VERSION ""

NS_ :

BS_:

BU_:

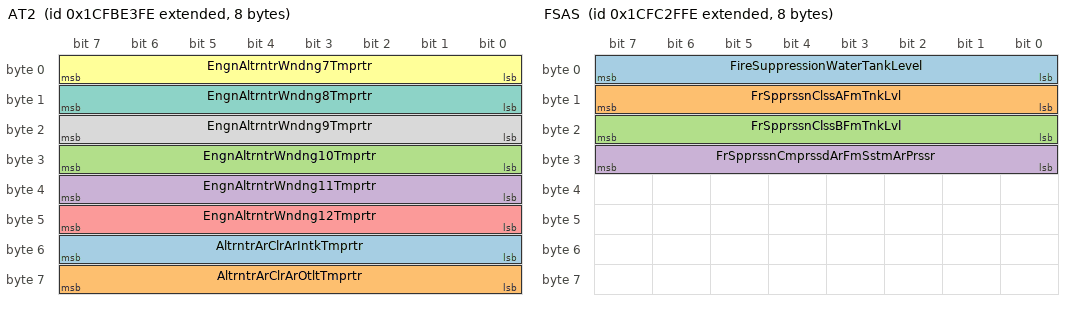
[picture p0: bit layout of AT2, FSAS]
BO_ 2633753598 AT2: 8 Vector__XXX
 SG_ AltrntrArClrArIntkTmprtr : 48|8@1+ (1,-40) [-40|210] "degC" Vector__XXX
 SG_ AltrntrArClrArOtltTmprtr : 56|8@1+ (1,-40) [-40|210] "degC" Vector__XXX
 SG_ EngnAltrntrWndng10Tmprtr : 24|8@1+ (1,-40) [-40|210] "degC" Vector__XXX
 SG_ EngnAltrntrWndng11Tmprtr : 32|8@1+ (1,-40) [-40|210] "degC" Vector__XXX
 SG_ EngnAltrntrWndng12Tmprtr : 40|8@1+ (1,-40) [-40|210] "degC" Vector__XXX
 SG_ EngnAltrntrWndng7Tmprtr : 0|8@1+ (1,-40) [-40|210] "degC" Vector__XXX
 SG_ EngnAltrntrWndng8Tmprtr : 8|8@1+ (1,-40) [-40|210] "degC" Vector__XXX
 SG_ EngnAltrntrWndng9Tmprtr : 16|8@1+ (1,-40) [-40|210] "degC" Vector__XXX

BO_ 2633754622 SCROII5: 8 Vector__XXX
 SG_ Aftrtrtmnt1SCRIntkHghTmprtrTm : 0|32@1+ (1,0) [0|4.21108E+09] "s" Vector__XXX
 SG_ SCROptIdtEOvdTtAtvtT : 32|32@1+ (1,0) [0|4.21108E+09] "s" Vector__XXX

BO_ 2633754878 ASI2: 8 Vector__XXX
 SG_ AftrtrtmntTtlDslExhstFldUsd : 0|32@1+ (0.5,0) [0|2105540607.5] "l" Vector__XXX

BO_ 2633755390 E1NET1: 19 Vector__XXX
 SG_ DefaultGatewayOctet1 : 72|8@1+ (1,0) [0|255] "count" Vector__XXX
 SG_ DefaultGatewayOctet2 : 80|8@1+ (1,0) [0|255] "count" Vector__XXX
 SG_ DefaultGatewayOctet3 : 88|8@1+ (1,0) [0|255] "count" Vector__XXX
 SG_ DefaultGatewayOctet4 : 96|8@1+ (1,0) [0|255] "count" Vector__XXX
 SG_ DHCPStatus : 0|4@1+ (1,0) [0|15] "" Vector__XXX
 SG_ EthernetLinkStatus : 4|2@1+ (1,0) [0|3] "" Vector__XXX
 SG_ IPv4AddressOctet1 : 8|8@1+ (1,0) [0|255] "count" Vector__XXX
 SG_ IPv4AddressOctet2 : 16|8@1+ (1,0) [0|255] "count" Vector__XXX
 SG_ IPv4AddressOctet3 : 24|8@1+ (1,0) [0|255] "count" Vector__XXX
 SG_ IPv4AddressOctet4 : 32|8@1+ (1,0) [0|255] "count" Vector__XXX
 SG_ MACAddressOctet1 : 104|8@1+ (1,0) [0|255] "count" Vector__XXX
 SG_ MACAddressOctet2 : 112|8@1+ (1,0) [0|255] "count" Vector__XXX
 SG_ MACAddressOctet3 : 120|8@1+ (1,0) [0|255] "count" Vector__XXX
 SG_ MACAddressOctet4 : 128|8@1+ (1,0) [0|255] "count" Vector__XXX
 SG_ MACAddressOctet5 : 136|8@1+ (1,0) [0|255] "count" Vector__XXX
 SG_ MACAddressOctet6 : 144|8@1+ (1,0) [0|255] "count" Vector__XXX
 SG_ SubnetMaskOctet1 : 40|8@1+ (1,0) [0|255] "count" Vector__XXX
 SG_ SubnetMaskOctet2 : 48|8@1+ (1,0) [0|255] "count" Vector__XXX
 SG_ SubnetMaskOctet3 : 56|8@1+ (1,0) [0|255] "count" Vector__XXX
 SG_ SubnetMaskOctet4 : 64|8@1+ (1,0) [0|255] "count" Vector__XXX

BO_ 2633764094 EVAP: 4 Vector__XXX
 SG_ CanisterPurgeValveCommand : 8|8@1+ (0.4,0) [0|100] "%" Vector__XXX
 SG_ CanisterVentValve : 0|2@1+ (1,0) [0|3] "" Vector__XXX
 SG_ GasolineFuelTankPressure : 16|16@1+ (0.1,-3212.7) [-3212.7|3212.8] "kPa" Vector__XXX

BO_ 2633764350 FPS1: 8 Vector__XXX
 SG_ FirePumpEngagementCycles : 32|16@1+ (1,0) [0|64255] "count" Vector__XXX
 SG_ FirePumpOperationTime : 0|32@1+ (1,0) [0|4.21108E+09] "s" Vector__XXX

BO_ 2633769726 EEC19: 8 Vector__XXX
 SG_ EngnExhstFlwRtExtnddRng : 32|32@1+ (0.001,0) [0|4211081.215] "kg/h" Vector__XXX
 SG_ TotalEngineEnergy : 0|32@1+ (1,0) [0|4.21108E+09] "kWh" Vector__XXX

BO_ 2633773054 FSAS: 8 Vector__XXX
 SG_ FireSuppressionWaterTankLevel : 0|8@1+ (0.4,0) [0|100] "%" Vector__XXX
 SG_ FrSpprssnClssAFmTnkLvl : 8|8@1+ (0.4,0) [0|100] "%" Vector__XXX
 SG_ FrSpprssnClssBFmTnkLvl : 16|8@1+ (0.4,0) [0|100] "%" Vector__XXX
 SG_ FrSpprssnCmprssdArFmSstmArPrssr : 24|8@1+ (8,0) [0|2000] "kPa" Vector__XXX

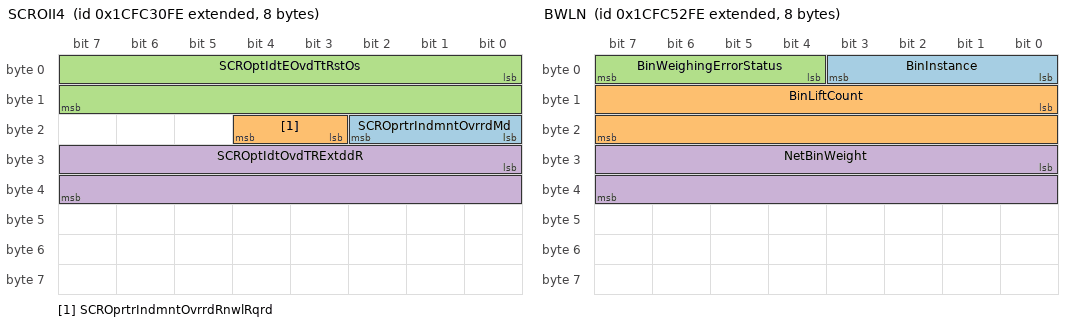
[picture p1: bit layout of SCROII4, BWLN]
BO_ 2633773310 SCROII4: 8 Vector__XXX
 SG_ SCROprtrIndmntOvrrdMd : 16|3@1+ (1,0) [0|7] "" Vector__XXX
 SG_ SCROprtrIndmntOvrrdRnwlRqrd : 19|2@1+ (1,0) [0|3] "" Vector__XXX
 SG_ SCROptIdtEOvdTtRstOs : 0|16@1+ (1,0) [0|64255] "count" Vector__XXX
 SG_ SCROptIdtOvdTRExtddR : 24|16@1+ (1,0) [0|64255] "min" Vector__XXX

BO_ 2633782014 BWLN: 8 Vector__XXX
 SG_ BinInstance : 0|4@1+ (1,0) [0|15] "count" Vector__XXX
 SG_ BinLiftCount : 8|16@1+ (1,0) [0|64255] "count" Vector__XXX
 SG_ BinWeighingErrorStatus : 4|4@1+ (1,0) [0|15] "" Vector__XXX
 SG_ NetBinWeight : 24|16@1+ (2,0) [0|128510] "kg" Vector__XXX

BO_ 2633785086 HVES1HIST: 11 Vector__XXX
 SG_ HVES1CnttrOpnUndrLdCnt : 8|16@1+ (1,0) [0|64255] "count" Vector__XXX
 SG_ HVES1StateofHealth : 0|8@1+ (0.4,0) [0|100] "%" Vector__XXX
 SG_ HVES1TotalAccumulatedCharge : 56|32@1+ (100,0) [0|4E+11] "Ah" Vector__XXX
 SG_ HVES1TotalEnergyThroughput : 24|32@1+ (100,0) [0|4E+11] "Watt-hour" Vector__XXX

BO_ 2633801982 MFEH: 8 Vector__XXX
 SG_ EngnTtlHrsfDslFlOprtn : 32|32@1+ (0.05,0) [0|210554060.75] "h" Vector__XXX
 SG_ EngnTtlHrsfGssFlOprtn : 0|32@1+ (0.05,0) [0|210554060.75] "h" Vector__XXX

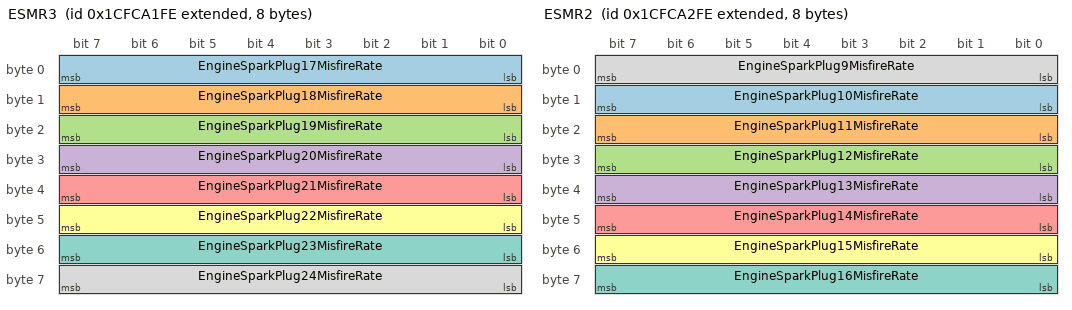
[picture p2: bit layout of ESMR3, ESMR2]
BO_ 2633802238 ESMR3: 8 Vector__XXX
 SG_ EngineSparkPlug17MisfireRate : 0|8@1+ (0.4,0) [0|100] "%" Vector__XXX
 SG_ EngineSparkPlug18MisfireRate : 8|8@1+ (0.4,0) [0|100] "%" Vector__XXX
 SG_ EngineSparkPlug19MisfireRate : 16|8@1+ (0.4,0) [0|100] "%" Vector__XXX
 SG_ EngineSparkPlug20MisfireRate : 24|8@1+ (0.4,0) [0|100] "%" Vector__XXX
 SG_ EngineSparkPlug21MisfireRate : 32|8@1+ (0.4,0) [0|100] "%" Vector__XXX
 SG_ EngineSparkPlug22MisfireRate : 40|8@1+ (0.4,0) [0|100] "%" Vector__XXX
 SG_ EngineSparkPlug23MisfireRate : 48|8@1+ (0.4,0) [0|100] "%" Vector__XXX
 SG_ EngineSparkPlug24MisfireRate : 56|8@1+ (0.4,0) [0|100] "%" Vector__XXX

BO_ 2633802494 ESMR2: 8 Vector__XXX
 SG_ EngineSparkPlug10MisfireRate : 8|8@1+ (0.4,0) [0|100] "%" Vector__XXX
 SG_ EngineSparkPlug11MisfireRate : 16|8@1+ (0.4,0) [0|100] "%" Vector__XXX
 SG_ EngineSparkPlug12MisfireRate : 24|8@1+ (0.4,0) [0|100] "%" Vector__XXX
 SG_ EngineSparkPlug13MisfireRate : 32|8@1+ (0.4,0) [0|100] "%" Vector__XXX
 SG_ EngineSparkPlug14MisfireRate : 40|8@1+ (0.4,0) [0|100] "%" Vector__XXX
 SG_ EngineSparkPlug15MisfireRate : 48|8@1+ (0.4,0) [0|100] "%" Vector__XXX
 SG_ EngineSparkPlug16MisfireRate : 56|8@1+ (0.4,0) [0|100] "%" Vector__XXX
 SG_ EngineSparkPlug9MisfireRate : 0|8@1+ (0.4,0) [0|100] "%" Vector__XXX

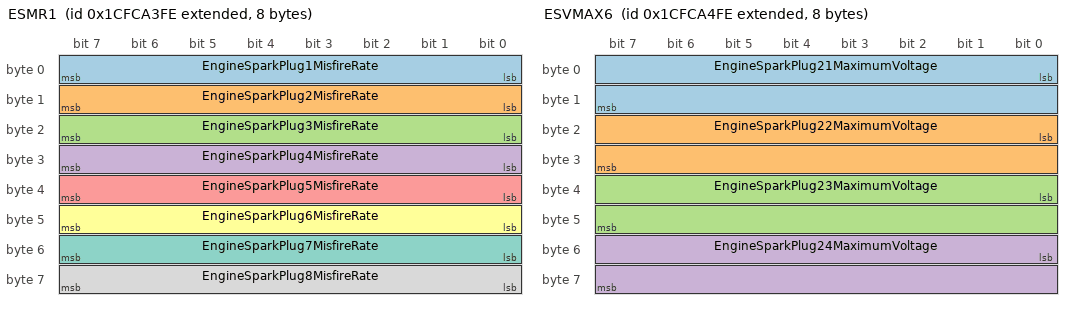
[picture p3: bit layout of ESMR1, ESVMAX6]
BO_ 2633802750 ESMR1: 8 Vector__XXX
 SG_ EngineSparkPlug1MisfireRate : 0|8@1+ (0.4,0) [0|100] "%" Vector__XXX
 SG_ EngineSparkPlug2MisfireRate : 8|8@1+ (0.4,0) [0|100] "%" Vector__XXX
 SG_ EngineSparkPlug3MisfireRate : 16|8@1+ (0.4,0) [0|100] "%" Vector__XXX
 SG_ EngineSparkPlug4MisfireRate : 24|8@1+ (0.4,0) [0|100] "%" Vector__XXX
 SG_ EngineSparkPlug5MisfireRate : 32|8@1+ (0.4,0) [0|100] "%" Vector__XXX
 SG_ EngineSparkPlug6MisfireRate : 40|8@1+ (0.4,0) [0|100] "%" Vector__XXX
 SG_ EngineSparkPlug7MisfireRate : 48|8@1+ (0.4,0) [0|100] "%" Vector__XXX
 SG_ EngineSparkPlug8MisfireRate : 56|8@1+ (0.4,0) [0|100] "%" Vector__XXX

BO_ 2633803006 ESVMAX6: 8 Vector__XXX
 SG_ EngineSparkPlug21MaximumVoltage : 0|16@1+ (1,0) [0|64255] "V" Vector__XXX
 SG_ EngineSparkPlug22MaximumVoltage : 16|16@1+ (1,0) [0|64255] "V" Vector__XXX
 SG_ EngineSparkPlug23MaximumVoltage : 32|16@1+ (1,0) [0|64255] "V" Vector__XXX
 SG_ EngineSparkPlug24MaximumVoltage : 48|16@1+ (1,0) [0|64255] "V" Vector__XXX

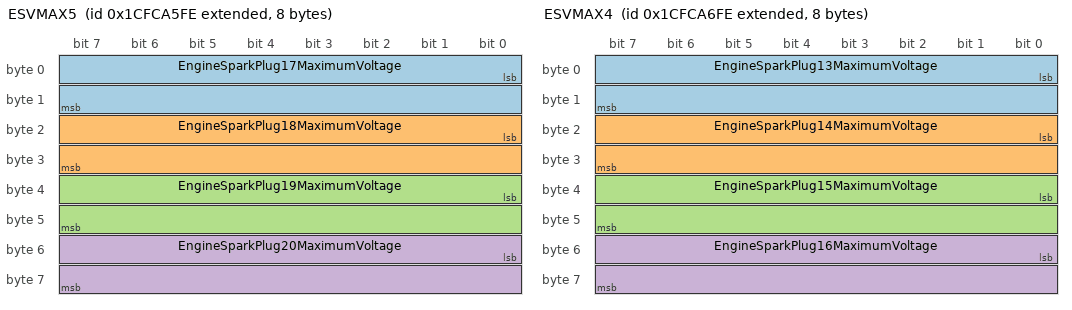
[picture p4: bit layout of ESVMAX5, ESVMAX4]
BO_ 2633803262 ESVMAX5: 8 Vector__XXX
 SG_ EngineSparkPlug17MaximumVoltage : 0|16@1+ (1,0) [0|64255] "V" Vector__XXX
 SG_ EngineSparkPlug18MaximumVoltage : 16|16@1+ (1,0) [0|64255] "V" Vector__XXX
 SG_ EngineSparkPlug19MaximumVoltage : 32|16@1+ (1,0) [0|64255] "V" Vector__XXX
 SG_ EngineSparkPlug20MaximumVoltage : 48|16@1+ (1,0) [0|64255] "V" Vector__XXX

BO_ 2633803518 ESVMAX4: 8 Vector__XXX
 SG_ EngineSparkPlug13MaximumVoltage : 0|16@1+ (1,0) [0|64255] "V" Vector__XXX
 SG_ EngineSparkPlug14MaximumVoltage : 16|16@1+ (1,0) [0|64255] "V" Vector__XXX
 SG_ EngineSparkPlug15MaximumVoltage : 32|16@1+ (1,0) [0|64255] "V" Vector__XXX
 SG_ EngineSparkPlug16MaximumVoltage : 48|16@1+ (1,0) [0|64255] "V" Vector__XXX

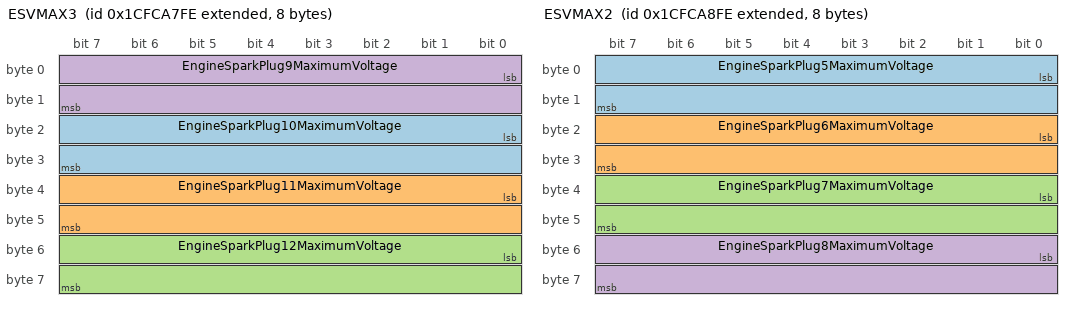
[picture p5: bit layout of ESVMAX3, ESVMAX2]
BO_ 2633803774 ESVMAX3: 8 Vector__XXX
 SG_ EngineSparkPlug10MaximumVoltage : 16|16@1+ (1,0) [0|64255] "V" Vector__XXX
 SG_ EngineSparkPlug11MaximumVoltage : 32|16@1+ (1,0) [0|64255] "V" Vector__XXX
 SG_ EngineSparkPlug12MaximumVoltage : 48|16@1+ (1,0) [0|64255] "V" Vector__XXX
 SG_ EngineSparkPlug9MaximumVoltage : 0|16@1+ (1,0) [0|64255] "V" Vector__XXX

BO_ 2633804030 ESVMAX2: 8 Vector__XXX
 SG_ EngineSparkPlug5MaximumVoltage : 0|16@1+ (1,0) [0|64255] "V" Vector__XXX
 SG_ EngineSparkPlug6MaximumVoltage : 16|16@1+ (1,0) [0|64255] "V" Vector__XXX
 SG_ EngineSparkPlug7MaximumVoltage : 32|16@1+ (1,0) [0|64255] "V" Vector__XXX
 SG_ EngineSparkPlug8MaximumVoltage : 48|16@1+ (1,0) [0|64255] "V" Vector__XXX

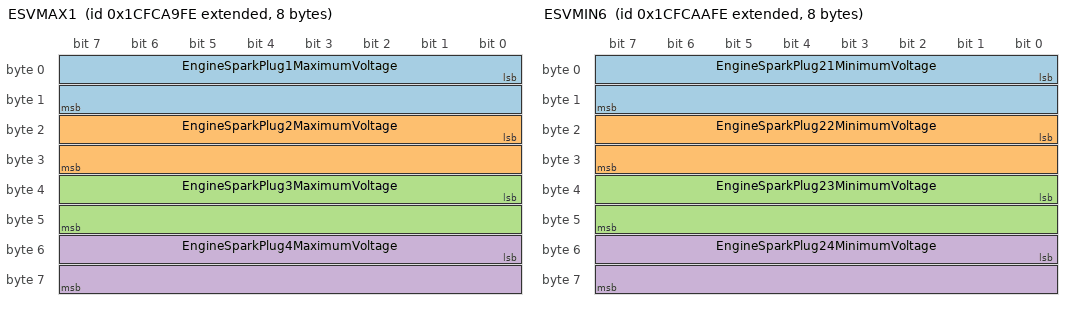
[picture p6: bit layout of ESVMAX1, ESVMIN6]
BO_ 2633804286 ESVMAX1: 8 Vector__XXX
 SG_ EngineSparkPlug1MaximumVoltage : 0|16@1+ (1,0) [0|64255] "V" Vector__XXX
 SG_ EngineSparkPlug2MaximumVoltage : 16|16@1+ (1,0) [0|64255] "V" Vector__XXX
 SG_ EngineSparkPlug3MaximumVoltage : 32|16@1+ (1,0) [0|64255] "V" Vector__XXX
 SG_ EngineSparkPlug4MaximumVoltage : 48|16@1+ (1,0) [0|64255] "V" Vector__XXX

BO_ 2633804542 ESVMIN6: 8 Vector__XXX
 SG_ EngineSparkPlug21MinimumVoltage : 0|16@1+ (1,0) [0|64255] "V" Vector__XXX
 SG_ EngineSparkPlug22MinimumVoltage : 16|16@1+ (1,0) [0|64255] "V" Vector__XXX
 SG_ EngineSparkPlug23MinimumVoltage : 32|16@1+ (1,0) [0|64255] "V" Vector__XXX
 SG_ EngineSparkPlug24MinimumVoltage : 48|16@1+ (1,0) [0|64255] "V" Vector__XXX

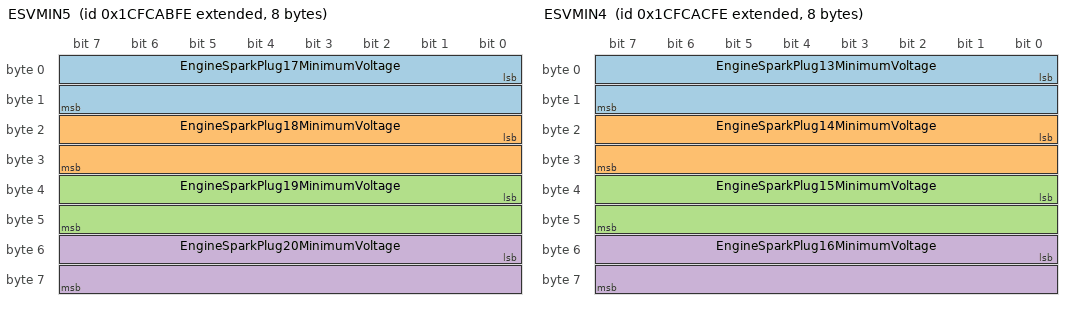
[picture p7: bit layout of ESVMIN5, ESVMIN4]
BO_ 2633804798 ESVMIN5: 8 Vector__XXX
 SG_ EngineSparkPlug17MinimumVoltage : 0|16@1+ (1,0) [0|64255] "V" Vector__XXX
 SG_ EngineSparkPlug18MinimumVoltage : 16|16@1+ (1,0) [0|64255] "V" Vector__XXX
 SG_ EngineSparkPlug19MinimumVoltage : 32|16@1+ (1,0) [0|64255] "V" Vector__XXX
 SG_ EngineSparkPlug20MinimumVoltage : 48|16@1+ (1,0) [0|64255] "V" Vector__XXX

BO_ 2633805054 ESVMIN4: 8 Vector__XXX
 SG_ EngineSparkPlug13MinimumVoltage : 0|16@1+ (1,0) [0|64255] "V" Vector__XXX
 SG_ EngineSparkPlug14MinimumVoltage : 16|16@1+ (1,0) [0|64255] "V" Vector__XXX
 SG_ EngineSparkPlug15MinimumVoltage : 32|16@1+ (1,0) [0|64255] "V" Vector__XXX
 SG_ EngineSparkPlug16MinimumVoltage : 48|16@1+ (1,0) [0|64255] "V" Vector__XXX

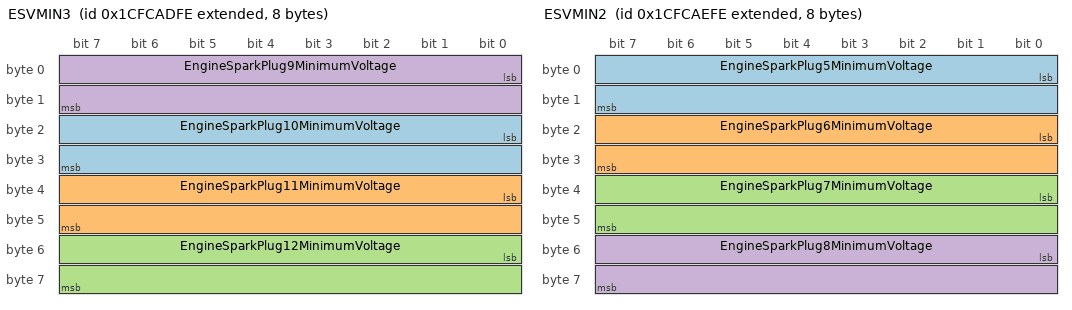
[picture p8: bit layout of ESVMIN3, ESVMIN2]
BO_ 2633805310 ESVMIN3: 8 Vector__XXX
 SG_ EngineSparkPlug10MinimumVoltage : 16|16@1+ (1,0) [0|64255] "V" Vector__XXX
 SG_ EngineSparkPlug11MinimumVoltage : 32|16@1+ (1,0) [0|64255] "V" Vector__XXX
 SG_ EngineSparkPlug12MinimumVoltage : 48|16@1+ (1,0) [0|64255] "V" Vector__XXX
 SG_ EngineSparkPlug9MinimumVoltage : 0|16@1+ (1,0) [0|64255] "V" Vector__XXX

BO_ 2633805566 ESVMIN2: 8 Vector__XXX
 SG_ EngineSparkPlug5MinimumVoltage : 0|16@1+ (1,0) [0|64255] "V" Vector__XXX
 SG_ EngineSparkPlug6MinimumVoltage : 16|16@1+ (1,0) [0|64255] "V" Vector__XXX
 SG_ EngineSparkPlug7MinimumVoltage : 32|16@1+ (1,0) [0|64255] "V" Vector__XXX
 SG_ EngineSparkPlug8MinimumVoltage : 48|16@1+ (1,0) [0|64255] "V" Vector__XXX

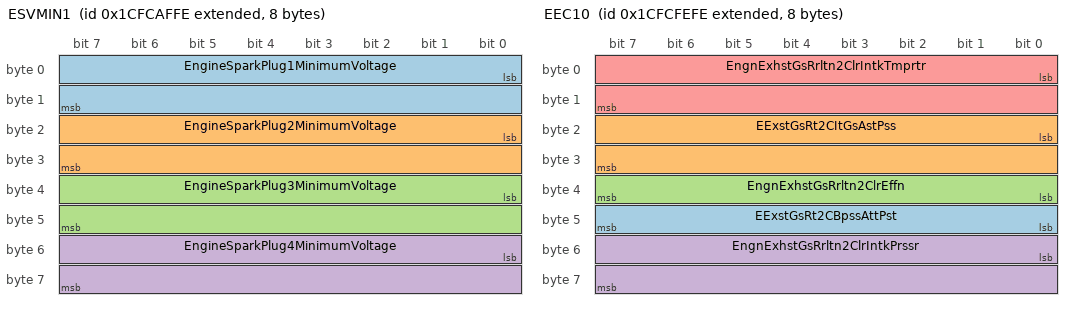
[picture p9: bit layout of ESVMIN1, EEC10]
BO_ 2633805822 ESVMIN1: 8 Vector__XXX
 SG_ EngineSparkPlug1MinimumVoltage : 0|16@1+ (1,0) [0|64255] "V" Vector__XXX
 SG_ EngineSparkPlug2MinimumVoltage : 16|16@1+ (1,0) [0|64255] "V" Vector__XXX
 SG_ EngineSparkPlug3MinimumVoltage : 32|16@1+ (1,0) [0|64255] "V" Vector__XXX
 SG_ EngineSparkPlug4MinimumVoltage : 48|16@1+ (1,0) [0|64255] "V" Vector__XXX

BO_ 2633806078 EICMH: 8 Vector__XXX
 SG_ EngnIgntnCntrlMdl1TmRmnng : 0|32@1+ (0.05,0) [0|210554060.75] "h" Vector__XXX
 SG_ EngnIgntnCntrlMdl2TmRmnng : 32|32@1+ (0.05,0) [0|210554060.75] "h" Vector__XXX

BO_ 2633825022 EEC11: 8 Vector__XXX
 SG_ EngnExhstGsRrltn2Vlv1Cntrl : 0|16@1+ (0.0025,0) [0|160.6375] "%" Vector__XXX
 SG_ EngnExhstGsRrltn2Vlv1PstnErrr : 32|16@1+ (0.004,-125) [-125|132.02] "%" Vector__XXX
 SG_ EngnExhstGsRrltn2Vlv2Cntrl : 16|16@1+ (0.0025,0) [0|160.6375] "%" Vector__XXX
 SG_ EngnExhstGsRrltn2Vlv2PstnErrr : 48|16@1+ (0.004,-125) [-125|132.02] "%" Vector__XXX

BO_ 2633825534 EMAC: 8 Vector__XXX
 SG_ EExstMdB1FwBVvAttCt : 0|16@1+ (0.0025,0) [0|160.6375] "%" Vector__XXX
 SG_ EExstMdB2FwBVvAttCt : 16|16@1+ (0.0025,0) [0|160.6375] "%" Vector__XXX

BO_ 2633826046 EEC10: 8 Vector__XXX
 SG_ EExstGsRt2CBpssAttPst : 40|8@1+ (0.4,0) [0|100] "%" Vector__XXX
 SG_ EExstGsRt2CItGsAstPss : 16|16@1+ (0.5,0) [0|32127.5] "kPa" Vector__XXX
 SG_ EngnExhstGsRrltn2ClrEffn : 32|8@1+ (0.4,0) [0|100] "%" Vector__XXX
 SG_ EngnExhstGsRrltn2ClrIntkPrssr : 48|16@1+ (5,0) [0|321275] "kPa" Vector__XXX
 SG_ EngnExhstGsRrltn2ClrIntkTmprtr : 0|16@1+ (0.03125,-273) [-273|1734.96875] "degC" Vector__XXX

BO_ 2633828606 EOM: 8 Vector__XXX
 SG_ EngineOilDensity : 16|16@1+ (0.00003052,0) [0|1.961] "g/cc" Vector__XXX
 SG_ EngineOilTemperature3 : 48|16@1+ (0.03125,-273) [-273|1734.96875] "degC" Vector__XXX
 SG_ EngineOilViscosity : 0|16@1+ (0.015625,0) [0|1003.984375] "Cp" Vector__XXX
 SG_ EngnOlRltvDltrtHghRsltn : 32|16@1+ (0.0001220703125,0) [0|7.844] "" Vector__XXX

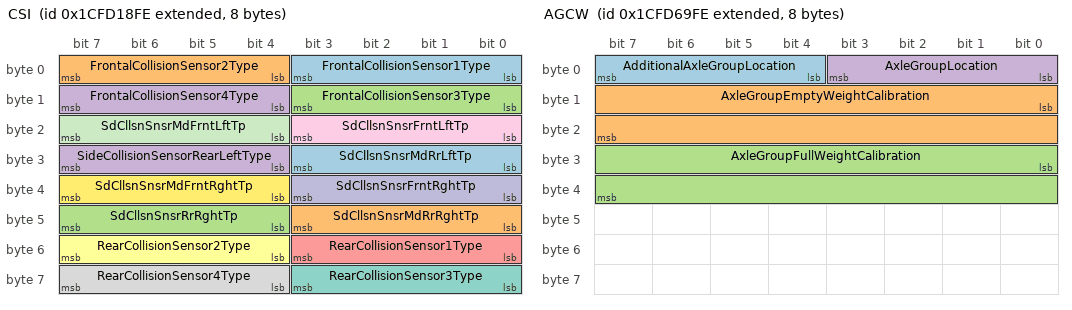
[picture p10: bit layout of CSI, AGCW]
BO_ 2633832702 CSI: 8 Vector__XXX
 SG_ FrontalCollisionSensor1Type : 0|4@1+ (1,0) [0|15] "" Vector__XXX
 SG_ FrontalCollisionSensor2Type : 4|4@1+ (1,0) [0|15] "" Vector__XXX
 SG_ FrontalCollisionSensor3Type : 8|4@1+ (1,0) [0|15] "" Vector__XXX
 SG_ FrontalCollisionSensor4Type : 12|4@1+ (1,0) [0|15] "" Vector__XXX
 SG_ RearCollisionSensor1Type : 48|4@1+ (1,0) [0|15] "" Vector__XXX
 SG_ RearCollisionSensor2Type : 52|4@1+ (1,0) [0|15] "" Vector__XXX
 SG_ RearCollisionSensor3Type : 56|4@1+ (1,0) [0|15] "" Vector__XXX
 SG_ RearCollisionSensor4Type : 60|4@1+ (1,0) [0|15] "" Vector__XXX
 SG_ SdCllsnSnsrFrntLftTp : 16|4@1+ (1,0) [0|15] "" Vector__XXX
 SG_ SdCllsnSnsrFrntRghtTp : 32|4@1+ (1,0) [0|15] "" Vector__XXX
 SG_ SdCllsnSnsrMdFrntLftTp : 20|4@1+ (1,0) [0|15] "" Vector__XXX
 SG_ SdCllsnSnsrMdFrntRghtTp : 36|4@1+ (1,0) [0|15] "" Vector__XXX
 SG_ SdCllsnSnsrMdRrLftTp : 24|4@1+ (1,0) [0|15] "" Vector__XXX
 SG_ SdCllsnSnsrMdRrRghtTp : 40|4@1+ (1,0) [0|15] "" Vector__XXX
 SG_ SdCllsnSnsrRrRghtTp : 44|4@1+ (1,0) [0|15] "" Vector__XXX
 SG_ SideCollisionSensorRearLeftType : 28|4@1+ (1,0) [0|15] "" Vector__XXX

BO_ 2633832958 ILI: 200 Vector__XXX
 SG_ DrvrArgIgntrLp1stStgRsstn : 0|16@1+ (0.1,0) [0|6425.5] "ohm" Vector__XXX
 SG_ DrvrArgIgntrLp2ndStgRsstn : 32|16@1+ (0.1,0) [0|6425.5] "ohm" Vector__XXX
 SG_ DrvrBltTnsnrIgntrLpRsstn : 64|16@1+ (0.1,0) [0|6425.5] "ohm" Vector__XXX
 SG_ PssngrArgIgntrLp1stStgRsstn : 16|16@1+ (0.1,0) [0|6425.5] "ohm" Vector__XXX
 SG_ PssngrArgIgntrLp2ndStgRsstn : 48|16@1+ (0.1,0) [0|6425.5] "ohm" Vector__XXX
 SG_ PssngrBltTnsnrIgntrLpRsstn : 80|16@1+ (0.1,0) [0|6425.5] "ohm" Vector__XXX
 SG_ SdBgIgntrLp1LftRsstn : 96|16@1+ (0.1,0) [0|6425.5] "ohm" Vector__XXX
 SG_ SdBgIgntrLp1RghtRsstn : 128|16@1+ (0.1,0) [0|6425.5] "ohm" Vector__XXX
 SG_ SdBgIgntrLp2LftRsstn : 112|16@1+ (0.1,0) [0|6425.5] "ohm" Vector__XXX
 SG_ SdBgIgntrLp2RghtRsstn : 144|16@1+ (0.1,0) [0|6425.5] "ohm" Vector__XXX
 SG_ SpecialIgnitorLoop10Resistance : 304|16@1+ (0.1,0) [0|6425.5] "ohm" Vector__XXX
 SG_ SpecialIgnitorLoop11Resistance : 320|16@1+ (0.1,0) [0|6425.5] "ohm" Vector__XXX
 SG_ SpecialIgnitorLoop12Resistance : 336|16@1+ (0.1,0) [0|6425.5] "ohm" Vector__XXX
 SG_ SpecialIgnitorLoop13Resistance : 352|16@1+ (0.1,0) [0|6425.5] "ohm" Vector__XXX
 SG_ SpecialIgnitorLoop14Resistance : 368|16@1+ (0.1,0) [0|6425.5] "ohm" Vector__XXX
 SG_ SpecialIgnitorLoop15Resistance : 384|16@1+ (0.1,0) [0|6425.5] "ohm" Vector__XXX
 SG_ SpecialIgnitorLoop16Resistance : 400|16@1+ (0.1,0) [0|6425.5] "ohm" Vector__XXX
 SG_ SpecialIgnitorLoop17Resistance : 416|16@1+ (0.1,0) [0|6425.5] "ohm" Vector__XXX
 SG_ SpecialIgnitorLoop18Resistance : 432|16@1+ (0.1,0) [0|6425.5] "ohm" Vector__XXX
 SG_ SpecialIgnitorLoop19Resistance : 448|16@1+ (0.1,0) [0|6425.5] "ohm" Vector__XXX
 SG_ SpecialIgnitorLoop1Resistance : 160|16@1+ (0.1,0) [0|6425.5] "ohm" Vector__XXX
 SG_ SpecialIgnitorLoop20Resistance : 464|16@1+ (0.1,0) [0|6425.5] "ohm" Vector__XXX
 SG_ SpecialIgnitorLoop21Resistance : 480|16@1+ (0.1,0) [0|6425.5] "ohm" Vector__XXX
 SG_ SpecialIgnitorLoop22Resistance : 496|16@1+ (0.1,0) [0|6425.5] "ohm" Vector__XXX
 SG_ SpecialIgnitorLoop23Resistance : 512|16@1+ (0.1,0) [0|6425.5] "ohm" Vector__XXX
 SG_ SpecialIgnitorLoop24Resistance : 528|16@1+ (0.1,0) [0|6425.5] "ohm" Vector__XXX
 SG_ SpecialIgnitorLoop25Resistance : 544|16@1+ (0.1,0) [0|6425.5] "ohm" Vector__XXX
 SG_ SpecialIgnitorLoop26Resistance : 560|16@1+ (0.1,0) [0|6425.5] "ohm" Vector__XXX
 SG_ SpecialIgnitorLoop27Resistance : 576|16@1+ (0.1,0) [0|6425.5] "ohm" Vector__XXX
 SG_ SpecialIgnitorLoop28Resistance : 592|16@1+ (0.1,0) [0|6425.5] "ohm" Vector__XXX
 SG_ SpecialIgnitorLoop29Resistance : 608|16@1+ (0.1,0) [0|6425.5] "ohm" Vector__XXX
 SG_ SpecialIgnitorLoop2Resistance : 176|16@1+ (0.1,0) [0|6425.5] "ohm" Vector__XXX
 SG_ SpecialIgnitorLoop30Resistance : 624|16@1+ (0.1,0) [0|6425.5] "ohm" Vector__XXX
 SG_ SpecialIgnitorLoop31Resistance : 640|16@1+ (0.1,0) [0|6425.5] "ohm" Vector__XXX
 SG_ SpecialIgnitorLoop32Resistance : 656|16@1+ (0.1,0) [0|6425.5] "ohm" Vector__XXX
 SG_ SpecialIgnitorLoop33Resistance : 672|16@1+ (0.1,0) [0|6425.5] "ohm" Vector__XXX
 SG_ SpecialIgnitorLoop34Resistance : 688|16@1+ (0.1,0) [0|6425.5] "ohm" Vector__XXX
 SG_ SpecialIgnitorLoop35Resistance : 704|16@1+ (0.1,0) [0|6425.5] "ohm" Vector__XXX
 SG_ SpecialIgnitorLoop36Resistance : 720|16@1+ (0.1,0) [0|6425.5] "ohm" Vector__XXX
 SG_ SpecialIgnitorLoop37Resistance : 736|16@1+ (0.1,0) [0|6425.5] "ohm" Vector__XXX
 SG_ SpecialIgnitorLoop38Resistance : 752|16@1+ (0.1,0) [0|6425.5] "ohm" Vector__XXX
 SG_ SpecialIgnitorLoop39Resistance : 768|16@1+ (0.1,0) [0|6425.5] "ohm" Vector__XXX
 SG_ SpecialIgnitorLoop3Resistance : 192|16@1+ (0.1,0) [0|6425.5] "ohm" Vector__XXX
 SG_ SpecialIgnitorLoop40Resistance : 784|16@1+ (0.1,0) [0|6425.5] "ohm" Vector__XXX
 SG_ SpecialIgnitorLoop41Resistance : 800|16@1+ (0.1,0) [0|6425.5] "ohm" Vector__XXX
 SG_ SpecialIgnitorLoop42Resistance : 816|16@1+ (0.1,0) [0|6425.5] "ohm" Vector__XXX
 SG_ SpecialIgnitorLoop43Resistance : 832|16@1+ (0.1,0) [0|6425.5] "ohm" Vector__XXX
 SG_ SpecialIgnitorLoop44Resistance : 848|16@1+ (0.1,0) [0|6425.5] "ohm" Vector__XXX
 SG_ SpecialIgnitorLoop45Resistance : 864|16@1+ (0.1,0) [0|6425.5] "ohm" Vector__XXX
 SG_ SpecialIgnitorLoop46Resistance : 880|16@1+ (0.1,0) [0|6425.5] "ohm" Vector__XXX
 SG_ SpecialIgnitorLoop47Resistance : 896|16@1+ (0.1,0) [0|6425.5] "ohm" Vector__XXX
 SG_ SpecialIgnitorLoop48Resistance : 912|16@1+ (0.1,0) [0|6425.5] "ohm" Vector__XXX
 SG_ SpecialIgnitorLoop49Resistance : 928|16@1+ (0.1,0) [0|6425.5] "ohm" Vector__XXX
 SG_ SpecialIgnitorLoop4Resistance : 208|16@1+ (0.1,0) [0|6425.5] "ohm" Vector__XXX
 SG_ SpecialIgnitorLoop50Resistance : 944|16@1+ (0.1,0) [0|6425.5] "ohm" Vector__XXX
 SG_ SpecialIgnitorLoop51Resistance : 960|16@1+ (0.1,0) [0|6425.5] "ohm" Vector__XXX
 SG_ SpecialIgnitorLoop52Resistance : 976|16@1+ (0.1,0) [0|6425.5] "ohm" Vector__XXX
 SG_ SpecialIgnitorLoop53Resistance : 992|16@1+ (0.1,0) [0|6425.5] "ohm" Vector__XXX
 SG_ SpecialIgnitorLoop54Resistance : 1008|16@1+ (0.1,0) [0|6425.5] "ohm" Vector__XXX
 SG_ SpecialIgnitorLoop55Resistance : 1024|16@1+ (0.1,0) [0|6425.5] "ohm" Vector__XXX
 SG_ SpecialIgnitorLoop56Resistance : 1040|16@1+ (0.1,0) [0|6425.5] "ohm" Vector__XXX
 SG_ SpecialIgnitorLoop57Resistance : 1056|16@1+ (0.1,0) [0|6425.5] "ohm" Vector__XXX
 SG_ SpecialIgnitorLoop58Resistance : 1072|16@1+ (0.1,0) [0|6425.5] "ohm" Vector__XXX
 SG_ SpecialIgnitorLoop59Resistance : 1088|16@1+ (0.1,0) [0|6425.5] "ohm" Vector__XXX
 SG_ SpecialIgnitorLoop5Resistance : 224|16@1+ (0.1,0) [0|6425.5] "ohm" Vector__XXX
 SG_ SpecialIgnitorLoop60Resistance : 1104|16@1+ (0.1,0) [0|6425.5] "ohm" Vector__XXX
 SG_ SpecialIgnitorLoop61Resistance : 1120|16@1+ (0.1,0) [0|6425.5] "ohm" Vector__XXX
 SG_ SpecialIgnitorLoop62Resistance : 1136|16@1+ (0.1,0) [0|6425.5] "ohm" Vector__XXX
 SG_ SpecialIgnitorLoop63Resistance : 1152|16@1+ (0.1,0) [0|6425.5] "ohm" Vector__XXX
 SG_ SpecialIgnitorLoop64Resistance : 1168|16@1+ (0.1,0) [0|6425.5] "ohm" Vector__XXX
 SG_ SpecialIgnitorLoop65Resistance : 1184|16@1+ (0.1,0) [0|6425.5] "ohm" Vector__XXX
 SG_ SpecialIgnitorLoop66Resistance : 1200|16@1+ (0.1,0) [0|6425.5] "ohm" Vector__XXX
 SG_ SpecialIgnitorLoop67Resistance : 1216|16@1+ (0.1,0) [0|6425.5] "ohm" Vector__XXX
 SG_ SpecialIgnitorLoop68Resistance : 1232|16@1+ (0.1,0) [0|6425.5] "ohm" Vector__XXX
 SG_ SpecialIgnitorLoop69Resistance : 1248|16@1+ (0.1,0) [0|6425.5] "ohm" Vector__XXX
 SG_ SpecialIgnitorLoop6Resistance : 240|16@1+ (0.1,0) [0|6425.5] "ohm" Vector__XXX
 SG_ SpecialIgnitorLoop70Resistance : 1264|16@1+ (0.1,0) [0|6425.5] "ohm" Vector__XXX
 SG_ SpecialIgnitorLoop71Resistance : 1280|16@1+ (0.1,0) [0|6425.5] "ohm" Vector__XXX
 SG_ SpecialIgnitorLoop72Resistance : 1296|16@1+ (0.1,0) [0|6425.5] "ohm" Vector__XXX
 SG_ SpecialIgnitorLoop73Resistance : 1312|16@1+ (0.1,0) [0|6425.5] "ohm" Vector__XXX
 SG_ SpecialIgnitorLoop74Resistance : 1328|16@1+ (0.1,0) [0|6425.5] "ohm" Vector__XXX
 SG_ SpecialIgnitorLoop75Resistance : 1344|16@1+ (0.1,0) [0|6425.5] "ohm" Vector__XXX
 SG_ SpecialIgnitorLoop76Resistance : 1360|16@1+ (0.1,0) [0|6425.5] "ohm" Vector__XXX
 SG_ SpecialIgnitorLoop77Resistance : 1376|16@1+ (0.1,0) [0|6425.5] "ohm" Vector__XXX
 SG_ SpecialIgnitorLoop78Resistance : 1392|16@1+ (0.1,0) [0|6425.5] "ohm" Vector__XXX
 SG_ SpecialIgnitorLoop79Resistance : 1408|16@1+ (0.1,0) [0|6425.5] "ohm" Vector__XXX
 SG_ SpecialIgnitorLoop7Resistance : 256|16@1+ (0.1,0) [0|6425.5] "ohm" Vector__XXX
 SG_ SpecialIgnitorLoop80Resistance : 1424|16@1+ (0.1,0) [0|6425.5] "ohm" Vector__XXX
 SG_ SpecialIgnitorLoop81Resistance : 1440|16@1+ (0.1,0) [0|6425.5] "ohm" Vector__XXX
 SG_ SpecialIgnitorLoop82Resistance : 1456|16@1+ (0.1,0) [0|6425.5] "ohm" Vector__XXX
 SG_ SpecialIgnitorLoop83Resistance : 1472|16@1+ (0.1,0) [0|6425.5] "ohm" Vector__XXX
 SG_ SpecialIgnitorLoop84Resistance : 1488|16@1+ (0.1,0) [0|6425.5] "ohm" Vector__XXX
 SG_ SpecialIgnitorLoop85Resistance : 1504|16@1+ (0.1,0) [0|6425.5] "ohm" Vector__XXX
 SG_ SpecialIgnitorLoop86Resistance : 1520|16@1+ (0.1,0) [0|6425.5] "ohm" Vector__XXX
 SG_ SpecialIgnitorLoop87Resistance : 1536|16@1+ (0.1,0) [0|6425.5] "ohm" Vector__XXX
 SG_ SpecialIgnitorLoop88Resistance : 1552|16@1+ (0.1,0) [0|6425.5] "ohm" Vector__XXX
 SG_ SpecialIgnitorLoop89Resistance : 1568|16@1+ (0.1,0) [0|6425.5] "ohm" Vector__XXX
 SG_ SpecialIgnitorLoop8Resistance : 272|16@1+ (0.1,0) [0|6425.5] "ohm" Vector__XXX
 SG_ SpecialIgnitorLoop90Resistance : 1584|16@1+ (0.1,0) [0|6425.5] "ohm" Vector__XXX
 SG_ SpecialIgnitorLoop9Resistance : 288|16@1+ (0.1,0) [0|6425.5] "ohm" Vector__XXX

BO_ 2633853438 AGCW: 8 Vector__XXX
 SG_ AdditionalAxleGroupLocation : 4|4@1+ (1,0) [0|15] "" Vector__XXX
 SG_ AxleGroupEmptyWeightCalibration : 8|16@1+ (2,0) [0|128510] "kg" Vector__XXX
 SG_ AxleGroupFullWeightCalibration : 24|16@1+ (2,0) [0|128510] "kg" Vector__XXX
 SG_ AxleGroupLocation : 0|4@1+ (1,0) [0|15] "" Vector__XXX

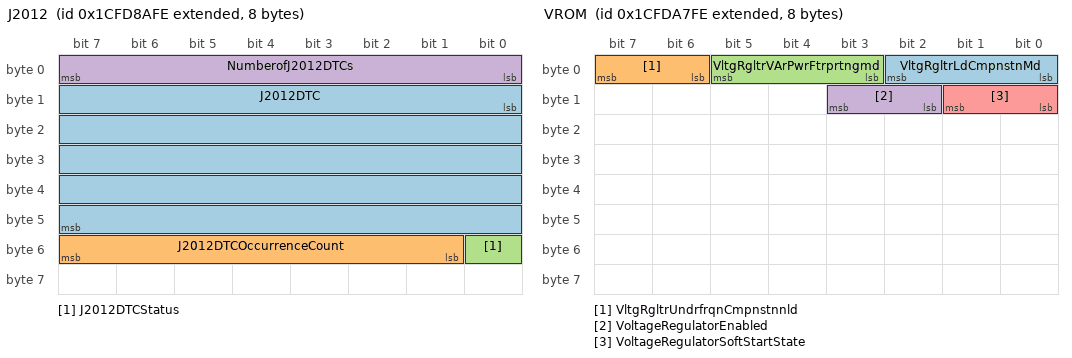
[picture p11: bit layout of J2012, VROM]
BO_ 2633861886 J2012: 8 Vector__XXX
 SG_ J2012DTC : 8|40@1+ (1,0) [0|255] "ASCII" Vector__XXX
 SG_ J2012DTCOccurrenceCount : 49|7@1+ (1,0) [0|127] "count" Vector__XXX
 SG_ J2012DTCStatus : 48|1@1+ (1,0) [0|1] "" Vector__XXX
 SG_ NumberofJ2012DTCs : 0|8@1+ (1,0) [0|250] "count" Vector__XXX

BO_ 2633869310 VROM: 8 Vector__XXX
 SG_ VltgRgltrLdCmpnstnMd : 0|3@1+ (1,0) [0|7] "" Vector__XXX
 SG_ VltgRgltrUndrfrqnCmpnstnnld : 6|2@1+ (1,0) [0|3] "" Vector__XXX
 SG_ VltgRgltrVArPwrFtrprtngmd : 3|3@1+ (1,0) [0|7] "" Vector__XXX
 SG_ VoltageRegulatorEnabled : 10|2@1+ (1,0) [0|3] "" Vector__XXX
 SG_ VoltageRegulatorSoftStartState : 8|2@1+ (1,0) [0|3] "" Vector__XXX

BO_ 2633878014 CMI: 8 Vector__XXX
 SG_ TtlCntfCnfgrtnChngsMd : 0|16@1+ (1,0) [0|64255] "count" Vector__XXX

BO_ 2633880062 FMS: 8 Vector__XXX
 SG_ FMSstandardDiagnosticsSupported : 0|2@1+ (1,0) [0|3] "" Vector__XXX
 SG_ FMSstandardRequestsSupported : 2|2@1+ (1,0) [0|3] "" Vector__XXX
 SG_ FMSstandardSWversionsupported : 8|32@1+ (1,0) [0|255] "ASCII" Vector__XXX

BO_ 2633883646 FWD: 8 Vector__XXX
 SG_ FrontWheelDriveActuatorStatus : 0|2@1+ (1,0) [0|3] "" Vector__XXX

BO_ 2633911806 TAVG: 8 Vector__XXX
 SG_ EngineTotalAverageFuelEconomy : 16|16@1+ (0.001953125,0) [0|125.498046875] "km/L" Vector__XXX
 SG_ EngineTotalAverageFuelRate : 0|16@1+ (0.05,0) [0|3212.75] "l/h" Vector__XXX

BO_ 2633922558 AP: 8 Vector__XXX
 SG_ AuxiliaryGagePressureReading1 : 16|16@1+ (0.5,0) [0|32127.5] "kPa" Vector__XXX
 SG_ AuxiliaryVacuumPressureReading : 0|16@1+ (0.5,0) [0|32127.5] "kPa" Vector__XXX
 SG_ AxlrAsltPrssrRdng : 32|16@1+ (0.5,0) [0|32127.5] "kPa" Vector__XXX

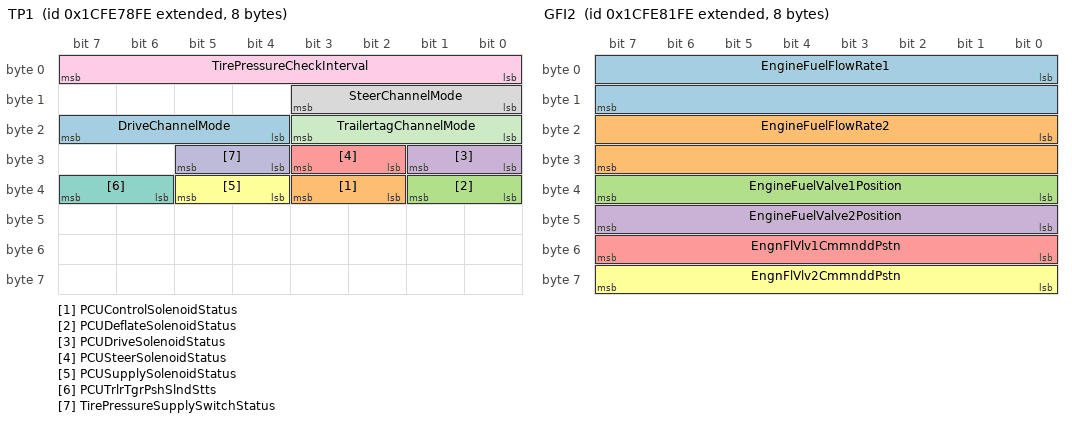
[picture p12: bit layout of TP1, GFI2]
BO_ 2633922814 TP1: 8 Vector__XXX
 SG_ DriveChannelMode : 20|4@1+ (1,0) [0|15] "" Vector__XXX
 SG_ PCUControlSolenoidStatus : 34|2@1+ (1,0) [0|3] "" Vector__XXX
 SG_ PCUDeflateSolenoidStatus : 32|2@1+ (1,0) [0|3] "" Vector__XXX
 SG_ PCUDriveSolenoidStatus : 24|2@1+ (1,0) [0|3] "" Vector__XXX
 SG_ PCUSteerSolenoidStatus : 26|2@1+ (1,0) [0|3] "" Vector__XXX
 SG_ PCUSupplySolenoidStatus : 36|2@1+ (1,0) [0|3] "" Vector__XXX
 SG_ PCUTrlrTgrPshSlndStts : 38|2@1+ (1,0) [0|3] "" Vector__XXX
 SG_ SteerChannelMode : 8|4@1+ (1,0) [0|15] "" Vector__XXX
 SG_ TirePressureCheckInterval : 0|8@1+ (1,0) [0|250] "min" Vector__XXX
 SG_ TirePressureSupplySwitchStatus : 28|2@1+ (1,0) [0|3] "" Vector__XXX
 SG_ TrailertagChannelMode : 16|4@1+ (1,0) [0|15] "" Vector__XXX

BO_ 2633923070 TP2: 8 Vector__XXX
 SG_ DriveChannelTirePressureTarget : 16|16@1+ (0.5,0) [0|32127.5] "kPa" Vector__XXX
 SG_ SteerChannelTirePressureTarget : 32|16@1+ (0.5,0) [0|32127.5] "kPa" Vector__XXX
 SG_ TrlrTgOrPshChnnlTrPrssrTrgt : 0|16@1+ (0.5,0) [0|32127.5] "kPa" Vector__XXX

BO_ 2633923326 TP3: 8 Vector__XXX
 SG_ DriveChannelTirePressure : 16|16@1+ (0.5,0) [0|32127.5] "kPa" Vector__XXX
 SG_ SteerChannelTirePressure : 32|16@1+ (0.5,0) [0|32127.5] "kPa" Vector__XXX
 SG_ TrlrTgOrPshChnnlTrPrssr : 0|16@1+ (0.5,0) [0|32127.5] "kPa" Vector__XXX

BO_ 2633923582 CT1: 8 Vector__XXX
 SG_ EngineCylinder1CombustionTime : 0|16@1+ (0.01,0) [0|642.55] "ms" Vector__XXX
 SG_ EngineCylinder2CombustionTime : 16|16@1+ (0.01,0) [0|642.55] "ms" Vector__XXX
 SG_ EngineCylinder3CombustionTime : 32|16@1+ (0.01,0) [0|642.55] "ms" Vector__XXX
 SG_ EngineCylinder4CombustionTime : 48|16@1+ (0.01,0) [0|642.55] "ms" Vector__XXX

BO_ 2633923838 CT2: 8 Vector__XXX
 SG_ EngineCylinder5CombustionTime : 0|16@1+ (0.01,0) [0|642.55] "ms" Vector__XXX
 SG_ EngineCylinder6CombustionTime : 16|16@1+ (0.01,0) [0|642.55] "ms" Vector__XXX
 SG_ EngineCylinder7CombustionTime : 32|16@1+ (0.01,0) [0|642.55] "ms" Vector__XXX
 SG_ EngineCylinder8CombustionTime : 48|16@1+ (0.01,0) [0|642.55] "ms" Vector__XXX

BO_ 2633924094 CT3: 8 Vector__XXX
 SG_ EngineCylinder10CombustionTime : 16|16@1+ (0.01,0) [0|642.55] "ms" Vector__XXX
 SG_ EngineCylinder11CombustionTime : 32|16@1+ (0.01,0) [0|642.55] "ms" Vector__XXX
 SG_ EngineCylinder12CombustionTime : 48|16@1+ (0.01,0) [0|642.55] "ms" Vector__XXX
 SG_ EngineCylinder9CombustionTime : 0|16@1+ (0.01,0) [0|642.55] "ms" Vector__XXX

BO_ 2633924350 CT4: 8 Vector__XXX
 SG_ EngineCylinder13CombustionTime : 0|16@1+ (0.01,0) [0|642.55] "ms" Vector__XXX
 SG_ EngineCylinder14CombustionTime : 16|16@1+ (0.01,0) [0|642.55] "ms" Vector__XXX
 SG_ EngineCylinder15CombustionTime : 32|16@1+ (0.01,0) [0|642.55] "ms" Vector__XXX
 SG_ EngineCylinder16CombustionTime : 48|16@1+ (0.01,0) [0|642.55] "ms" Vector__XXX

BO_ 2633924606 CT5: 8 Vector__XXX
 SG_ EngineCylinder17CombustionTime : 0|16@1+ (0.01,0) [0|642.55] "ms" Vector__XXX
 SG_ EngineCylinder18CombustionTime : 16|16@1+ (0.01,0) [0|642.55] "ms" Vector__XXX
 SG_ EngineCylinder19CombustionTime : 32|16@1+ (0.01,0) [0|642.55] "ms" Vector__XXX
 SG_ EngineCylinder20CombustionTime : 48|16@1+ (0.01,0) [0|642.55] "ms" Vector__XXX

BO_ 2633924862 CT6: 8 Vector__XXX
 SG_ EngineAverageCombustionTime : 16|16@1+ (0.01,0) [0|642.55] "ms" Vector__XXX
 SG_ EngineDesiredCombustionTime : 0|16@1+ (0.01,0) [0|642.55] "ms" Vector__XXX

BO_ 2633925118 GFI2: 8 Vector__XXX
 SG_ EngineFuelFlowRate1 : 0|16@1+ (0.1,0) [0|6425.5] "(m*m*m)/h" Vector__XXX
 SG_ EngineFuelFlowRate2 : 16|16@1+ (0.1,0) [0|6425.5] "(m*m*m)/h" Vector__XXX
 SG_ EngineFuelValve1Position : 32|8@1+ (0.4,0) [0|100] "%" Vector__XXX
 SG_ EngineFuelValve2Position : 40|8@1+ (0.4,0) [0|100] "%" Vector__XXX
 SG_ EngnFlVlv1CmmnddPstn : 48|8@1+ (0.4,0) [0|100] "%" Vector__XXX
 SG_ EngnFlVlv2CmmnddPstn : 56|8@1+ (0.4,0) [0|100] "%" Vector__XXX

BO_ 2633925374 IT1: 8 Vector__XXX
 SG_ EngineCylinder1IgnitionTiming : 0|16@1+ (0.0078125,-200) [-200|301.99] "deg" Vector__XXX
 SG_ EngineCylinder2IgnitionTiming : 16|16@1+ (0.0078125,-200) [-200|301.99] "deg" Vector__XXX
 SG_ EngineCylinder3IgnitionTiming : 32|16@1+ (0.0078125,-200) [-200|301.99] "deg" Vector__XXX
 SG_ EngineCylinder4IgnitionTiming : 48|16@1+ (0.0078125,-200) [-200|301.99] "deg" Vector__XXX

BO_ 2633925630 IT2: 8 Vector__XXX
 SG_ EngineCylinder5IgnitionTiming : 0|16@1+ (0.0078125,-200) [-200|301.99] "deg" Vector__XXX
 SG_ EngineCylinder6IgnitionTiming : 16|16@1+ (0.0078125,-200) [-200|301.99] "deg" Vector__XXX
 SG_ EngineCylinder7IgnitionTiming : 32|16@1+ (0.0078125,-200) [-200|301.99] "deg" Vector__XXX
 SG_ EngineCylinder8IgnitionTiming : 48|16@1+ (0.0078125,-200) [-200|301.99] "deg" Vector__XXX

BO_ 2633925886 IT3: 8 Vector__XXX
 SG_ EngineCylinder10IgnitionTiming : 16|16@1+ (0.0078125,-200) [-200|301.99] "deg" Vector__XXX
 SG_ EngineCylinder11IgnitionTiming : 32|16@1+ (0.0078125,-200) [-200|301.99] "deg" Vector__XXX
 SG_ EngineCylinder12IgnitionTiming : 48|16@1+ (0.0078125,-200) [-200|301.99] "deg" Vector__XXX
 SG_ EngineCylinder9IgnitionTiming : 0|16@1+ (0.0078125,-200) [-200|301.99] "deg" Vector__XXX

BO_ 2633926142 IT4: 8 Vector__XXX
 SG_ EngineCylinder13IgnitionTiming : 0|16@1+ (0.0078125,-200) [-200|301.99] "deg" Vector__XXX
 SG_ EngineCylinder14IgnitionTiming : 16|16@1+ (0.0078125,-200) [-200|301.99] "deg" Vector__XXX
 SG_ EngineCylinder15IgnitionTiming : 32|16@1+ (0.0078125,-200) [-200|301.99] "deg" Vector__XXX
 SG_ EngineCylinder16IgnitionTiming : 48|16@1+ (0.0078125,-200) [-200|301.99] "deg" Vector__XXX

BO_ 2633926398 IT5: 8 Vector__XXX
 SG_ EngineCylinder17IgnitionTiming : 0|16@1+ (0.0078125,-200) [-200|301.99] "deg" Vector__XXX
 SG_ EngineCylinder18IgnitionTiming : 16|16@1+ (0.0078125,-200) [-200|301.99] "deg" Vector__XXX
 SG_ EngineCylinder19IgnitionTiming : 32|16@1+ (0.0078125,-200) [-200|301.99] "deg" Vector__XXX
 SG_ EngineCylinder20IgnitionTiming : 48|16@1+ (0.0078125,-200) [-200|301.99] "deg" Vector__XXX

BO_ 2633926654 IT6: 8 Vector__XXX
 SG_ EngineActualIgnitionTiming : 48|16@1+ (0.0078125,-200) [-200|301.99] "deg" Vector__XXX
 SG_ EngineDesiredIgnitionTiming1 : 0|16@1+ (0.0078125,-200) [-200|301.99] "deg" Vector__XXX
 SG_ EngineDesiredIgnitionTiming2 : 16|16@1+ (0.0078125,-200) [-200|301.99] "deg" Vector__XXX
 SG_ EngineDesiredIgnitionTiming3 : 32|16@1+ (0.0078125,-200) [-200|301.99] "deg" Vector__XXX

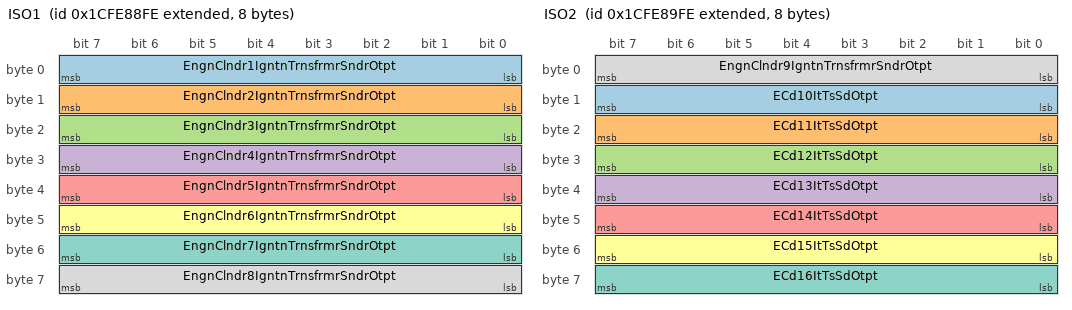
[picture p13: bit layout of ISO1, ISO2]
BO_ 2633926910 ISO1: 8 Vector__XXX
 SG_ EngnClndr1IgntnTrnsfrmrSndrOtpt : 0|8@1+ (1,-125) [-125|125] "%" Vector__XXX
 SG_ EngnClndr2IgntnTrnsfrmrSndrOtpt : 8|8@1+ (1,-125) [-125|125] "%" Vector__XXX
 SG_ EngnClndr3IgntnTrnsfrmrSndrOtpt : 16|8@1+ (1,-125) [-125|125] "%" Vector__XXX
 SG_ EngnClndr4IgntnTrnsfrmrSndrOtpt : 24|8@1+ (1,-125) [-125|125] "%" Vector__XXX
 SG_ EngnClndr5IgntnTrnsfrmrSndrOtpt : 32|8@1+ (1,-125) [-125|125] "%" Vector__XXX
 SG_ EngnClndr6IgntnTrnsfrmrSndrOtpt : 40|8@1+ (1,-125) [-125|125] "%" Vector__XXX
 SG_ EngnClndr7IgntnTrnsfrmrSndrOtpt : 48|8@1+ (1,-125) [-125|125] "%" Vector__XXX
 SG_ EngnClndr8IgntnTrnsfrmrSndrOtpt : 56|8@1+ (1,-125) [-125|125] "%" Vector__XXX

BO_ 2633927166 ISO2: 8 Vector__XXX
 SG_ ECd10ItTsSdOtpt : 8|8@1+ (1,-125) [-125|125] "%" Vector__XXX
 SG_ ECd11ItTsSdOtpt : 16|8@1+ (1,-125) [-125|125] "%" Vector__XXX
 SG_ ECd12ItTsSdOtpt : 24|8@1+ (1,-125) [-125|125] "%" Vector__XXX
 SG_ ECd13ItTsSdOtpt : 32|8@1+ (1,-125) [-125|125] "%" Vector__XXX
 SG_ ECd14ItTsSdOtpt : 40|8@1+ (1,-125) [-125|125] "%" Vector__XXX
 SG_ ECd15ItTsSdOtpt : 48|8@1+ (1,-125) [-125|125] "%" Vector__XXX
 SG_ ECd16ItTsSdOtpt : 56|8@1+ (1,-125) [-125|125] "%" Vector__XXX
 SG_ EngnClndr9IgntnTrnsfrmrSndrOtpt : 0|8@1+ (1,-125) [-125|125] "%" Vector__XXX

BO_ 2633927422 ISO3: 8 Vector__XXX
 SG_ ECd17ItTsSdOtpt : 0|8@1+ (1,-125) [-125|125] "%" Vector__XXX
 SG_ ECd18ItTsSdOtpt : 8|8@1+ (1,-125) [-125|125] "%" Vector__XXX
 SG_ ECd19ItTsSdOtpt : 16|8@1+ (1,-125) [-125|125] "%" Vector__XXX
 SG_ ECd20ItTsSdOtpt : 24|8@1+ (1,-125) [-125|125] "%" Vector__XXX

BO_ 2633927678 GFP1: 8 Vector__XXX
 SG_ EngnArtFlDffrntlPrssr : 32|16@1+ (0.1,0) [0|6425.5] "kPa" Vector__XXX
 SG_ EngnFlVlv1DffrntlPrssr : 16|16@1+ (0.1,0) [0|6425.5] "kPa" Vector__XXX
 SG_ EngnFlVlv1IntkAsltPrssr : 0|16@1+ (0.1,0) [0|6425.5] "kPa" Vector__XXX
 SG_ EngnFlVlv1OtltAsltPrssr : 48|16@1+ (0.1,0) [0|6425.5] "kPa" Vector__XXX

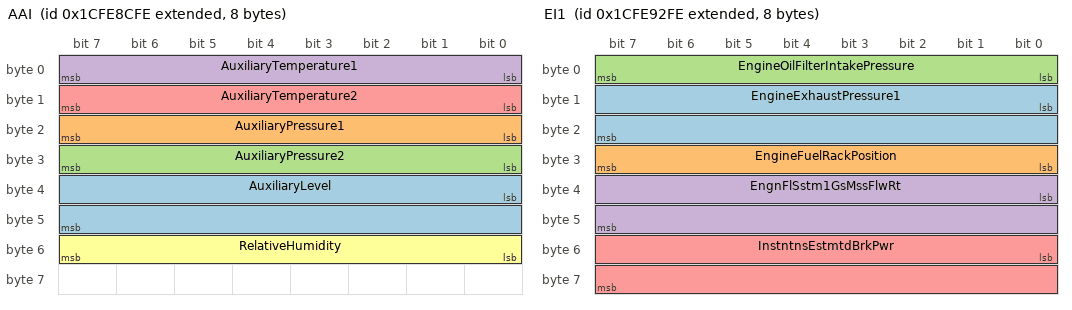
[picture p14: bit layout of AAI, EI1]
BO_ 2633927934 AAI: 8 Vector__XXX
 SG_ AuxiliaryLevel : 32|16@1+ (0.1,0) [0|6425.5] "mm" Vector__XXX
 SG_ AuxiliaryPressure1 : 16|8@1+ (16,0) [0|4000] "kPa" Vector__XXX
 SG_ AuxiliaryPressure2 : 24|8@1+ (16,0) [0|4000] "kPa" Vector__XXX
 SG_ AuxiliaryTemperature1 : 0|8@1+ (1,-40) [-40|210] "degC" Vector__XXX
 SG_ AuxiliaryTemperature2 : 8|8@1+ (1,-40) [-40|210] "degC" Vector__XXX
 SG_ RelativeHumidity : 48|8@1+ (0.4,0) [0|100] "%" Vector__XXX

BO_ 2633928446 S2: 8 Vector__XXX
 SG_ ServiceComponentIdentification : 0|8@1+ (1,0) [0|250] "ID" Vector__XXX
 SG_ TimeSinceLastService : 8|16@1+ (1,-32127) [-32127|32128] "h" Vector__XXX

BO_ 2633929214 FL: 8 Vector__XXX
 SG_ EngineFluidBundLevel : 8|8@1+ (0.4,0) [0|100] "%" Vector__XXX
 SG_ EngineFuelLeakage1 : 0|2@1+ (1,0) [0|3] "" Vector__XXX
 SG_ EngineFuelLeakage2 : 2|2@1+ (1,0) [0|3] "" Vector__XXX

BO_ 2633929470 EI1: 8 Vector__XXX
 SG_ EngineExhaustPressure1 : 8|16@1+ (0.0078125,-250) [-250|251.99] "kPa" Vector__XXX
 SG_ EngineFuelRackPosition : 24|8@1+ (0.4,0) [0|100] "%" Vector__XXX
 SG_ EngineOilFilterIntakePressure : 0|8@1+ (4,0) [0|1000] "kPa" Vector__XXX
 SG_ EngnFlSstm1GsMssFlwRt : 32|16@1+ (0.05,0) [0|3212.75] "kg/h" Vector__XXX
 SG_ InstntnsEstmtdBrkPwr : 48|16@1+ (0.5,0) [0|32127.5] "kW" Vector__XXX

BO_ 2633929726 EES: 8 Vector__XXX
 SG_ ElectricalLoad : 0|16@1+ (0.5,0) [0|32127.5] "kW" Vector__XXX
 SG_ EngineTurningGearEngaged : 18|2@1+ (1,0) [0|3] "" Vector__XXX
 SG_ SafetyWireStatus : 16|2@1+ (1,0) [0|3] "" Vector__XXX

BO_ 2633930238 RBI: 8 Vector__XXX
 SG_ EngineOperationTimeSinceRebuild : 0|32@1+ (1,0) [0|4.21108E+09] "s" Vector__XXX

BO_ 2633931774 TCI1: 8 Vector__XXX
 SG_ EngineTurbocharger2Speed : 8|16@1+ (4,0) [0|257020] "rpm" Vector__XXX
 SG_ EngineTurbocharger3Speed : 24|16@1+ (4,0) [0|257020] "rpm" Vector__XXX
 SG_ EngineTurbocharger4Speed : 40|16@1+ (4,0) [0|257020] "rpm" Vector__XXX
 SG_ EngnTrhrgrLOlPrssr2 : 0|8@1+ (4,0) [0|1000] "kPa" Vector__XXX

BO_ 2633932798 EPT5: 8 Vector__XXX
 SG_ EngnExhstGsPrt17Tmprtr : 0|16@1+ (0.03125,-273) [-273|1734.96875] "degC" Vector__XXX
 SG_ EngnExhstGsPrt18Tmprtr : 16|16@1+ (0.03125,-273) [-273|1734.96875] "degC" Vector__XXX
 SG_ EngnExhstGsPrt19Tmprtr : 32|16@1+ (0.03125,-273) [-273|1734.96875] "degC" Vector__XXX
 SG_ EngnExhstGsPrt20Tmprtr : 48|16@1+ (0.03125,-273) [-273|1734.96875] "degC" Vector__XXX

BO_ 2633933310 EPT3: 8 Vector__XXX
 SG_ EngnExhstGsPrt10Tmprtr : 16|16@1+ (0.03125,-273) [-273|1734.96875] "degC" Vector__XXX
 SG_ EngnExhstGsPrt11Tmprtr : 32|16@1+ (0.03125,-273) [-273|1734.96875] "degC" Vector__XXX
 SG_ EngnExhstGsPrt12Tmprtr : 48|16@1+ (0.03125,-273) [-273|1734.96875] "degC" Vector__XXX
 SG_ EngnExhstGsPrt9Tmprtr : 0|16@1+ (0.03125,-273) [-273|1734.96875] "degC" Vector__XXX

BO_ 2633933566 EPT2: 8 Vector__XXX
 SG_ EngnExhstGsPrt5Tmprtr : 0|16@1+ (0.03125,-273) [-273|1734.96875] "degC" Vector__XXX
 SG_ EngnExhstGsPrt6Tmprtr : 16|16@1+ (0.03125,-273) [-273|1734.96875] "degC" Vector__XXX
 SG_ EngnExhstGsPrt7Tmprtr : 32|16@1+ (0.03125,-273) [-273|1734.96875] "degC" Vector__XXX
 SG_ EngnExhstGsPrt8Tmprtr : 48|16@1+ (0.03125,-273) [-273|1734.96875] "degC" Vector__XXX

BO_ 2633933822 EPT1: 8 Vector__XXX
 SG_ EngnExhstGsPrt1Tmprtr : 0|16@1+ (0.03125,-273) [-273|1734.96875] "degC" Vector__XXX
 SG_ EngnExhstGsPrt2Tmprtr : 16|16@1+ (0.03125,-273) [-273|1734.96875] "degC" Vector__XXX
 SG_ EngnExhstGsPrt3Tmprtr : 32|16@1+ (0.03125,-273) [-273|1734.96875] "degC" Vector__XXX
 SG_ EngnExhstGsPrt4Tmprtr : 48|16@1+ (0.03125,-273) [-273|1734.96875] "degC" Vector__XXX

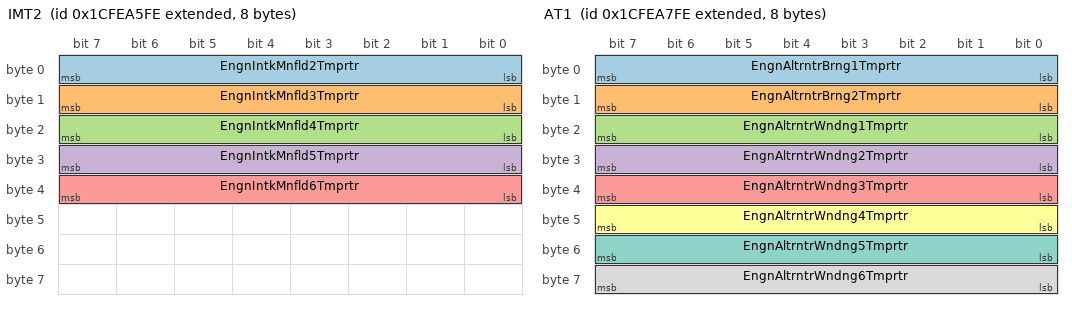
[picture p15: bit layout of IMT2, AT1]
BO_ 2633934334 IMT2: 8 Vector__XXX
 SG_ EngnIntkMnfld2Tmprtr : 0|8@1+ (1,-40) [-40|210] "degC" Vector__XXX
 SG_ EngnIntkMnfld3Tmprtr : 8|8@1+ (1,-40) [-40|210] "degC" Vector__XXX
 SG_ EngnIntkMnfld4Tmprtr : 16|8@1+ (1,-40) [-40|210] "degC" Vector__XXX
 SG_ EngnIntkMnfld5Tmprtr : 24|8@1+ (1,-40) [-40|210] "degC" Vector__XXX
 SG_ EngnIntkMnfld6Tmprtr : 32|8@1+ (1,-40) [-40|210] "degC" Vector__XXX

BO_ 2633934846 AT1: 8 Vector__XXX
 SG_ EngnAltrntrBrng1Tmprtr : 0|8@1+ (1,-40) [-40|210] "degC" Vector__XXX
 SG_ EngnAltrntrBrng2Tmprtr : 8|8@1+ (1,-40) [-40|210] "degC" Vector__XXX
 SG_ EngnAltrntrWndng1Tmprtr : 16|8@1+ (1,-40) [-40|210] "degC" Vector__XXX
 SG_ EngnAltrntrWndng2Tmprtr : 24|8@1+ (1,-40) [-40|210] "degC" Vector__XXX
 SG_ EngnAltrntrWndng3Tmprtr : 32|8@1+ (1,-40) [-40|210] "degC" Vector__XXX
 SG_ EngnAltrntrWndng4Tmprtr : 40|8@1+ (1,-40) [-40|210] "degC" Vector__XXX
 SG_ EngnAltrntrWndng5Tmprtr : 48|8@1+ (1,-40) [-40|210] "degC" Vector__XXX
 SG_ EngnAltrntrWndng6Tmprtr : 56|8@1+ (1,-40) [-40|210] "degC" Vector__XXX

BO_ 2633935102 ACTL: 8 Vector__XXX
 SG_ ArticulationAngle : 0|8@1+ (1,-125) [-125|125] "deg" Vector__XXX
 SG_ ArticulationAngularVelocity : 8|16@1+ (0.0078125,-250) [-250|250.992] "deg/s" Vector__XXX

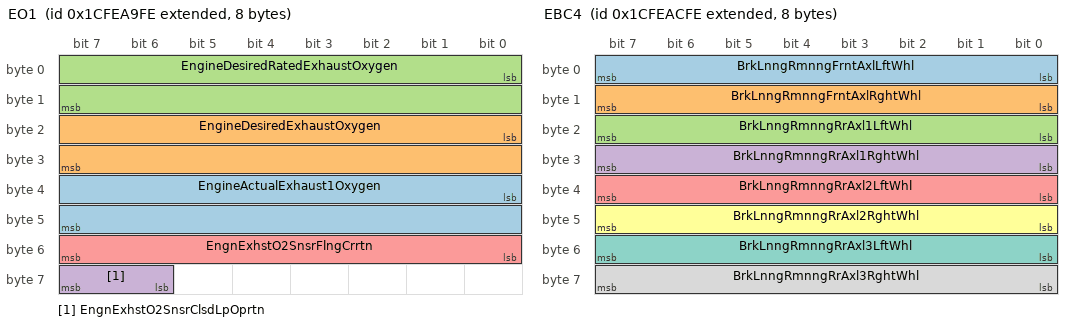
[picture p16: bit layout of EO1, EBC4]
BO_ 2633935358 EO1: 8 Vector__XXX
 SG_ EngineActualExhaust1Oxygen : 32|16@1+ (0.0025,0) [0|160.6375] "%" Vector__XXX
 SG_ EngineDesiredExhaustOxygen : 16|16@1+ (0.0025,0) [0|160.6375] "%" Vector__XXX
 SG_ EngineDesiredRatedExhaustOxygen : 0|16@1+ (0.0025,0) [0|160.6375] "%" Vector__XXX
 SG_ EngnExhstO2SnsrClsdLpOprtn : 62|2@1+ (1,0) [0|3] "" Vector__XXX
 SG_ EngnExhstO2SnsrFlngCrrtn : 48|8@1+ (1,-125) [-125|125] "%" Vector__XXX

BO_ 2633935614 AF2: 8 Vector__XXX
 SG_ EFSstGsMssFwRtSsFCt : 32|8@1+ (1,-125) [-125|125] "%" Vector__XXX
 SG_ EngnIntkMnfldDsrdAsltPrssr : 8|16@1+ (0.1,0) [0|6425.5] "kPa" Vector__XXX
 SG_ EngnTrhrgrWstgtVlvPstn : 24|8@1+ (0.4,0) [0|100] "%" Vector__XXX
 SG_ GaseousFuelCorrectionFactor : 0|8@1+ (1,0) [0|250] "%" Vector__XXX
 SG_ GssFlInjtnPlsCrrtnFtr : 40|16@1+ (0.0078125,-251) [-251|250.99] "%" Vector__XXX

BO_ 2633935870 ETC6: 8 Vector__XXX
 SG_ ClutchLifeRemaining : 24|8@1+ (0.4,0) [0|100] "%" Vector__XXX
 SG_ HighestPossibleGear : 8|8@1+ (1,-125) [-125|125] "gear value" Vector__XXX
 SG_ LowestPossibleGear : 16|8@1+ (1,-125) [-125|125] "gear value" Vector__XXX
 SG_ RecommendedGear : 0|8@1+ (1,-125) [-125|125] "gear value" Vector__XXX

BO_ 2633936126 EBC4: 8 Vector__XXX
 SG_ BrkLnngRmnngFrntAxlLftWhl : 0|8@1+ (0.4,0) [0|100] "%" Vector__XXX
 SG_ BrkLnngRmnngFrntAxlRghtWhl : 8|8@1+ (0.4,0) [0|100] "%" Vector__XXX
 SG_ BrkLnngRmnngRrAxl1LftWhl : 16|8@1+ (0.4,0) [0|100] "%" Vector__XXX
 SG_ BrkLnngRmnngRrAxl1RghtWhl : 24|8@1+ (0.4,0) [0|100] "%" Vector__XXX
 SG_ BrkLnngRmnngRrAxl2LftWhl : 32|8@1+ (0.4,0) [0|100] "%" Vector__XXX
 SG_ BrkLnngRmnngRrAxl2RghtWhl : 40|8@1+ (0.4,0) [0|100] "%" Vector__XXX
 SG_ BrkLnngRmnngRrAxl3LftWhl : 48|8@1+ (0.4,0) [0|100] "%" Vector__XXX
 SG_ BrkLnngRmnngRrAxl3RghtWhl : 56|8@1+ (0.4,0) [0|100] "%" Vector__XXX

BO_ 2633936894 GFC: 8 Vector__XXX
 SG_ TotalFuelUsedGaseous : 32|32@1+ (0.5,0) [0|2105540607.5] "kg" Vector__XXX
 SG_ TripFuelGaseous : 0|32@1+ (0.5,0) [0|2105540607.5] "kg" Vector__XXX

BO_ 2633937150 TTI2: 20 Vector__XXX
 SG_ TripAirCompressorOnTime : 128|32@1+ (0.05,0) [0|210554060.75] "h" Vector__XXX
 SG_ TripCruiseTime : 0|32@1+ (0.05,0) [0|210554060.75] "h" Vector__XXX
 SG_ TripEngineRunningTime : 64|32@1+ (0.05,0) [0|210554060.75] "h" Vector__XXX
 SG_ TripIdleTime : 96|32@1+ (0.05,0) [0|210554060.75] "h" Vector__XXX
 SG_ TripPTOGovernorTime : 32|32@1+ (0.05,0) [0|210554060.75] "h" Vector__XXX

BO_ 2633937406 EH: 8 Vector__XXX
 SG_ TotalECUDistance : 0|32@1+ (0.125,0) [0|526385151.875] "km" Vector__XXX
 SG_ TotalECURunTime : 32|32@1+ (0.05,0) [0|210554060.75] "h" Vector__XXX

BO_ 2633937662 GFI1: 8 Vector__XXX
 SG_ EngineFuelSpecificGravity : 48|16@1+ (0.0001,0) [0|6.4255] "" Vector__XXX
 SG_ TripAverageFuelRateGaseous : 32|16@1+ (0.05,0) [0|3212.75] "kg/h" Vector__XXX
 SG_ TtlEngnPTOGvrnrFlUsdGss : 0|32@1+ (0.5,0) [0|2105540607.5] "kg" Vector__XXX

BO_ 2633937918 LFI1: 8 Vector__XXX
 SG_ FlexibleFuelPercentage : 48|16@1+ (0.0025,0) [0|160.6375] "%" Vector__XXX
 SG_ TotalEnginePTOGovernorFuelUsed : 0|32@1+ (0.5,0) [0|2105540607.5] "l" Vector__XXX
 SG_ TripAverageFuelRate : 32|16@1+ (0.05,0) [0|3212.75] "l/h" Vector__XXX

BO_ 2633938174 TTI1: 16 Vector__XXX
 SG_ TripTimeinDeratebyEngine : 96|32@1+ (0.05,0) [0|210554060.75] "h" Vector__XXX
 SG_ TripTimeinGearDown : 64|32@1+ (0.05,0) [0|210554060.75] "h" Vector__XXX
 SG_ TripTimeinTopGear : 32|32@1+ (0.05,0) [0|210554060.75] "h" Vector__XXX
 SG_ TripTimeinVSL : 0|32@1+ (0.05,0) [0|210554060.75] "h" Vector__XXX

BO_ 2633938430 TSI: 8 Vector__XXX
 SG_ TripNumberofHotShutdowns : 0|16@1+ (1,0) [0|64255] "count" Vector__XXX
 SG_ TripNumberofIdleShutdowns : 16|16@1+ (1,0) [0|64255] "count" Vector__XXX
 SG_ TripSuddenDecelerations : 48|16@1+ (1,0) [0|64255] "count" Vector__XXX
 SG_ TrpNmrfIdlShtdwnOvrrds : 32|16@1+ (1,0) [0|64255] "count" Vector__XXX

BO_ 2633938686 TVI: 8 Vector__XXX
 SG_ TripCruiseDistance : 16|32@1+ (0.125,0) [0|526385151.875] "km" Vector__XXX
 SG_ TripMaximumVehicleSpeed : 0|16@1+ (0.00390625,0) [0|250.996] "km/h" Vector__XXX

BO_ 2633938942 LF: 10 Vector__XXX
 SG_ TotalDriveAverageLoadFactor : 40|8@1+ (0.4,0) [0|100] "%" Vector__XXX
 SG_ TotalEngineCruiseTime : 48|32@1+ (0.05,0) [0|210554060.75] "h" Vector__XXX
 SG_ TripAverageEngineSpeed : 16|16@1+ (0.125,0) [0|8031.875] "rpm" Vector__XXX
 SG_ TripDriveAverageLoadFactor : 32|8@1+ (0.4,0) [0|100] "%" Vector__XXX
 SG_ TripMaximumEngineSpeed : 0|16@1+ (0.125,0) [0|8031.875] "rpm" Vector__XXX

BO_ 2633939198 GTFI: 22 Vector__XXX
 SG_ TripCruiseFuelUsedGaseous : 128|32@1+ (0.5,0) [0|2105540607.5] "kg" Vector__XXX
 SG_ TripDriveFuelEconomyGaseous : 160|16@1+ (0.001953125,0) [0|125.498046875] "km/kg" Vector__XXX
 SG_ TripDriveFuelUsedGaseous : 0|32@1+ (0.5,0) [0|2105540607.5] "kg" Vector__XXX
 SG_ TripVehicleIdleFuelUsedGaseous : 96|32@1+ (0.5,0) [0|2105540607.5] "kg" Vector__XXX
 SG_ TrpPTOGvrnrMvngFlUsdGss : 32|32@1+ (0.5,0) [0|2105540607.5] "kg" Vector__XXX
 SG_ TrpPTOGvrnrNnmvngFlUsdGss : 64|32@1+ (0.5,0) [0|2105540607.5] "kg" Vector__XXX

BO_ 2633939454 LTFI: 22 Vector__XXX
 SG_ TripCruiseFuelUsed : 128|32@1+ (0.5,0) [0|2105540607.5] "l" Vector__XXX
 SG_ TripDriveFuelEconomy : 160|16@1+ (0.001953125,0) [0|125.498046875] "km/L" Vector__XXX
 SG_ TripDriveFuelUsed : 0|32@1+ (0.5,0) [0|2105540607.5] "l" Vector__XXX
 SG_ TripPTOGovernorMovingFuelUsed : 32|32@1+ (0.5,0) [0|2105540607.5] "l" Vector__XXX
 SG_ TripVehicleIdleFuelUsed : 96|32@1+ (0.5,0) [0|2105540607.5] "l" Vector__XXX
 SG_ TrpPTOGvrnrNnmvngFlUsd : 64|32@1+ (0.5,0) [0|2105540607.5] "l" Vector__XXX

BO_ 2633939710 TDI: 12 Vector__XXX
 SG_ TripDistanceinTopGear : 64|32@1+ (0.125,0) [0|526385151.875] "km" Vector__XXX
 SG_ TripDistanceonVSL : 0|32@1+ (0.125,0) [0|526385151.875] "km" Vector__XXX
 SG_ TripGearDownDistance : 32|32@1+ (0.125,0) [0|526385151.875] "km" Vector__XXX

BO_ 2633939966 TFI: 16 Vector__XXX
 SG_ TripFanOnTime : 0|32@1+ (0.05,0) [0|210554060.75] "h" Vector__XXX
 SG_ TripFanOnTimeDuetoaManualSwitch : 64|32@1+ (0.05,0) [0|210554060.75] "h" Vector__XXX
 SG_ TripFanOnTimeDuetotheACSystem : 96|32@1+ (0.05,0) [0|210554060.75] "h" Vector__XXX
 SG_ TrpFnOnTmDtthEngnSstm : 32|32@1+ (0.05,0) [0|210554060.75] "h" Vector__XXX

BO_ 2633940222 CBI: 16 Vector__XXX
 SG_ TotalCompressionBrakeDistance : 0|32@1+ (0.125,0) [0|526385151.875] "km" Vector__XXX
 SG_ TripCompressionBrakeDistance : 32|32@1+ (0.125,0) [0|526385151.875] "km" Vector__XXX
 SG_ TripServiceBrakeApplications : 96|32@1+ (1,0) [0|4.21108E+09] "brake appl" Vector__XXX
 SG_ TripServiceBrakeDistance : 64|32@1+ (0.125,0) [0|526385151.875] "km" Vector__XXX

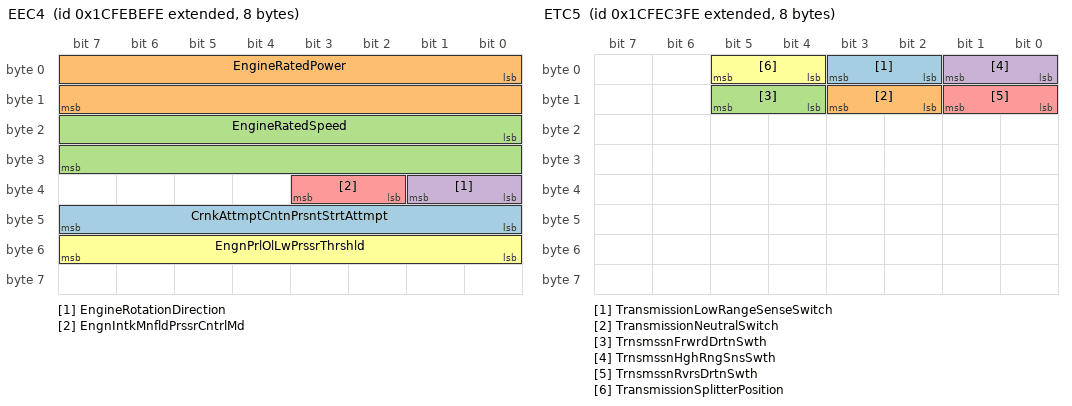
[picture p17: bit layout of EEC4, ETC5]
BO_ 2633940734 EEC4: 8 Vector__XXX
 SG_ CrnkAttmptCntnPrsntStrtAttmpt : 40|8@1+ (1,0) [0|250] "count" Vector__XXX
 SG_ EngineRatedPower : 0|16@1+ (0.5,0) [0|32127.5] "kW" Vector__XXX
 SG_ EngineRatedSpeed : 16|16@1+ (0.125,0) [0|8031.875] "rpm" Vector__XXX
 SG_ EngineRotationDirection : 32|2@1+ (1,0) [0|3] "" Vector__XXX
 SG_ EngnIntkMnfldPrssrCntrlMd : 34|2@1+ (1,0) [0|3] "" Vector__XXX
 SG_ EngnPrlOlLwPrssrThrshld : 48|8@1+ (4,0) [0|1000] "kPa" Vector__XXX

BO_ 2633941758 ERC2: 8 Vector__XXX
 SG_ CrsCntrlRtrdrAtvSpdOffst : 8|16@1+ (0.00390625,-125) [-125|125.996] "km/h" Vector__XXX
 SG_ TransmissionOutputRetarder : 0|2@1+ (1,0) [0|3] "" Vector__XXX

BO_ 2633942014 ETC5: 8 Vector__XXX
 SG_ TransmissionLowRangeSenseSwitch : 2|2@1+ (1,0) [0|3] "" Vector__XXX
 SG_ TransmissionNeutralSwitch : 10|2@1+ (1,0) [0|3] "" Vector__XXX
 SG_ TrnsmssnFrwrdDrtnSwth : 12|2@1+ (1,0) [0|3] "" Vector__XXX
 SG_ TrnsmssnHghRngSnsSwth : 0|2@1+ (1,0) [0|3] "" Vector__XXX
 SG_ TrnsmssnRvrsDrtnSwth : 8|2@1+ (1,0) [0|3] "" Vector__XXX
 SG_ TransmissionSplitterPosition : 4|2@1+ (1,0) [0|3] "" Vector__XXX

BO_ 2633942526 ETC4: 8 Vector__XXX
 SG_ TrnsmssnSnhrnzrBrkVl : 8|8@1+ (0.4,0) [0|100] "%" Vector__XXX
 SG_ TrnsmssnSnhrnzrClthVl : 0|8@1+ (0.4,0) [0|100] "%" Vector__XXX

BO_ 2633943038 ETC3: 8 Vector__XXX
 SG_ TransmissionClutchActuator : 40|2@1+ (1,0) [0|3] "" Vector__XXX
 SG_ TransmissionDefuelActuator : 44|2@1+ (1,0) [0|3] "" Vector__XXX
 SG_ TransmissionRangeHighActuator : 32|2@1+ (1,0) [0|3] "" Vector__XXX
 SG_ TransmissionRangeLowActuator : 34|2@1+ (1,0) [0|3] "" Vector__XXX
 SG_ TrnsmssnInrtBrkAttr : 46|2@1+ (1,0) [0|3] "" Vector__XXX
 SG_ TrnsmssnShftFngrCntrRlIndtr : 20|2@1+ (1,0) [0|3] "" Vector__XXX
 SG_ TrnsmssnShftFngrEnggmntIndtr : 18|2@1+ (1,0) [0|3] "" Vector__XXX
 SG_ TrnsmssnShftFngrGrAttr1 : 26|2@1+ (1,0) [0|3] "" Vector__XXX
 SG_ TrnsmssnShftFngrGrAttr2 : 30|2@1+ (1,0) [0|3] "" Vector__XXX
 SG_ TrnsmssnShftFngrGrPstn : 0|8@1+ (0.4,0) [0|100] "%" Vector__XXX
 SG_ TrnsmssnShftFngrNtrlIndtr : 16|2@1+ (1,0) [0|3] "" Vector__XXX
 SG_ TrnsmssnShftFngrRlAttr1 : 24|2@1+ (1,0) [0|3] "" Vector__XXX
 SG_ TrnsmssnShftFngrRlAttr2 : 28|2@1+ (1,0) [0|3] "" Vector__XXX
 SG_ TrnsmssnShftFngrRlPstn : 8|8@1+ (0.4,0) [0|100] "%" Vector__XXX
 SG_ TrnsmssnSplttrDrtAttr : 36|2@1+ (1,0) [0|3] "" Vector__XXX
 SG_ TrnsmssnSplttrIndrtAttr : 38|2@1+ (1,0) [0|3] "" Vector__XXX
 SG_ TrnsmssnTrqCnvrtrLkpClthAttr : 42|2@1+ (1,0) [0|3] "" Vector__XXX

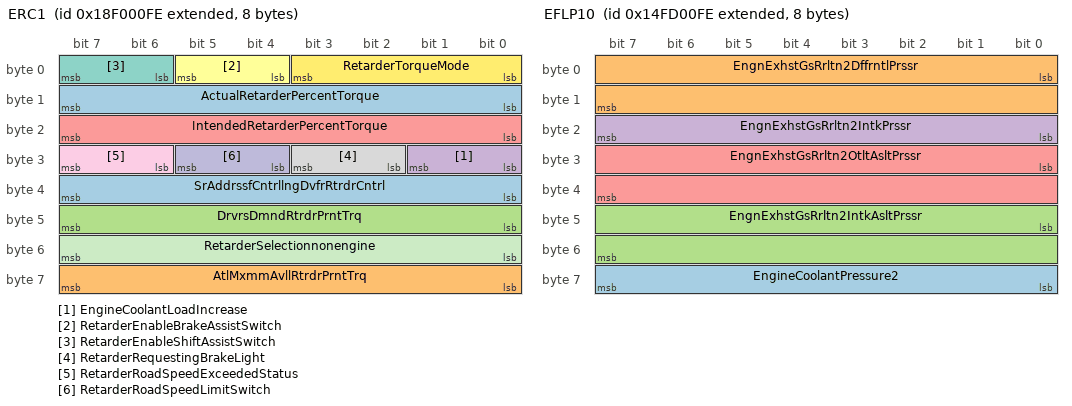
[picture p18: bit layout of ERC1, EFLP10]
BO_ 2565865726 ERC1: 8 Vector__XXX
 SG_ ActualRetarderPercentTorque : 8|8@1+ (1,-125) [-125|125] "%" Vector__XXX
 SG_ AtlMxmmAvllRtrdrPrntTrq : 56|8@1+ (1,-125) [-125|125] "%" Vector__XXX
 SG_ DrvrsDmndRtrdrPrntTrq : 40|8@1+ (1,-125) [-125|125] "%" Vector__XXX
 SG_ EngineCoolantLoadIncrease : 24|2@1+ (1,0) [0|3] "" Vector__XXX
 SG_ IntendedRetarderPercentTorque : 16|8@1+ (1,-125) [-125|125] "%" Vector__XXX
 SG_ RetarderEnableBrakeAssistSwitch : 4|2@1+ (1,0) [0|3] "" Vector__XXX
 SG_ RetarderEnableShiftAssistSwitch : 6|2@1+ (1,0) [0|3] "" Vector__XXX
 SG_ RetarderRequestingBrakeLight : 26|2@1+ (1,0) [0|3] "" Vector__XXX
 SG_ RetarderRoadSpeedExceededStatus : 30|2@1+ (1,0) [0|3] "" Vector__XXX
 SG_ RetarderRoadSpeedLimitSwitch : 28|2@1+ (1,0) [0|3] "" Vector__XXX
 SG_ RetarderSelectionnonengine : 48|8@1+ (0.4,0) [0|100] "%" Vector__XXX
 SG_ RetarderTorqueMode : 0|4@1+ (1,0) [0|15] "" Vector__XXX
 SG_ SrAddrssfCntrllngDvfrRtrdrCntrl : 32|8@1+ (1,0) [0|255] "SA" Vector__XXX

BO_ 2499608830 EFLP10: 8 Vector__XXX
 SG_ EngineCoolantPressure2 : 56|8@1+ (2,0) [0|500] "kPa" Vector__XXX
 SG_ EngnExhstGsRrltn2DffrntlPrssr : 0|16@1+ (0.0078125,-250) [-250|251.99] "kPa" Vector__XXX
 SG_ EngnExhstGsRrltn2IntkAsltPrssr : 40|16@1+ (0.1,0) [0|6425.5] "kPa" Vector__XXX
 SG_ EngnExhstGsRrltn2IntkPrssr : 16|8@1+ (2,0) [0|500] "kPa" Vector__XXX
 SG_ EngnExhstGsRrltn2OtltAsltPrssr : 24|16@1+ (0.1,0) [0|6425.5] "kPa" Vector__XXX

BO_ 2365456638 GPBAC: 8 Vector__XXX
 SG_ GeneratorPhaseBACFrequency : 32|16@1+ (0.0078125,0) [0|501.9921875] "Hz" Vector__XXX
 SG_ GeneratorPhaseBACRMSCurrent : 48|16@1+ (1,0) [0|64255] "A" Vector__XXX
 SG_ GnrtrPhsBCLnLnACRMSVltg : 0|16@1+ (1,0) [0|64255] "V" Vector__XXX
 SG_ GnrtrPhsBLnNtrlACRMSVltg : 16|16@1+ (1,0) [0|64255] "V" Vector__XXX

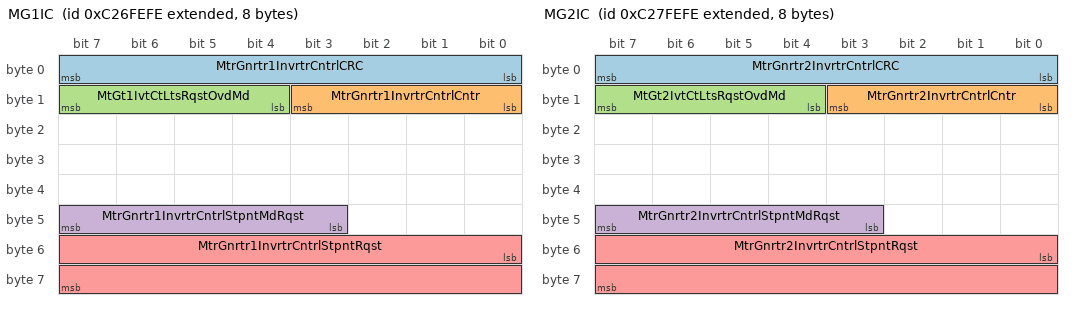
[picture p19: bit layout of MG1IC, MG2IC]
BO_ 2351365886 MG1IC: 8 Vector__XXX
 SG_ MtrGnrtr1InvrtrCntrlCRC : 0|8@1+ (1,0) [0|255] "count" Vector__XXX
 SG_ MtrGnrtr1InvrtrCntrlCntr : 8|4@1+ (1,0) [0|15] "" Vector__XXX
 SG_ MtGt1IvtCtLtsRqstOvdMd : 12|4@1+ (1,0) [0|15] "" Vector__XXX
 SG_ MtrGnrtr1InvrtrCntrlStpntMdRqst : 43|5@1+ (1,0) [0|31] "" Vector__XXX
 SG_ MtrGnrtr1InvrtrCntrlStpntRqst : 48|16@1+ (0.00390625,-125) [-125|125.99609375] "%" Vector__XXX

BO_ 2351431422 MG2IC: 8 Vector__XXX
 SG_ MtrGnrtr2InvrtrCntrlCRC : 0|8@1+ (1,0) [0|255] "count" Vector__XXX
 SG_ MtrGnrtr2InvrtrCntrlCntr : 8|4@1+ (1,0) [0|15] "" Vector__XXX
 SG_ MtGt2IvtCtLtsRqstOvdMd : 12|4@1+ (1,0) [0|15] "" Vector__XXX
 SG_ MtrGnrtr2InvrtrCntrlStpntMdRqst : 43|5@1+ (1,0) [0|31] "" Vector__XXX
 SG_ MtrGnrtr2InvrtrCntrlStpntRqst : 48|16@1+ (0.00390625,-125) [-125|125.99609375] "%" Vector__XXX

BO_ 2556165886 MG2IRP: 8 Vector__XXX
 SG_ MtrGnrtr2InvrtrLmtsRqstPwrCRC : 0|8@1+ (1,0) [0|255] "count" Vector__XXX
 SG_ MtrGnrtr2InvrtrLmtsRqstPwrCntr : 8|4@1+ (1,0) [0|15] "" Vector__XXX

BO_ 2556231422 MG2ILRM: 8 Vector__XXX
 SG_ MtrGnrtr2InvrtrLmtsRqstMhnlCRC : 0|8@1+ (1,0) [0|255] "count" Vector__XXX
 SG_ MtrGnrtr2InvrtrLmtsRqstMhnlCntr : 8|4@1+ (1,0) [0|15] "" Vector__XXX

BO_ 2556296958 MG2ILRDC: 8 Vector__XXX
 SG_ MtrGnrtr2InvrtrLmtsRqstDCSdCRC : 0|8@1+ (1,0) [0|255] "count" Vector__XXX
 SG_ MtrGnrtr2InvrtrLmtsRqstDCSdCntr : 8|4@1+ (1,0) [0|15] "" Vector__XXX

BO_ 2556362494 MG1ILRDC: 8 Vector__XXX
 SG_ MtrGnrtr1InvrtrLmtsRqstDCSdCRC : 0|8@1+ (1,0) [0|255] "count" Vector__XXX
 SG_ MtrGnrtr1InvrtrLmtsRqstDCSdCntr : 8|4@1+ (1,0) [0|15] "" Vector__XXX

BO_ 2556428030 MG1ILRM: 8 Vector__XXX
 SG_ MtrGnrtr1InvrtrLmtsRqstMhnlCRC : 0|8@1+ (1,0) [0|255] "count" Vector__XXX
 SG_ MtrGnrtr1InvrtrLmtsRqstMhnlCntr : 8|4@1+ (1,0) [0|15] "" Vector__XXX

CM_ BO_ 2633753598 "Alternator Temperature 2";
CM_ SG_ 2633753598 AltrntrArClrArIntkTmprtr "Temperature of air entering the air cooler in an alternator…";
CM_ SG_ 2633753598 AltrntrArClrArOtltTmprtr "Temperature of air after it exits from the air cooler in an alternator.…";
CM_ SG_ 2633753598 EngnAltrntrWndng10Tmprtr "Temperature of this winding inside the alternator.…";
CM_ SG_ 2633753598 EngnAltrntrWndng11Tmprtr "Temperature of this winding inside the alternator.…";
CM_ SG_ 2633753598 EngnAltrntrWndng12Tmprtr "Temperature of this winding inside the alternator.…";
CM_ SG_ 2633753598 EngnAltrntrWndng7Tmprtr "Temperature of this winding inside the alternator.…";
CM_ SG_ 2633753598 EngnAltrntrWndng8Tmprtr "Temperature of this winding inside the alternator.…";
CM_ SG_ 2633753598 EngnAltrntrWndng9Tmprtr "Temperature of this winding inside the alternator.…";
CM_ BO_ 2633754622 "SCR Operator Inducement Information 5";
CM_ SG_ 2633754622 Aftrtrtmnt1SCRIntkHghTmprtrTm "Indicates the time the aftertreatment 1 SCR intake temperature is above a manufacturer specified threshold. This is the temperature of engine combustion byprodu…";
CM_ SG_ 2633754622 SCROptIdtEOvdTtAtvtT "The total time duration the SCR Operator Inducement Override Mode (SPN 7342) has been active.Note:  Euro Stage V states this timer can not be reset.…";
CM_ BO_ 2633754878 "Aftertreatment System Information 2";
CM_ SG_ 2633754878 AftrtrtmntTtlDslExhstFldUsd "Total amount of DEF used by aftertreatment device 1 and aftertreatment device 2 over the lifetime of the system.See SPNs 5963 and 5964 for individual device acc…";
CM_ BO_ 2633755390 "Ethernet 1 Connection Information 1";
CM_ SG_ 2633755390 DefaultGatewayOctet1 "This value is the first of 4 octets in the ECU's configured or assigned Default Gateway IP address.  The Default Gateway IP address is separated into 4 bytes, 1…";
CM_ SG_ 2633755390 DefaultGatewayOctet2 "This value is the second of 4 octets in the ECU's configured or assigned Default Gateway IP address.  The Default Gateway IP address is separated into 4 bytes, …";
CM_ SG_ 2633755390 DefaultGatewayOctet3 "This value is the third of 4 octets in the ECU's configured or assigned Default Gateway IP address.  The Default Gateway IP address is separated into 4 bytes, 1…";
CM_ SG_ 2633755390 DefaultGatewayOctet4 "This value is the fourth of 4 octets in the ECU's configured or assigned Default Gateway IP address.  The Default Gateway IP address is separated into 4 bytes, …";
CM_ SG_ 2633755390 DHCPStatus "DHCP Client Status. This parameter is intended to provide feedback on the status of obtaining an IP address. When no physical link is available and DHCP is enab…";
CM_ SG_ 2633755390 EthernetLinkStatus "Ethernet Link Status. When there is no physical connection, the status shall report 00. 00b = Ethernet Link Down01b = Ethernet Link Up10b = Error11b = Not Suppo…";
CM_ SG_ 2633755390 IPv4AddressOctet1 "This value is the first of 4 octets in the ECU's assigned Internet Protocol (IP) address. The address is separated into 4 bytes, 1 per octet of the address. Byt…";
CM_ SG_ 2633755390 IPv4AddressOctet2 "This value is the second of 4 octets in the ECU's assigned Internet Protocol (IP) address. The address is separated into 4 bytes, 1 per octet of the address. By…";
CM_ SG_ 2633755390 IPv4AddressOctet3 "This value is the third of 4 octets in the ECU's assigned Internet Protocol (IP) address. The address is separated into 4 bytes, 1 per octet of the address. Byt…";
CM_ SG_ 2633755390 IPv4AddressOctet4 "This value is the fourth of 4 octets in the ECU's assigned Internet Protocol (IP) address. The address is separated into 4 bytes, 1 per octet of the address. By…";
CM_ SG_ 2633755390 MACAddressOctet1 "This value is the first of 6 octets in the ECU's assigned MAC address. The address is separated into 6 bytes, 1 per octet of the address. Byte 1 is the first oc…";
CM_ SG_ 2633755390 MACAddressOctet2 "This value is the second of 6 octets in the ECU's assigned MAC address. The address is separated into 6 bytes, 1 per octet of the address. Byte 1 is the first o…";
CM_ SG_ 2633755390 MACAddressOctet3 "This value is the third of 6 octets in the ECU's assigned MAC address. The address is separated into 6 bytes, 1 per octet of the address. Byte 1 is the first oc…";
CM_ SG_ 2633755390 MACAddressOctet4 "This value is the fourth of 6 octets in the ECU's assigned MAC address. The address is separated into 6 bytes, 1 per octet of the address. Byte 1 is the first o…";
CM_ SG_ 2633755390 MACAddressOctet5 "This value is the fifth of 6 octets in the ECU's assigned MAC address. The address is separated into 6 bytes, 1 per octet of the address. Byte 1 is the first oc…";
CM_ SG_ 2633755390 MACAddressOctet6 "This value is the sixth of 6 octets in the ECU's assigned MAC address. The address is separated into 6 bytes, 1 per octet of the address. Byte 1 is the first oc…";
CM_ SG_ 2633755390 SubnetMaskOctet1 "This value is the first of 4 octets in the ECU's configured Subnet mask. The subnet mask is separated into 4 bytes, 1 per octet of the mask. Byte 1 is the first…";
CM_ SG_ 2633755390 SubnetMaskOctet2 "This value is the second of 4 octets in the ECU's configured Subnet mask. The subnet mask is separated into 4 bytes, 1 per octet of the mask. Byte 1 is the firs…";
CM_ SG_ 2633755390 SubnetMaskOctet3 "This value is the third of 4 octets in the ECU's configured Subnet mask. The subnet mask is separated into 4 bytes, 1 per octet of the mask. Byte 1 is the first…";
CM_ SG_ 2633755390 SubnetMaskOctet4 "This value is the fourth of 4 octets in the ECU's configured Subnet mask. The subnet mask is separated into 4 bytes, 1 per octet of the mask. Byte 1 is the firs…";
CM_ BO_ 2633764094 "Evaporative Systems";
CM_ SG_ 2633764094 CanisterPurgeValveCommand "The commanded positon of the canister purge valve used to allow fuel vapors from the charcoal canister into the intake manifold.A value of 0 % indicates fully c…";
CM_ SG_ 2633764094 CanisterVentValve "The state of the canister vent value used to allow fresh air into the charcoal vapor canister.00b = Vent Valve is Closed01b = Vent Valve is Open10b = Error11b =…";
CM_ SG_ 2633764094 GasolineFuelTankPressure "The gage pressure of the vapor in the gasoline fuel tank.…";
CM_ BO_ 2633764350 "Fire Pump Statistics 1";
CM_ SG_ 2633764350 FirePumpEngagementCycles "Accumulated number of times the fire pump has been engaged.…";
CM_ SG_ 2633764350 FirePumpOperationTime "Accumulated time that the fire pump is enaged.…";
CM_ BO_ 2633769726 "Electronic Engine Controller 19";
CM_ SG_ 2633769726 EngnExhstFlwRtExtnddRng "Engine Exhaust Flow Rate shall indicate the measured/calculated exhaust gas mass flow upstream of the aftertreatment system.See SPN 6895 for alternative range.…";
CM_ SG_ 2633769726 TotalEngineEnergy "The total amount of energy delivered by the engine. It is accumulated over the life of the engine.…";
CM_ BO_ 2633773054 "Fire Suppression Agent Status";
CM_ SG_ 2633773054 FireSuppressionWaterTankLevel "Liquid level of the fire apparatus water tank.…";
CM_ SG_ 2633773054 FrSpprssnClssAFmTnkLvl "Liquid level of the Class-A foam agent tank.…";
CM_ SG_ 2633773054 FrSpprssnClssBFmTnkLvl "Liquid level of the Class-B foam agent tank.…";
CM_ SG_ 2633773054 FrSpprssnCmprssdArFmSstmArPrssr "Compressed Air Foam System (CAFS) air compressor pressure.…";
CM_ BO_ 2633773310 "SCR Operator Inducement Information 4";
CM_ SG_ 2633773310 SCROprtrIndmntOvrrdMd "Indicates the functional mode of SCR operator inducement override.000b = Not Available001b = Available - Not Active010b = Active011b = Active Extended100b = Exp…";
CM_ SG_ 2633773310 SCROprtrIndmntOvrrdRnwlRqrd "Indicates the required operator inducement override renewal state.00b = Not Required01b = Required10b = Error11b = Not Available…";
CM_ SG_ 2633773310 SCROptIdtEOvdTtRstOs "The total number of times the feature, which allows the operator to override the inducement strategies (as described in SPN 6880) during emergencies, such as hu…";
CM_ SG_ 2633773310 SCROptIdtOvdTRExtddR "Used to indicate the time remaining during an operator inducement override event.  When an operator inducement is active this parameter indicates the remaining …";
CM_ BO_ 2633782014 "Bin Weight and Lift Count";
CM_ SG_ 2633782014 BinInstance "Gives the instance of the bin on the vehicle whose parameters are transmitted in the remainder of the PGN, with the first or only bin as instance 1.…";
CM_ SG_ 2633782014 BinLiftCount "Increments with each lift, whether or not net bin weight changes.  The count rolls over at data range limit.The count can be reset using SPN 6898 in PGN 56832.…";
CM_ SG_ 2633782014 BinWeighingErrorStatus "Bin weighing error status0 = No error1 = Bad lift cycle2 = Weighing error: bin lifted, not emptied3 = Weighing error: empty bin lifted, emptied4 to 14 = Reserve…";
CM_ SG_ 2633782014 NetBinWeight "Mass of bin contents at most recent unload…";
CM_ BO_ 2633785086 "High Voltage Energy Storage 1 History";
CM_ SG_ 2633785086 HVES1CnttrOpnUndrLdCnt "This signal represents the number of times the contactors inside the High Voltage Energy Storage 1 pack (or system) have opened while current is flowing through…";
CM_ SG_ 2633785086 HVES1StateofHealth "This signal represents the expected remaining Life of the High Voltage Energy Storage 1 pack (or system), in percent.  Battery life is a manufacturer-specific m…";
CM_ SG_ 2633785086 HVES1TotalAccumulatedCharge "The total accumulated amp hours which have flowed through High Voltage Energy Storage 1 pack (or system).  This parameter is the sum of the absolute values of t…";
CM_ SG_ 2633785086 HVES1TotalEnergyThroughput "The total energy throughput which has flowed through High Voltage Energy Storage 1 pack (or system).  This parameter is the sum of the absolute values of the En…";
CM_ BO_ 2633801982 "Multi-fuel Engine Hours";
CM_ SG_ 2633801982 EngnTtlHrsfDslFlOprtn "Accumulated time of operation of engine when diesel fuel is used.  This parameter should be used only in multi-fuel engines.  See SPN 247 for single fuel engine…";
CM_ SG_ 2633801982 EngnTtlHrsfGssFlOprtn "Accumulated time of operation of engine when gaseous fuel is used.  This parameter should be used only in multi-fuel engines.  See SPN 247 for single fuel engin…";
CM_ BO_ 2633802238 "Engine Spark Misfire Rate 3";
CM_ SG_ 2633802238 EngineSparkPlug17MisfireRate "The spark misfire rate for Cylinder #17. The misfire rate is conveyed as the percentage of total cylinder spark misfires compared to the total number of ignitio…";
CM_ SG_ 2633802238 EngineSparkPlug18MisfireRate "The spark misfire rate for Cylinder #18. The misfire rate is conveyed as the percentage of total cylinder spark misfires compared to the total number of ignitio…";
CM_ SG_ 2633802238 EngineSparkPlug19MisfireRate "The spark misfire rate for Cylinder #19. The misfire rate is conveyed as the percentage of total cylinder spark misfires compared to the total number of ignitio…";
CM_ SG_ 2633802238 EngineSparkPlug20MisfireRate "The spark misfire rate for Cylinder #20. The misfire rate is conveyed as the percentage of total cylinder spark misfires compared to the total number of ignitio…";
CM_ SG_ 2633802238 EngineSparkPlug21MisfireRate "The spark misfire rate for Cylinder #21. The misfire rate is conveyed as the percentage of total cylinder spark misfires compared to the total number of ignitio…";
CM_ SG_ 2633802238 EngineSparkPlug22MisfireRate "The spark misfire rate for Cylinder #22. The misfire rate is conveyed as the percentage of total cylinder spark misfires compared to the total number of ignitio…";
CM_ SG_ 2633802238 EngineSparkPlug23MisfireRate "The spark misfire rate for Cylinder #23. The misfire rate is conveyed as the percentage of total cylinder spark misfires compared to the total number of ignitio…";
CM_ SG_ 2633802238 EngineSparkPlug24MisfireRate "The spark misfire rate for Cylinder #24. The misfire rate is conveyed as the percentage of total cylinder spark misfires compared to the total number of ignitio…";
CM_ BO_ 2633802494 "Engine Spark Misfire Rate 2";
CM_ SG_ 2633802494 EngineSparkPlug10MisfireRate "The spark misfire rate for Cylinder #10. The misfire rate is conveyed as the percentage of total cylinder spark misfires compared to the total number of ignitio…";
CM_ SG_ 2633802494 EngineSparkPlug11MisfireRate "The spark misfire rate for Cylinder #11. The misfire rate is conveyed as the percentage of total cylinder spark misfires compared to the total number of ignitio…";
CM_ SG_ 2633802494 EngineSparkPlug12MisfireRate "The spark misfire rate for Cylinder #12. The misfire rate is conveyed as the percentage of total cylinder spark misfires compared to the total number of ignitio…";
CM_ SG_ 2633802494 EngineSparkPlug13MisfireRate "The spark misfire rate for Cylinder #13. The misfire rate is conveyed as the percentage of total cylinder spark misfires compared to the total number of ignitio…";
CM_ SG_ 2633802494 EngineSparkPlug14MisfireRate "The spark misfire rate for Cylinder #14. The misfire rate is conveyed as the percentage of total cylinder spark misfires compared to the total number of ignitio…";
CM_ SG_ 2633802494 EngineSparkPlug15MisfireRate "The spark misfire rate for Cylinder #15. The misfire rate is conveyed as the percentage of total cylinder spark misfires compared to the total number of ignitio…";
CM_ SG_ 2633802494 EngineSparkPlug16MisfireRate "The spark misfire rate for Cylinder #16. The misfire rate is conveyed as the percentage of total cylinder spark misfires compared to the total number of ignitio…";
CM_ SG_ 2633802494 EngineSparkPlug9MisfireRate "The spark misfire rate for Cylinder #9. The misfire rate is conveyed as the percentage of total cylinder spark misfires compared to the total number of ignition…";
CM_ BO_ 2633802750 "Engine Spark Misfire Rate 1";
CM_ SG_ 2633802750 EngineSparkPlug1MisfireRate "The spark misfire rate for Cylinder #1. The misfire rate is conveyed as the percentage of total cylinder spark misfires compared to the total number of ignition…";
CM_ SG_ 2633802750 EngineSparkPlug2MisfireRate "The spark misfire rate for Cylinder #2. The misfire rate is conveyed as the percentage of total cylinder spark misfires compared to the total number of ignition…";
CM_ SG_ 2633802750 EngineSparkPlug3MisfireRate "The spark misfire rate for Cylinder #3. The misfire rate is conveyed as the percentage of total cylinder spark misfires compared to the total number of ignition…";
CM_ SG_ 2633802750 EngineSparkPlug4MisfireRate "The spark misfire rate for Cylinder #4. The misfire rate is conveyed as the percentage of total cylinder spark misfires compared to the total number of ignition…";
CM_ SG_ 2633802750 EngineSparkPlug5MisfireRate "The spark misfire rate for Cylinder #5. The misfire rate is conveyed as the percentage of total cylinder spark misfires compared to the total number of ignition…";
CM_ SG_ 2633802750 EngineSparkPlug6MisfireRate "The spark misfire rate for Cylinder #6. The misfire rate is conveyed as the percentage of total cylinder spark misfires compared to the total number of ignition…";
CM_ SG_ 2633802750 EngineSparkPlug7MisfireRate "The spark misfire rate for Cylinder #7. The misfire rate is conveyed as the percentage of total cylinder spark misfires compared to the total number of ignition…";
CM_ SG_ 2633802750 EngineSparkPlug8MisfireRate "The spark misfire rate for Cylinder #8. The misfire rate is conveyed as the percentage of total cylinder spark misfires compared to the total number of ignition…";
CM_ BO_ 2633803006 "Engine Spark Maximum Voltage 6";
CM_ SG_ 2633803006 EngineSparkPlug21MaximumVoltage "The largest measured spark voltage of all measured spark events on Cylinder #21 since the last time this tracking data was reset.  It is reset using Reset PGN 5…";
CM_ SG_ 2633803006 EngineSparkPlug22MaximumVoltage "The largest measured spark voltage of all measured spark events on Cylinder #22 since the last time this tracking data was reset.  It is reset using Reset PGN 5…";
CM_ SG_ 2633803006 EngineSparkPlug23MaximumVoltage "The largest measured spark voltage of all measured spark events on Cylinder #23 since the last time this tracking data was reset.  It is reset using Reset PGN 5…";
CM_ SG_ 2633803006 EngineSparkPlug24MaximumVoltage "The largest measured spark voltage of all measured spark events on Cylinder #24 since the last time this tracking data was reset.  It is reset using Reset PGN 5…";
CM_ BO_ 2633803262 "Engine Spark Maximum Voltage 5";
CM_ SG_ 2633803262 EngineSparkPlug17MaximumVoltage "The largest measured spark voltage of all measured spark events on Cylinder #17 since the last time this tracking data was reset.  It is reset using Reset PGN 5…";
CM_ SG_ 2633803262 EngineSparkPlug18MaximumVoltage "The largest measured spark voltage of all measured spark events on Cylinder #18 since the last time this tracking data was reset.  It is reset using Reset PGN 5…";
CM_ SG_ 2633803262 EngineSparkPlug19MaximumVoltage "The largest measured spark voltage of all measured spark events on Cylinder #19 since the last time this tracking data was reset.  It is reset using Reset PGN 5…";
CM_ SG_ 2633803262 EngineSparkPlug20MaximumVoltage "The largest measured spark voltage of all measured spark events on Cylinder #20 since the last time this tracking data was reset.  It is reset using Reset PGN 5…";
CM_ BO_ 2633803518 "Engine Spark Maximum Voltage 4";
CM_ SG_ 2633803518 EngineSparkPlug13MaximumVoltage "The largest measured spark voltage of all measured spark events on Cylinder #13 since the last time this tracking data was reset.  It is reset using Reset PGN 5…";
CM_ SG_ 2633803518 EngineSparkPlug14MaximumVoltage "The largest measured spark voltage of all measured spark events on Cylinder #14 since the last time this tracking data was reset.  It is reset using Reset PGN 5…";
CM_ SG_ 2633803518 EngineSparkPlug15MaximumVoltage "The largest measured spark voltage of all measured spark events on Cylinder #15 since the last time this tracking data was reset.  It is reset using Reset PGN 5…";
CM_ SG_ 2633803518 EngineSparkPlug16MaximumVoltage "The largest measured spark voltage of all measured spark events on Cylinder #16 since the last time this tracking data was reset.  It is reset using Reset PGN 5…";
CM_ BO_ 2633803774 "Engine Spark Maximum Voltage 3";
CM_ SG_ 2633803774 EngineSparkPlug10MaximumVoltage "The largest measured spark voltage of all measured spark events on Cylinder #10 since the last time this tracking data was reset.  It is reset using Reset PGN 5…";
CM_ SG_ 2633803774 EngineSparkPlug11MaximumVoltage "The largest measured spark voltage of all measured spark events on Cylinder #11 since the last time this tracking data was reset.  It is reset using Reset PGN 5…";
CM_ SG_ 2633803774 EngineSparkPlug12MaximumVoltage "The largest measured spark voltage of all measured spark events on Cylinder #12 since the last time this tracking data was reset.  It is reset using Reset PGN 5…";
CM_ SG_ 2633803774 EngineSparkPlug9MaximumVoltage "The largest measured spark voltage of all measured spark events on Cylinder #9 since the last time this tracking data was reset.  It is reset using Reset PGN 56…";
CM_ BO_ 2633804030 "Engine Spark Maximum Voltage 2";
CM_ SG_ 2633804030 EngineSparkPlug5MaximumVoltage "The largest measured spark voltage of all measured spark events on Cylinder #5 since the last time this tracking data was reset.  It is reset using Reset PGN 56…";
CM_ SG_ 2633804030 EngineSparkPlug6MaximumVoltage "The largest measured spark voltage of all measured spark events on Cylinder #6 since the last time this tracking data was reset.  It is reset using Reset PGN 56…";
CM_ SG_ 2633804030 EngineSparkPlug7MaximumVoltage "The largest measured spark voltage of all measured spark events on Cylinder #7 since the last time this tracking data was reset.  It is reset using Reset PGN 56…";
CM_ SG_ 2633804030 EngineSparkPlug8MaximumVoltage "The largest measured spark voltage of all measured spark events on Cylinder #8 since the last time this tracking data was reset.  It is reset using Reset PGN 56…";
CM_ BO_ 2633804286 "Engine Spark Maximum Voltage 1";
CM_ SG_ 2633804286 EngineSparkPlug1MaximumVoltage "The largest measured spark voltage of all measured spark events on Cylinder #1 since the last time this tracking data was reset.  It is reset using Reset PGN 56…";
CM_ SG_ 2633804286 EngineSparkPlug2MaximumVoltage "The largest measured spark voltage of all measured spark events on Cylinder #2 since the last time this tracking data was reset.  It is reset using Reset PGN 56…";
CM_ SG_ 2633804286 EngineSparkPlug3MaximumVoltage "The largest measured spark voltage of all measured spark events on Cylinder #3 since the last time this tracking data was reset.  It is reset using Reset PGN 56…";
CM_ SG_ 2633804286 EngineSparkPlug4MaximumVoltage "The largest measured spark voltage of all measured spark events on Cylinder #4 since the last time this tracking data was reset.  It is reset using Reset PGN 56…";
CM_ BO_ 2633804542 "Engine Spark Minimum Voltage 6";
CM_ SG_ 2633804542 EngineSparkPlug21MinimumVoltage "The smallest measured spark voltage of all measured spark events on Cylinder #21 since the last time this tracking data was reset.  It is reset using Reset PGN …";
CM_ SG_ 2633804542 EngineSparkPlug22MinimumVoltage "The smallest measured spark voltage of all measured spark events on Cylinder #22 since the last time this tracking data was reset.  It is reset using Reset PGN …";
CM_ SG_ 2633804542 EngineSparkPlug23MinimumVoltage "The smallest measured spark voltage of all measured spark events on Cylinder #23 since the last time this tracking data was reset.  It is reset using Reset PGN …";
CM_ SG_ 2633804542 EngineSparkPlug24MinimumVoltage "The smallest measured spark voltage of all measured spark events on Cylinder #24 since the last time this tracking data was reset.  It is reset using Reset PGN …";
CM_ BO_ 2633804798 "Engine Spark Minimum Voltage 5";
CM_ SG_ 2633804798 EngineSparkPlug17MinimumVoltage "The smallest measured spark voltage of all measured spark events on Cylinder #17 since the last time this tracking data was reset.  It is reset using Reset PGN …";
CM_ SG_ 2633804798 EngineSparkPlug18MinimumVoltage "The smallest measured spark voltage of all measured spark events on Cylinder #18 since the last time this tracking data was reset.  It is reset using Reset PGN …";
CM_ SG_ 2633804798 EngineSparkPlug19MinimumVoltage "The smallest measured spark voltage of all measured spark events on Cylinder #19 since the last time this tracking data was reset.  It is reset using Reset PGN …";
CM_ SG_ 2633804798 EngineSparkPlug20MinimumVoltage "The smallest measured spark voltage of all measured spark events on Cylinder #20 since the last time this tracking data was reset.  It is reset using Reset PGN …";
CM_ BO_ 2633805054 "Engine Spark Minimum Voltage 4";
CM_ SG_ 2633805054 EngineSparkPlug13MinimumVoltage "The smallest measured spark voltage of all measured spark events on Cylinder #13 since the last time this tracking data was reset.  It is reset using Reset PGN …";
CM_ SG_ 2633805054 EngineSparkPlug14MinimumVoltage "The smallest measured spark voltage of all measured spark events on Cylinder #14 since the last time this tracking data was reset.  It is reset using Reset PGN …";
CM_ SG_ 2633805054 EngineSparkPlug15MinimumVoltage "The smallest measured spark voltage of all measured spark events on Cylinder #15 since the last time this tracking data was reset.  It is reset using Reset PGN …";
CM_ SG_ 2633805054 EngineSparkPlug16MinimumVoltage "The smallest measured spark voltage of all measured spark events on Cylinder #16 since the last time this tracking data was reset.  It is reset using Reset PGN …";
CM_ BO_ 2633805310 "Engine Spark Minimum Voltage 3";
CM_ SG_ 2633805310 EngineSparkPlug10MinimumVoltage "The smallest measured spark voltage of all measured spark events on Cylinder #10 since the last time this tracking data was reset.  It is reset using Reset PGN …";
CM_ SG_ 2633805310 EngineSparkPlug11MinimumVoltage "The smallest measured spark voltage of all measured spark events on Cylinder #11 since the last time this tracking data was reset.  It is reset using Reset PGN …";
CM_ SG_ 2633805310 EngineSparkPlug12MinimumVoltage "The smallest measured spark voltage of all measured spark events on Cylinder #12 since the last time this tracking data was reset.  It is reset using Reset PGN …";
CM_ SG_ 2633805310 EngineSparkPlug9MinimumVoltage "The smallest measured spark voltage of all measured spark events on Cylinder #9 since the last time this tracking data was reset.  It is reset using Reset PGN 5…";
CM_ BO_ 2633805566 "Engine Spark Minimum Voltage 2";
CM_ SG_ 2633805566 EngineSparkPlug5MinimumVoltage "The smallest measured spark voltage of all measured spark events on Cylinder #5 since the last time this tracking data was reset.  It is reset using Reset PGN 5…";
CM_ SG_ 2633805566 EngineSparkPlug6MinimumVoltage "The smallest measured spark voltage of all measured spark events on Cylinder #6 since the last time this tracking data was reset.  It is reset using Reset PGN 5…";
CM_ SG_ 2633805566 EngineSparkPlug7MinimumVoltage "The smallest measured spark voltage of all measured spark events on Cylinder #7 since the last time this tracking data was reset.  It is reset using Reset PGN 5…";
CM_ SG_ 2633805566 EngineSparkPlug8MinimumVoltage "The smallest measured spark voltage of all measured spark events on Cylinder #8 since the last time this tracking data was reset.  It is reset using Reset PGN 5…";
CM_ BO_ 2633805822 "Engine Spark Minimum Voltage 1";
CM_ SG_ 2633805822 EngineSparkPlug1MinimumVoltage "The smallest measured spark voltage of all measured spark events on Cylinder #1 since the last time this tracking data was reset.  It is reset using Reset PGN 5…";
CM_ SG_ 2633805822 EngineSparkPlug2MinimumVoltage "The smallest measured spark voltage of all measured spark events on Cylinder #2 since the last time this tracking data was reset.  It is reset using Reset PGN 5…";
CM_ SG_ 2633805822 EngineSparkPlug3MinimumVoltage "The smallest measured spark voltage of all measured spark events on Cylinder #3 since the last time this tracking data was reset.  It is reset using Reset PGN 5…";
CM_ SG_ 2633805822 EngineSparkPlug4MinimumVoltage "The smallest measured spark voltage of all measured spark events on Cylinder #4 since the last time this tracking data was reset.  It is reset using Reset PGN 5…";
CM_ BO_ 2633806078 "Engine Ignition Controller Maintenance Hours";
CM_ SG_ 2633806078 EngnIgntnCntrlMdl1TmRmnng "This parameter reports the time remaining before maintenance should be performed on engine ignition control module instance 1.  Upon maintenance, the time is re…";
CM_ SG_ 2633806078 EngnIgntnCntrlMdl2TmRmnng "This parameter reports the time remaining before maintenance should be performed on engine ignition control module instance 2.  Upon maintenance, the time is re…";
CM_ BO_ 2633825022 "Electronic Engine Controller 11";
CM_ SG_ 2633825022 EngnExhstGsRrltn2Vlv1Cntrl "Desired percentage of maximum Exhaust Gas Recirculation 2 (EGR2) valve opening. 0% means the valve is closed. 100% means maximum opening (full gas flow).…";
CM_ SG_ 2633825022 EngnExhstGsRrltn2Vlv1PstnErrr "The position error of the Exhaust Gas Recirculation 2 valve, determined as the actual position (SPN 5264) minus the commanded position (SPN 5262).…";
CM_ SG_ 2633825022 EngnExhstGsRrltn2Vlv2Cntrl "Desired percentage of maximum Exhaust Gas Recirculation 2 (EGR2) valve 2 opening. 0% means the valve is closed. 100% means maximum opening (full gas flow).…";
CM_ SG_ 2633825022 EngnExhstGsRrltn2Vlv2PstnErrr "The position error of the Exhaust Gas Recirculation 2 valve 2, determined as the actual position (SPN 5265) minus the commanded position (SPN 5263).…";
CM_ BO_ 2633825534 "Engine Manifold Actuator Control";
CM_ SG_ 2633825534 EExstMdB1FwBVvAttCt "Commanded percentage of maximum Engine Exhaust Manifold Bank 1 Balance valve opening. 0% means valve is closed. 100% means maximum valve opening (full gas flow)…";
CM_ SG_ 2633825534 EExstMdB2FwBVvAttCt "Commanded percentage of maximum Engine Ehaust Manifold Bank 2 Balance valve opening. 0% means valve is closed. 100% means maximum valve opening (full gas flow).…";
CM_ BO_ 2633826046 "Electronic Engine Controller 10";
CM_ SG_ 2633826046 EExstGsRt2CBpssAttPst "EGR2 Cooler Bypass Actuator position, where 0% = Fully Closed (no gas flowing through the bypass), and 100% = Fully Open..…";
CM_ SG_ 2633826046 EExstGsRt2CItGsAstPss "Exhaust Gas Recirculation 2 gas absolute pressure is measured at EGR2 cooler intake. See SPN 5253 for EGR2 pressure measured at the EGR2 cooler outlet before th…";
CM_ SG_ 2633826046 EngnExhstGsRrltn2ClrEffn "Exhaust Gas Recirculation 2 cooler efficiency is an indication of the cooler’s ability to reduce the temperature of the exhaust gas that is being recirculated b…";
CM_ SG_ 2633826046 EngnExhstGsRrltn2ClrIntkPrssr "Exhaust gas recirculation 2 (EGR2) gage pressure is measured at the EGR2 cooler intake.…";
CM_ SG_ 2633826046 EngnExhstGsRrltn2ClrIntkTmprtr "Exhaust Gas Recirculation 2 (EGR2) Temperature measured at EGR2 cooler intake. See SPN 5255 for Engine EGR2 temperature.…";
CM_ BO_ 2633828606 "Engine oil message";
CM_ SG_ 2633828606 EngineOilDensity "Density of the engine oil…";
CM_ SG_ 2633828606 EngineOilTemperature3 "Temperature of the engine lubricant.Note:  If there is only one engine oil temperature measurement, SPN 175 should be used. See also SPNs 175 and 1135 for addit…";
CM_ SG_ 2633828606 EngineOilViscosity "Dynamic viscosity of the engine oil…";
CM_ SG_ 2633828606 EngnOlRltvDltrtHghRsltn "Engine oil relative dielectricity used to describe the engine oil quality.…";
CM_ BO_ 2633832702 "Collision Sensor Information";
CM_ SG_ 2633832702 FrontalCollisionSensor1Type "Type of Frontal Collision Sensor 1.0000b = acceleration sensor0001b = pressure sensor0010b = rollrate sensor0011b = sonic sensor0100b = fiber-optic sensor0101b …";
CM_ SG_ 2633832702 FrontalCollisionSensor2Type "Type of Frontal Collision Sensor 2.0000b = acceleration sensor0001b = pressure sensor0010b = rollrate sensor0011b = sonic sensor0100b = fiber-optic sensor0101b …";
CM_ SG_ 2633832702 FrontalCollisionSensor3Type "Type of Frontal Collision Sensor 3.0000b = acceleration sensor0001b = pressure sensor0010b = rollrate sensor0011b = sonic sensor0100b = fiber-optic sensor0101b …";
CM_ SG_ 2633832702 FrontalCollisionSensor4Type "Type of Frontal Collision Sensor 4.0000b = acceleration sensor0001b = pressure sensor0010b = rollrate sensor0011b = sonic sensor0100b = fiber-optic sensor0101b …";
CM_ SG_ 2633832702 RearCollisionSensor1Type "Type of Rear Collision Sensor 1.0000b = acceleration sensor0001b = pressure sensor0010b = rollrate sensor0011b = sonic sensor0100b = fiber-optic sensor0101b = r…";
CM_ SG_ 2633832702 RearCollisionSensor2Type "Type of Rear Collision Sensor 2.0000b = acceleration sensor0001b = pressure sensor0010b = rollrate sensor0011b = sonic sensor0100b = fiber-optic sensor0101b = r…";
CM_ SG_ 2633832702 RearCollisionSensor3Type "Type of Rear Collision Sensor 3.0000b = acceleration sensor0001b = pressure sensor0010b = rollrate sensor0011b = sonic sensor0100b = fiber-optic sensor0101b = r…";
CM_ SG_ 2633832702 RearCollisionSensor4Type "Type of Rear Collision Sensor 4.0000b = acceleration sensor0001b = pressure sensor0010b = rollrate sensor0011b = sonic sensor0100b = fiber-optic sensor0101b = r…";
CM_ SG_ 2633832702 SdCllsnSnsrFrntLftTp "Type of Side Collision Sensor Front - Left.0000b = acceleration sensor0001b = pressure sensor0010b = rollrate sensor0011b = sonic sensor0100b = fiber-optic sens…";
CM_ SG_ 2633832702 SdCllsnSnsrFrntRghtTp "Type of Side Collision Sensor Front - Right.0000b = acceleration sensor0001b = pressure sensor0010b = rollrate sensor0011b = sonic sensor0100b = fiber-optic sen…";
CM_ SG_ 2633832702 SdCllsnSnsrMdFrntLftTp "Type of Side Collision Sensor Mid Front - Left.0000b = acceleration sensor0001b = pressure sensor0010b = rollrate sensor0011b = sonic sensor0100b = fiber-optic …";
CM_ SG_ 2633832702 SdCllsnSnsrMdFrntRghtTp "Type of Side Collision Sensor Mid Front - Right.0000b = acceleration sensor0001b = pressure sensor0010b = rollrate sensor0011b = sonic sensor0100b = fiber-optic…";
CM_ SG_ 2633832702 SdCllsnSnsrMdRrLftTp "Type of Side Collision Sensor Mid Rear - Left.0000b = acceleration sensor0001b = pressure sensor0010b = rollrate sensor0011b = sonic sensor0100b = fiber-optic s…";
CM_ SG_ 2633832702 SdCllsnSnsrMdRrRghtTp "Type of Side Collision Sensor Mid Rear - Right.0000b = acceleration sensor0001b = pressure sensor0010b = rollrate sensor0011b = sonic sensor0100b = fiber-optic …";
CM_ SG_ 2633832702 SdCllsnSnsrRrRghtTp "Type of Side Collision Sensor Rear - Right.0000b = acceleration sensor0001b = pressure sensor0010b = rollrate sensor0011b = sonic sensor0100b = fiber-optic sens…";
CM_ SG_ 2633832702 SideCollisionSensorRearLeftType "Type of Side Collision Sensor Rear - Left.0000b = acceleration sensor0001b = pressure sensor0010b = rollrate sensor0011b = sonic sensor0100b = fiber-optic senso…";
CM_ BO_ 2633832958 "Ignitor Loop Information";
CM_ SG_ 2633832958 DrvrArgIgntrLp1stStgRsstn "Resistance of Driver Airbag Ignitor Loop 1st Stage.…";
CM_ SG_ 2633832958 DrvrArgIgntrLp2ndStgRsstn "Resistance of Driver Airbag Ignitor Loop 2nd Stage.…";
CM_ SG_ 2633832958 DrvrBltTnsnrIgntrLpRsstn "Resistance of Driver Belt Tensioner Ignitor Loop 1st Stage.…";
CM_ SG_ 2633832958 PssngrArgIgntrLp1stStgRsstn "Resistance of Passenger Airbag Ignitor Loop 1st Stage.…";
CM_ SG_ 2633832958 PssngrArgIgntrLp2ndStgRsstn "Resistance of Passenger Airbag Ignitor Loop 2nd Stage.…";
CM_ SG_ 2633832958 PssngrBltTnsnrIgntrLpRsstn "Resistance of Passenger Belt Tensioner Ignitor Loop 1st Stage.…";
CM_ SG_ 2633832958 SdBgIgntrLp1LftRsstn "Resistance of Side Bag Ignitor Loop 1 - Left.…";
CM_ SG_ 2633832958 SdBgIgntrLp1RghtRsstn "Resistance of Side Bag Ignitor Loop 1 - Right.…";
CM_ SG_ 2633832958 SdBgIgntrLp2LftRsstn "Resistance of Side Bag Ignitor Loop 2 - Left.…";
CM_ SG_ 2633832958 SdBgIgntrLp2RghtRsstn "Resistance of Side Bag Ignitor Loop 2 - Right.…";
CM_ SG_ 2633832958 SpecialIgnitorLoop10Resistance "Resistance of Special Ignitor Loop 10.   Since there are many different vehicle types (e.g. truck, bus, firetruck or ambulance), the ignitor loop configuration …";
CM_ SG_ 2633832958 SpecialIgnitorLoop11Resistance "Resistance of Special Ignitor Loop 11.   Since there are many different vehicle types (e.g. truck, bus, firetruck or ambulance), the ignitor loop configuration …";
CM_ SG_ 2633832958 SpecialIgnitorLoop12Resistance "Resistance of Special Ignitor Loop 12.   Since there are many different vehicle types (e.g. truck, bus, firetruck or ambulance), the ignitor loop configuration …";
CM_ SG_ 2633832958 SpecialIgnitorLoop13Resistance "Resistance of Special Ignitor Loop 13.   Since there are many different vehicle types (e.g. truck, bus, firetruck or ambulance), the ignitor loop configuration …";
CM_ SG_ 2633832958 SpecialIgnitorLoop14Resistance "Resistance of Special Ignitor Loop 14.   Since there are many different vehicle types (e.g. truck, bus, firetruck or ambulance), the ignitor loop configuration …";
CM_ SG_ 2633832958 SpecialIgnitorLoop15Resistance "Resistance of Special Ignitor Loop 15.   Since there are many different vehicle types (e.g. truck, bus, firetruck or ambulance), the ignitor loop configuration …";
CM_ SG_ 2633832958 SpecialIgnitorLoop16Resistance "Resistance of Special Ignitor Loop 16.   Since there are many different vehicle types (e.g. truck, bus, firetruck or ambulance), the ignitor loop configuration …";
CM_ SG_ 2633832958 SpecialIgnitorLoop17Resistance "Resistance of Special Ignitor Loop 17.   Since there are many different vehicle types (e.g. truck, bus, firetruck or ambulance), the ignitor loop configuration …";
CM_ SG_ 2633832958 SpecialIgnitorLoop18Resistance "Resistance of Special Ignitor Loop 18.   Since there are many different vehicle types (e.g. truck, bus, firetruck or ambulance), the ignitor loop configuration …";
CM_ SG_ 2633832958 SpecialIgnitorLoop19Resistance "Resistance of Special Ignitor Loop 19.   Since there are many different vehicle types (e.g. truck, bus, firetruck or ambulance), the ignitor loop configuration …";
CM_ SG_ 2633832958 SpecialIgnitorLoop1Resistance "Resistance of Special Ignitor Loop 1.   Since there are many different vehicle types (e.g. truck, bus, firetruck or ambulance), the ignitor loop configuration h…";
CM_ SG_ 2633832958 SpecialIgnitorLoop20Resistance "Resistance of Special Ignitor Loop 20.   Since there are many different vehicle types (e.g. truck, bus, firetruck or ambulance), the ignitor loop configuration …";
CM_ SG_ 2633832958 SpecialIgnitorLoop21Resistance "Resistance of Special Ignitor Loop 21.   Since there are many different vehicle types (e.g. truck, bus, firetruck or ambulance), the ignitor loop configuration …";
CM_ SG_ 2633832958 SpecialIgnitorLoop22Resistance "Resistance of Special Ignitor Loop 22.   Since there are many different vehicle types (e.g. truck, bus, firetruck or ambulance), the ignitor loop configuration …";
CM_ SG_ 2633832958 SpecialIgnitorLoop23Resistance "Resistance of Special Ignitor Loop 23.   Since there are many different vehicle types (e.g. truck, bus, firetruck or ambulance), the ignitor loop configuration …";
CM_ SG_ 2633832958 SpecialIgnitorLoop24Resistance "Resistance of Special Ignitor Loop 24.   Since there are many different vehicle types (e.g. truck, bus, firetruck or ambulance), the ignitor loop configuration …";
CM_ SG_ 2633832958 SpecialIgnitorLoop25Resistance "Resistance of Special Ignitor Loop 25.   Since there are many different vehicle types (e.g. truck, bus, firetruck or ambulance), the ignitor loop configuration …";
CM_ SG_ 2633832958 SpecialIgnitorLoop26Resistance "Resistance of Special Ignitor Loop 26.   Since there are many different vehicle types (e.g. truck, bus, firetruck or ambulance), the ignitor loop configuration …";
CM_ SG_ 2633832958 SpecialIgnitorLoop27Resistance "Resistance of Special Ignitor Loop 27.   Since there are many different vehicle types (e.g. truck, bus, firetruck or ambulance), the ignitor loop configuration …";
CM_ SG_ 2633832958 SpecialIgnitorLoop28Resistance "Resistance of Special Ignitor Loop 28.   Since there are many different vehicle types (e.g. truck, bus, firetruck or ambulance), the ignitor loop configuration …";
CM_ SG_ 2633832958 SpecialIgnitorLoop29Resistance "Resistance of Special Ignitor Loop 29.   Since there are many different vehicle types (e.g. truck, bus, firetruck or ambulance), the ignitor loop configuration …";
CM_ SG_ 2633832958 SpecialIgnitorLoop2Resistance "Resistance of Special Ignitor Loop 2.   Since there are many different vehicle types (e.g. truck, bus, firetruck or ambulance), the ignitor loop configuration h…";
CM_ SG_ 2633832958 SpecialIgnitorLoop30Resistance "Resistance of Special Ignitor Loop 30.   Since there are many different vehicle types (e.g. truck, bus, firetruck or ambulance), the ignitor loop configuration …";
CM_ SG_ 2633832958 SpecialIgnitorLoop31Resistance "Resistance of Special Ignitor Loop 31.   Since there are many different vehicle types (e.g. truck, bus, firetruck or ambulance), the ignitor loop configuration …";
CM_ SG_ 2633832958 SpecialIgnitorLoop32Resistance "Resistance of Special Ignitor Loop 32.   Since there are many different vehicle types (e.g. truck, bus, firetruck or ambulance), the ignitor loop configuration …";
CM_ SG_ 2633832958 SpecialIgnitorLoop33Resistance "Resistance of Special Ignitor Loop 33.   Since there are many different vehicle types (e.g. truck, bus, firetruck or ambulance), the ignitor loop configuration …";
CM_ SG_ 2633832958 SpecialIgnitorLoop34Resistance "Resistance of Special Ignitor Loop 34.   Since there are many different vehicle types (e.g. truck, bus, firetruck or ambulance), the ignitor loop configuration …";
CM_ SG_ 2633832958 SpecialIgnitorLoop35Resistance "Resistance of Special Ignitor Loop 35.   Since there are many different vehicle types (e.g. truck, bus, firetruck or ambulance), the ignitor loop configuration …";
CM_ SG_ 2633832958 SpecialIgnitorLoop36Resistance "Resistance of Special Ignitor Loop 36.   Since there are many different vehicle types (e.g. truck, bus, firetruck or ambulance), the ignitor loop configuration …";
CM_ SG_ 2633832958 SpecialIgnitorLoop37Resistance "Resistance of Special Ignitor Loop 37.   Since there are many different vehicle types (e.g. truck, bus, firetruck or ambulance), the ignitor loop configuration …";
CM_ SG_ 2633832958 SpecialIgnitorLoop38Resistance "Resistance of Special Ignitor Loop 38.   Since there are many different vehicle types (e.g. truck, bus, firetruck or ambulance), the ignitor loop configuration …";
CM_ SG_ 2633832958 SpecialIgnitorLoop39Resistance "Resistance of Special Ignitor Loop 39.   Since there are many different vehicle types (e.g. truck, bus, firetruck or ambulance), the ignitor loop configuration …";
CM_ SG_ 2633832958 SpecialIgnitorLoop3Resistance "Resistance of Special Ignitor Loop 3.   Since there are many different vehicle types (e.g. truck, bus, firetruck or ambulance), the ignitor loop configuration h…";
CM_ SG_ 2633832958 SpecialIgnitorLoop40Resistance "Resistance of Special Ignitor Loop 40.   Since there are many different vehicle types (e.g. truck, bus, firetruck or ambulance), the ignitor loop configuration …";
CM_ SG_ 2633832958 SpecialIgnitorLoop41Resistance "Resistance of Special Ignitor Loop 41.   Since there are many different vehicle types (e.g. truck, bus, firetruck or ambulance), the ignitor loop configuration …";
CM_ SG_ 2633832958 SpecialIgnitorLoop42Resistance "Resistance of Special Ignitor Loop 42.   Since there are many different vehicle types (e.g. truck, bus, firetruck or ambulance), the ignitor loop configuration …";
CM_ SG_ 2633832958 SpecialIgnitorLoop43Resistance "Resistance of Special Ignitor Loop 43.   Since there are many different vehicle types (e.g. truck, bus, firetruck or ambulance), the ignitor loop configuration …";
CM_ SG_ 2633832958 SpecialIgnitorLoop44Resistance "Resistance of Special Ignitor Loop 44.   Since there are many different vehicle types (e.g. truck, bus, firetruck or ambulance), the ignitor loop configuration …";
CM_ SG_ 2633832958 SpecialIgnitorLoop45Resistance "Resistance of Special Ignitor Loop 45.   Since there are many different vehicle types (e.g. truck, bus, firetruck or ambulance), the ignitor loop configuration …";
CM_ SG_ 2633832958 SpecialIgnitorLoop46Resistance "Resistance of Special Ignitor Loop 46.   Since there are many different vehicle types (e.g. truck, bus, firetruck or ambulance), the ignitor loop configuration …";
CM_ SG_ 2633832958 SpecialIgnitorLoop47Resistance "Resistance of Special Ignitor Loop 47.   Since there are many different vehicle types (e.g. truck, bus, firetruck or ambulance), the ignitor loop configuration …";
CM_ SG_ 2633832958 SpecialIgnitorLoop48Resistance "Resistance of Special Ignitor Loop 48.   Since there are many different vehicle types (e.g. truck, bus, firetruck or ambulance), the ignitor loop configuration …";
CM_ SG_ 2633832958 SpecialIgnitorLoop49Resistance "Resistance of Special Ignitor Loop 49.   Since there are many different vehicle types (e.g. truck, bus, firetruck or ambulance), the ignitor loop configuration …";
CM_ SG_ 2633832958 SpecialIgnitorLoop4Resistance "Resistance of Special Ignitor Loop 4.   Since there are many different vehicle types (e.g. truck, bus, firetruck or ambulance), the ignitor loop configuration h…";
CM_ SG_ 2633832958 SpecialIgnitorLoop50Resistance "Resistance of Special Ignitor Loop 50.   Since there are many different vehicle types (e.g. truck, bus, firetruck or ambulance), the ignitor loop configuration …";
CM_ SG_ 2633832958 SpecialIgnitorLoop51Resistance "Resistance of Special Ignitor Loop 51.   Since there are many different vehicle types (e.g. truck, bus, firetruck or ambulance), the ignitor loop configuration …";
CM_ SG_ 2633832958 SpecialIgnitorLoop52Resistance "Resistance of Special Ignitor Loop 52.   Since there are many different vehicle types (e.g. truck, bus, firetruck or ambulance), the ignitor loop configuration …";
CM_ SG_ 2633832958 SpecialIgnitorLoop53Resistance "Resistance of Special Ignitor Loop 53.   Since there are many different vehicle types (e.g. truck, bus, firetruck or ambulance), the ignitor loop configuration …";
CM_ SG_ 2633832958 SpecialIgnitorLoop54Resistance "Resistance of Special Ignitor Loop 54.   Since there are many different vehicle types (e.g. truck, bus, firetruck or ambulance), the ignitor loop configuration …";
CM_ SG_ 2633832958 SpecialIgnitorLoop55Resistance "Resistance of Special Ignitor Loop 55.   Since there are many different vehicle types (e.g. truck, bus, firetruck or ambulance), the ignitor loop configuration …";
CM_ SG_ 2633832958 SpecialIgnitorLoop56Resistance "Resistance of Special Ignitor Loop 56.   Since there are many different vehicle types (e.g. truck, bus, firetruck or ambulance), the ignitor loop configuration …";
CM_ SG_ 2633832958 SpecialIgnitorLoop57Resistance "Resistance of Special Ignitor Loop 57.   Since there are many different vehicle types (e.g. truck, bus, firetruck or ambulance), the ignitor loop configuration …";
CM_ SG_ 2633832958 SpecialIgnitorLoop58Resistance "Resistance of Special Ignitor Loop 58.   Since there are many different vehicle types (e.g. truck, bus, firetruck or ambulance), the ignitor loop configuration …";
CM_ SG_ 2633832958 SpecialIgnitorLoop59Resistance "Resistance of Special Ignitor Loop 59.   Since there are many different vehicle types (e.g. truck, bus, firetruck or ambulance), the ignitor loop configuration …";
CM_ SG_ 2633832958 SpecialIgnitorLoop5Resistance "Resistance of Special Ignitor Loop 5.   Since there are many different vehicle types (e.g. truck, bus, firetruck or ambulance), the ignitor loop configuration h…";
CM_ SG_ 2633832958 SpecialIgnitorLoop60Resistance "Resistance of Special Ignitor Loop 60.   Since there are many different vehicle types (e.g. truck, bus, firetruck or ambulance), the ignitor loop configuration …";
CM_ SG_ 2633832958 SpecialIgnitorLoop61Resistance "Resistance of Special Ignitor Loop 61.   Since there are many different vehicle types (e.g. truck, bus, firetruck or ambulance), the ignitor loop configuration …";
CM_ SG_ 2633832958 SpecialIgnitorLoop62Resistance "Resistance of Special Ignitor Loop 62.   Since there are many different vehicle types (e.g. truck, bus, firetruck or ambulance), the ignitor loop configuration …";
CM_ SG_ 2633832958 SpecialIgnitorLoop63Resistance "Resistance of Special Ignitor Loop 63.   Since there are many different vehicle types (e.g. truck, bus, firetruck or ambulance), the ignitor loop configuration …";
CM_ SG_ 2633832958 SpecialIgnitorLoop64Resistance "Resistance of Special Ignitor Loop 64.   Since there are many different vehicle types (e.g. truck, bus, firetruck or ambulance), the ignitor loop configuration …";
CM_ SG_ 2633832958 SpecialIgnitorLoop65Resistance "Resistance of Special Ignitor Loop 65.   Since there are many different vehicle types (e.g. truck, bus, firetruck or ambulance), the ignitor loop configuration …";
CM_ SG_ 2633832958 SpecialIgnitorLoop66Resistance "Resistance of Special Ignitor Loop 66.   Since there are many different vehicle types (e.g. truck, bus, firetruck or ambulance), the ignitor loop configuration …";
CM_ SG_ 2633832958 SpecialIgnitorLoop67Resistance "Resistance of Special Ignitor Loop 67.   Since there are many different vehicle types (e.g. truck, bus, firetruck or ambulance), the ignitor loop configuration …";
CM_ SG_ 2633832958 SpecialIgnitorLoop68Resistance "Resistance of Special Ignitor Loop 68.   Since there are many different vehicle types (e.g. truck, bus, firetruck or ambulance), the ignitor loop configuration …";
CM_ SG_ 2633832958 SpecialIgnitorLoop69Resistance "Resistance of Special Ignitor Loop 69.   Since there are many different vehicle types (e.g. truck, bus, firetruck or ambulance), the ignitor loop configuration …";
CM_ SG_ 2633832958 SpecialIgnitorLoop6Resistance "Resistance of Special Ignitor Loop 6.   Since there are many different vehicle types (e.g. truck, bus, firetruck or ambulance), the ignitor loop configuration h…";
CM_ SG_ 2633832958 SpecialIgnitorLoop70Resistance "Resistance of Special Ignitor Loop 70.   Since there are many different vehicle types (e.g. truck, bus, firetruck or ambulance), the ignitor loop configuration …";
CM_ SG_ 2633832958 SpecialIgnitorLoop71Resistance "Resistance of Special Ignitor Loop 71.   Since there are many different vehicle types (e.g. truck, bus, firetruck or ambulance), the ignitor loop configuration …";
CM_ SG_ 2633832958 SpecialIgnitorLoop72Resistance "Resistance of Special Ignitor Loop 72.   Since there are many different vehicle types (e.g. truck, bus, firetruck or ambulance), the ignitor loop configuration …";
CM_ SG_ 2633832958 SpecialIgnitorLoop73Resistance "Resistance of Special Ignitor Loop 73.   Since there are many different vehicle types (e.g. truck, bus, firetruck or ambulance), the ignitor loop configuration …";
CM_ SG_ 2633832958 SpecialIgnitorLoop74Resistance "Resistance of Special Ignitor Loop 74.   Since there are many different vehicle types (e.g. truck, bus, firetruck or ambulance), the ignitor loop configuration …";
CM_ SG_ 2633832958 SpecialIgnitorLoop75Resistance "Resistance of Special Ignitor Loop 75.   Since there are many different vehicle types (e.g. truck, bus, firetruck or ambulance), the ignitor loop configuration …";
CM_ SG_ 2633832958 SpecialIgnitorLoop76Resistance "Resistance of Special Ignitor Loop 76.   Since there are many different vehicle types (e.g. truck, bus, firetruck or ambulance), the ignitor loop configuration …";
CM_ SG_ 2633832958 SpecialIgnitorLoop77Resistance "Resistance of Special Ignitor Loop 77.   Since there are many different vehicle types (e.g. truck, bus, firetruck or ambulance), the ignitor loop configuration …";
CM_ SG_ 2633832958 SpecialIgnitorLoop78Resistance "Resistance of Special Ignitor Loop 78.   Since there are many different vehicle types (e.g. truck, bus, firetruck or ambulance), the ignitor loop configuration …";
CM_ SG_ 2633832958 SpecialIgnitorLoop79Resistance "Resistance of Special Ignitor Loop 79.   Since there are many different vehicle types (e.g. truck, bus, firetruck or ambulance), the ignitor loop configuration …";
CM_ SG_ 2633832958 SpecialIgnitorLoop7Resistance "Resistance of Special Ignitor Loop 7.   Since there are many different vehicle types (e.g. truck, bus, firetruck or ambulance), the ignitor loop configuration h…";
CM_ SG_ 2633832958 SpecialIgnitorLoop80Resistance "Resistance of Special Ignitor Loop 80.   Since there are many different vehicle types (e.g. truck, bus, firetruck or ambulance), the ignitor loop configuration …";
CM_ SG_ 2633832958 SpecialIgnitorLoop81Resistance "Resistance of Special Ignitor Loop 81.   Since there are many different vehicle types (e.g. truck, bus, firetruck or ambulance), the ignitor loop configuration …";
CM_ SG_ 2633832958 SpecialIgnitorLoop82Resistance "Resistance of Special Ignitor Loop 82.   Since there are many different vehicle types (e.g. truck, bus, firetruck or ambulance), the ignitor loop configuration …";
CM_ SG_ 2633832958 SpecialIgnitorLoop83Resistance "Resistance of Special Ignitor Loop 83.   Since there are many different vehicle types (e.g. truck, bus, firetruck or ambulance), the ignitor loop configuration …";
CM_ SG_ 2633832958 SpecialIgnitorLoop84Resistance "Resistance of Special Ignitor Loop 84.   Since there are many different vehicle types (e.g. truck, bus, firetruck or ambulance), the ignitor loop configuration …";
CM_ SG_ 2633832958 SpecialIgnitorLoop85Resistance "Resistance of Special Ignitor Loop 85.   Since there are many different vehicle types (e.g. truck, bus, firetruck or ambulance), the ignitor loop configuration …";
CM_ SG_ 2633832958 SpecialIgnitorLoop86Resistance "Resistance of Special Ignitor Loop 86.   Since there are many different vehicle types (e.g. truck, bus, firetruck or ambulance), the ignitor loop configuration …";
CM_ SG_ 2633832958 SpecialIgnitorLoop87Resistance "Resistance of Special Ignitor Loop 87.   Since there are many different vehicle types (e.g. truck, bus, firetruck or ambulance), the ignitor loop configuration …";
CM_ SG_ 2633832958 SpecialIgnitorLoop88Resistance "Resistance of Special Ignitor Loop 88.   Since there are many different vehicle types (e.g. truck, bus, firetruck or ambulance), the ignitor loop configuration …";
CM_ SG_ 2633832958 SpecialIgnitorLoop89Resistance "Resistance of Special Ignitor Loop 89.   Since there are many different vehicle types (e.g. truck, bus, firetruck or ambulance), the ignitor loop configuration …";
CM_ SG_ 2633832958 SpecialIgnitorLoop8Resistance "Resistance of Special Ignitor Loop 8.   Since there are many different vehicle types (e.g. truck, bus, firetruck or ambulance), the ignitor loop configuration h…";
CM_ SG_ 2633832958 SpecialIgnitorLoop90Resistance "Resistance of Special Ignitor Loop 90.   Since there are many different vehicle types (e.g. truck, bus, firetruck or ambulance), the ignitor loop configuration …";
CM_ SG_ 2633832958 SpecialIgnitorLoop9Resistance "Resistance of Special Ignitor Loop 9.   Since there are many different vehicle types (e.g. truck, bus, firetruck or ambulance), the ignitor loop configuration h…";
CM_ BO_ 2633853438 "Axle Group Calibration Weights";
CM_ SG_ 2633853438 AdditionalAxleGroupLocation "Location of the axle group, listed from front of the vehicle to rear.  If the value of SPN 4074 is 15, then this SPN is used to indicate the axle group referred…";
CM_ SG_ 2633853438 AxleGroupEmptyWeightCalibration "The empty weight calibration measurement of an axle group…";
CM_ SG_ 2633853438 AxleGroupFullWeightCalibration "The full weight calibration measurement of an axle group…";
CM_ SG_ 2633853438 AxleGroupLocation "Specific axle group used in conjunction with and when communicating the axle group calibration, listed from the front of the vehicle to the rear.If the value of…";
CM_ BO_ 2633861886 "SAE J2012 DTC Display";
CM_ SG_ 2633861886 J2012DTC "Five character ASCII SAE J2012 DTC, sent most significant byte first.…";
CM_ SG_ 2633861886 J2012DTCOccurrenceCount "Number of occurrences of the respective SAE J2012 DTC being conveyed.If more than 126 occurrences happen the value shall be set to 126.If the occurrence count i…";
CM_ SG_ 2633861886 J2012DTCStatus "Indicates if the respective SAE J2012 DTC is active or previously active.0b = DTC is previously active1b = DTC is active…";
CM_ SG_ 2633861886 NumberofJ2012DTCs "The number J2012 DTCs being conveyed in PGN 64906.  If the value of this parameter is zero, the device broadcasting PGN 64906 has no active or previously active…";
CM_ BO_ 2633869310 "Voltage Regulator Operating Mode";
CM_ SG_ 2633869310 VltgRgltrLdCmpnstnMd "State signal indicating the voltage regulator load compensation mode.  Load compensation is when the voltage is adjusted based on the magnitude of load current0…";
CM_ SG_ 2633869310 VltgRgltrUndrfrqnCmpnstnnld "State signal indicating the operating mode for underfrequency compensation.00b = Underfrequency compensation disabled01b = Underfrequency compensation enabled10…";
CM_ SG_ 2633869310 VltgRgltrVArPwrFtrprtngmd "State signal indicating the operating mode for the Voltage regulator VAr/Power Factor 000b = VAr/Power Factor regulation disabled001b = Power factor regulation …";
CM_ SG_ 2633869310 VoltageRegulatorEnabled "State signal indicating the Voltage Regulator is enabled.  This parameter indicates whether the regulator is regulating or not regulating generator output volta…";
CM_ SG_ 2633869310 VoltageRegulatorSoftStartState "State signal indicating the mode of the Voltage regulator soft start function.  Soft start controls the generator voltage overshoot by controlling the rate of r…";
CM_ BO_ 2633878014 "Electronic Control Module Information";
CM_ SG_ 2633878014 TtlCntfCnfgrtnChngsMd "Total number of times changes have been made to any of the configurable parameters.…";
CM_ BO_ 2633880062 "FMS-standard Interface Identity/Capabilities";
CM_ SG_ 2633880062 FMSstandardDiagnosticsSupported "Status signal which indicates if the FMS Vehicle Interface (FMS Gateway) supports the handling of diagnostic messages from the vehicle network onto the FMS netw…";
CM_ SG_ 2633880062 FMSstandardRequestsSupported "Status signal which indicates if the FMS Vehicle Interface (FMS Gateway) will respond to requests from the FMS device for the PGNs listed in the FMS Interface S…";
CM_ SG_ 2633880062 FMSstandardSWversionsupported "Information that identifies which issue level of the FMS-standard document the software included in the FMS gateway supports. Four bytes, representing xx.yy typ…";
CM_ BO_ 2633883646 "Front Wheel Drive Status";
CM_ SG_ 2633883646 FrontWheelDriveActuatorStatus "Feedback on the front wheel drive actuator.00b = Front Wheel Drive Actuator not engaged01b = Front Wheel Drive Actuator engaged10b = Error11b = Not Available…";
CM_ BO_ 2633911806 "Total Averaged Information";
CM_ SG_ 2633911806 EngineTotalAverageFuelEconomy "Average fuel economy, equal to total vehicle distance divided by total fuel used, over the life of the engine…";
CM_ SG_ 2633911806 EngineTotalAverageFuelRate "Average fuel rate, equal to total fuel used divided by total engine hours, over the life of the engine…";
CM_ BO_ 2633922558 "Auxiliary Pressures";
CM_ SG_ 2633922558 AuxiliaryGagePressureReading1 "Identifies the current gage pressure (relative to atmosphere) that is configured uniquely per application.  Not to be used in place of defined parameters.…";
CM_ SG_ 2633922558 AuxiliaryVacuumPressureReading "Identifies the current vacuum pressure (relative to atmosphere) that is configured uniquely per application.  Not to be used in place of defined parameters.…";
CM_ SG_ 2633922558 AxlrAsltPrssrRdng "Identifies the current absolute pressure (relative to 0 pressure) that is configured uniquely per application.  Not to be used in place of defined parameters.…";
CM_ BO_ 2633922814 "Tire Pressure Control Unit Mode and Status";
CM_ SG_ 2633922814 DriveChannelMode "Indicates the functional mode of trailer/tag channel of the tire pressure control system.  0000b = Maintain0001b = Inflate0010b = Deflate0011b = Confirm0100b = …";
CM_ SG_ 2633922814 PCUControlSolenoidStatus "Current state of the control solenoid used to implement a tire pressure control system in its pneumatic control unit (PCU).00b = Off01b = On10b = Error11b = Not…";
CM_ SG_ 2633922814 PCUDeflateSolenoidStatus "Current state of the deflate solenoid used to implement a tire pressure control system in its pneumatic control unit (PCU).00b = Off01b = On10b = Error11b = Not…";
CM_ SG_ 2633922814 PCUDriveSolenoidStatus "Current state of the drive solenoid used to implement a tire pressure control system in its pneumatic control unit (PCU).00b = Off01b = On10b = Error11b = Not a…";
CM_ SG_ 2633922814 PCUSteerSolenoidStatus "Current state of the steer solenoid used to implement a tire pressure control system in its pneumatic control unit (PCU).00b = Off01b = On10b = Error11b = Not a…";
CM_ SG_ 2633922814 PCUSupplySolenoidStatus "Current state of the supply solenoid used to implement a tire pressure control system in its pneumatic control unit (PCU).00b = Off01b = On10b = Error11b = Not …";
CM_ SG_ 2633922814 PCUTrlrTgrPshSlndStts "Current state of the trailer, tag, or push solenoid used to implement a tire pressure control system in its pneumatic control unit (PCU).00b = Off01b = On10b = …";
CM_ SG_ 2633922814 SteerChannelMode "Indicates the functional mode of steer channel of the tire pressure control system. 0000b = Maintain0001b = Inflate0010b = Deflate0011b = Confirm0100b = Inflate…";
CM_ SG_ 2633922814 TirePressureCheckInterval "The interval at which the system will check the tire pressures (e.g., 5, 10, 15 min.).NOTE - A value of 0 indicates continuous (real time) pressure readings.…";
CM_ SG_ 2633922814 TirePressureSupplySwitchStatus "Current state of an open/closed type switch used to determine if adequate pressure exists for system implementation.00b = Off01b = On10b = Error11b = Not availa…";
CM_ SG_ 2633922814 TrailertagChannelMode "Indicates the functional mode of trailer/tag channel of the tire pressure control system.0000b = Maintain0001b = Inflate0010b = Deflate0011b = Confirm0100b = In…";
CM_ BO_ 2633923070 "Tire Pressure Control Unit Target Pressures";
CM_ SG_ 2633923070 DriveChannelTirePressureTarget "The tire pressure control system’s target gage pressure for the drive group of tires.…";
CM_ SG_ 2633923070 SteerChannelTirePressureTarget "The tire pressure control system’s target gage pressure for the steer group of tires.…";
CM_ SG_ 2633923070 TrlrTgOrPshChnnlTrPrssrTrgt "The tire pressure control system’s target gage pressure for the trailer, tag, or push group of tires.…";
CM_ BO_ 2633923326 "Tire Pressure Control Unit Current Pressures";
CM_ SG_ 2633923326 DriveChannelTirePressure "The latest gage pressure reading of the drive group of tires, as opposed to the pressure in each tire.…";
CM_ SG_ 2633923326 SteerChannelTirePressure "The latest gage pressure reading of the steer group of tires, as opposed to the pressure in each tire.…";
CM_ SG_ 2633923326 TrlrTgOrPshChnnlTrPrssr "The latest gage pressure reading of the trailer, tag, or push group of tires, as opposed to the pressure in each tire.…";
CM_ BO_ 2633923582 "Combustion Time 1";
CM_ SG_ 2633923582 EngineCylinder1CombustionTime "The amount of time from when the ignition of the fuel is initiated to when the fuel is completely ignited (i.e., the flame front has propagated across the cylin…";
CM_ SG_ 2633923582 EngineCylinder2CombustionTime "The amount of time from when the ignition of the fuel is initiated to when the fuel is completely ignited (i.e., the flame front has propagated across the cylin…";
CM_ SG_ 2633923582 EngineCylinder3CombustionTime "The amount of time from when the ignition of the fuel is initiated to when the fuel is completely ignited (i.e., the flame front has propagated across the cylin…";
CM_ SG_ 2633923582 EngineCylinder4CombustionTime "The amount of time from when the ignition of the fuel is initiated to when the fuel is completely ignited (i.e., the flame front has propagated across the cylin…";
CM_ BO_ 2633923838 "Combustion Time 2";
CM_ SG_ 2633923838 EngineCylinder5CombustionTime "The amount of time from when the ignition of the fuel is initiated to when the fuel is completely ignited (i.e., the flame front has propagated across the cylin…";
CM_ SG_ 2633923838 EngineCylinder6CombustionTime "The amount of time from when the ignition of the fuel is initiated to when the fuel is completely ignited (i.e., the flame front has propagated across the cylin…";
CM_ SG_ 2633923838 EngineCylinder7CombustionTime "The amount of time from when the ignition of the fuel is initiated to when the fuel is completely ignited (i.e., the flame front has propagated across the cylin…";
CM_ SG_ 2633923838 EngineCylinder8CombustionTime "The amount of time from when the ignition of the fuel is initiated to when the fuel is completely ignited (i.e., the flame front has propagated across the cylin…";
CM_ BO_ 2633924094 "Combustion Time 3";
CM_ SG_ 2633924094 EngineCylinder10CombustionTime "The amount of time from when the ignition of the fuel is initiated to when the fuel is completely ignited (i.e., the flame front has propagated across the cylin…";
CM_ SG_ 2633924094 EngineCylinder11CombustionTime "The amount of time from when the ignition of the fuel is initiated to when the fuel is completely ignited (i.e., the flame front has propagated across the cylin…";
CM_ SG_ 2633924094 EngineCylinder12CombustionTime "The amount of time from when the ignition of the fuel is initiated to when the fuel is completely ignited (i.e., the flame front has propagated across the cylin…";
CM_ SG_ 2633924094 EngineCylinder9CombustionTime "The amount of time from when the ignition of the fuel is initiated to when the fuel is completely ignited (i.e., the flame front has propagated across the cylin…";
CM_ BO_ 2633924350 "Combustion Time 4";
CM_ SG_ 2633924350 EngineCylinder13CombustionTime "The amount of time from when the ignition of the fuel is initiated to when the fuel is completely ignited (i.e., the flame front has propagated across the cylin…";
CM_ SG_ 2633924350 EngineCylinder14CombustionTime "The amount of time from when the ignition of the fuel is initiated to when the fuel is completely ignited (i.e., the flame front has propagated across the cylin…";
CM_ SG_ 2633924350 EngineCylinder15CombustionTime "The amount of time from when the ignition of the fuel is initiated to when the fuel is completely ignited (i.e., the flame front has propagated across the cylin…";
CM_ SG_ 2633924350 EngineCylinder16CombustionTime "The amount of time from when the ignition of the fuel is initiated to when the fuel is completely ignited (i.e., the flame front has propagated across the cylin…";
CM_ BO_ 2633924606 "Combustion Time 5";
CM_ SG_ 2633924606 EngineCylinder17CombustionTime "The amount of time from when the ignition of the fuel is initiated to when the fuel is completely ignited (i.e., the flame front has propagated across the cylin…";
CM_ SG_ 2633924606 EngineCylinder18CombustionTime "The amount of time from when the ignition of the fuel is initiated to when the fuel is completely ignited (i.e., the flame front has propagated across the cylin…";
CM_ SG_ 2633924606 EngineCylinder19CombustionTime "The amount of time from when the ignition of the fuel is initiated to when the fuel is completely ignited (i.e., the flame front has propagated across the cylin…";
CM_ SG_ 2633924606 EngineCylinder20CombustionTime "The amount of time from when the ignition of the fuel is initiated to when the fuel is completely ignited (i.e., the flame front has propagated across the cylin…";
CM_ BO_ 2633924862 "Combustion Time 6";
CM_ SG_ 2633924862 EngineAverageCombustionTime "The average combustion time of all cylinders of an engine.…";
CM_ SG_ 2633924862 EngineDesiredCombustionTime "The desired combustion time based upon engine load and speed lookup maps.…";
CM_ BO_ 2633925118 "Fuel Information 2 (Gaseous)";
CM_ SG_ 2633925118 EngineFuelFlowRate1 "The rate at which the fuel is flowing through a fuel valve.…";
CM_ SG_ 2633925118 EngineFuelFlowRate2 "The rate at which the fuel is flowing through a fuel valve.…";
CM_ SG_ 2633925118 EngineFuelValve1Position "The position of a gaseous fuel valve that is metering the fuel flow to the engine.  0% indicates no fuel flow through valve and 100% means maximum fuel flow thr…";
CM_ SG_ 2633925118 EngineFuelValve2Position "The position of a gaseous fuel valve that is metering the fuel flow to the engine.  0% indicates no fuel flow through valve and 100% means maximum fuel flow thr…";
CM_ SG_ 2633925118 EngnFlVlv1CmmnddPstn "The commanded position of the first fuel valve that is metering the fuel flow to the engine.…";
CM_ SG_ 2633925118 EngnFlVlv2CmmnddPstn "The commanded position of the second fuel valve that is metering the fuel flow to the engine.…";
CM_ BO_ 2633925374 "Ignition Timing 1";
CM_ SG_ 2633925374 EngineCylinder1IgnitionTiming "The ignition timing (SI engines) or main fuel injection timing (CI engines) of the cylinder. Positive values indicate an increasingly advanced timing from TDC.…";
CM_ SG_ 2633925374 EngineCylinder2IgnitionTiming "The ignition timing (SI engines) or main fuel injection timing (CI engines) of the cylinder. Positive values indicate an increasingly advanced timing from TDC.…";
CM_ SG_ 2633925374 EngineCylinder3IgnitionTiming "The ignition timing (SI engines) or main fuel injection timing (CI engines) of the cylinder. Positive values indicate an increasingly advanced timing from TDC.…";
CM_ SG_ 2633925374 EngineCylinder4IgnitionTiming "The ignition timing (SI engines) or main fuel injection timing (CI engines) of the cylinder. Positive values indicate an increasingly advanced timing from TDC.…";
CM_ BO_ 2633925630 "Ignition Timing 2";
CM_ SG_ 2633925630 EngineCylinder5IgnitionTiming "The ignition timing (SI engines) or main fuel injection timing (CI engines) of the cylinder. Positive values indicate an increasingly advanced timing from TDC.…";
CM_ SG_ 2633925630 EngineCylinder6IgnitionTiming "The ignition timing (SI engines) or main fuel injection timing (CI engines) of the cylinder. Positive values indicate an increasingly advanced timing from TDC.…";
CM_ SG_ 2633925630 EngineCylinder7IgnitionTiming "The ignition timing (SI engines) or main fuel injection timing (CI engines) of the cylinder. Positive values indicate an increasingly advanced timing from TDC.…";
CM_ SG_ 2633925630 EngineCylinder8IgnitionTiming "The ignition timing (SI engines) or main fuel injection timing (CI engines) of the cylinder. Positive values indicate an increasingly advanced timing from TDC.…";
CM_ BO_ 2633925886 "Ignition Timing 3";
CM_ SG_ 2633925886 EngineCylinder10IgnitionTiming "The ignition timing (SI engines) or main fuel injection timing (CI engines) of the cylinder. Positive values indicate an increasingly advanced timing from TDC.…";
CM_ SG_ 2633925886 EngineCylinder11IgnitionTiming "The ignition timing (SI engines) or main fuel injection timing (CI engines) of the cylinder. Positive values indicate an increasingly advanced timing from TDC.…";
CM_ SG_ 2633925886 EngineCylinder12IgnitionTiming "The ignition timing (SI engines) or main fuel injection timing (CI engines) of the cylinder. Positive values indicate an increasingly advanced timing from TDC.…";
CM_ SG_ 2633925886 EngineCylinder9IgnitionTiming "The ignition timing (SI engines) or main fuel injection timing (CI engines) of the cylinder. Positive values indicate an increasingly advanced timing from TDC.…";
CM_ BO_ 2633926142 "Ignition Timing 4";
CM_ SG_ 2633926142 EngineCylinder13IgnitionTiming "The ignition timing (SI engines) or main fuel injection timing (CI engines) of the cylinder. Positive values indicate an increasingly advanced timing from TDC.…";
CM_ SG_ 2633926142 EngineCylinder14IgnitionTiming "The ignition timing (SI engines) or main fuel injection timing (CI engines) of the cylinder. Positive values indicate an increasingly advanced timing from TDC.…";
CM_ SG_ 2633926142 EngineCylinder15IgnitionTiming "The ignition timing (SI engines) or main fuel injection timing (CI engines) of the cylinder. Positive values indicate an increasingly advanced timing from TDC.…";
CM_ SG_ 2633926142 EngineCylinder16IgnitionTiming "The ignition timing (SI engines) or main fuel injection timing (CI engines) of the cylinder. Positive values indicate an increasingly advanced timing from TDC.…";
CM_ BO_ 2633926398 "Ignition Timing 5";
CM_ SG_ 2633926398 EngineCylinder17IgnitionTiming "The ignition timing (SI engines) or main fuel injection timing (CI engines) of the cylinder. Positive values indicate an increasingly advanced timing from TDC.…";
CM_ SG_ 2633926398 EngineCylinder18IgnitionTiming "The ignition timing (SI engines) or main fuel injection timing (CI engines) of the cylinder. Positive values indicate an increasingly advanced timing from TDC.…";
CM_ SG_ 2633926398 EngineCylinder19IgnitionTiming "The ignition timing (SI engines) or main fuel injection timing (CI engines) of the cylinder. Positive values indicate an increasingly advanced timing from TDC.…";
CM_ SG_ 2633926398 EngineCylinder20IgnitionTiming "The ignition timing (SI engines) or main fuel injection timing (CI engines) of the cylinder. Positive values indicate an increasingly advanced timing from TDC.…";
CM_ BO_ 2633926654 "Ignition Timing 6";
CM_ SG_ 2633926654 EngineActualIgnitionTiming "The actual ignition timing at the current engine conditions. This parameter may or may not be equal to one of the desired timing parameters (see SPNs 1433-1435)…";
CM_ SG_ 2633926654 EngineDesiredIgnitionTiming1 "A programmable timing value specific to the engine’s application. Factors affecting this value include both fuel type and the nature of the load being driven. P…";
CM_ SG_ 2633926654 EngineDesiredIgnitionTiming2 "A programmable timing value specific to the engine’s application. Factors affecting this value include both fuel type and the nature of the load being driven. P…";
CM_ SG_ 2633926654 EngineDesiredIgnitionTiming3 "A programmable timing value specific to the engine’s application. Factors affecting this value include both fuel type and the nature of the load being driven. P…";
CM_ BO_ 2633926910 "Ignition Transformer Secondary Output 1";
CM_ SG_ 2633926910 EngnClndr1IgntnTrnsfrmrSndrOtpt "This parameter indicates the relative intensity of the secondary output voltage of the ignition transformer.…";
CM_ SG_ 2633926910 EngnClndr2IgntnTrnsfrmrSndrOtpt "This parameter indicates the relative intensity of the secondary output voltage of the ignition transformer.…";
CM_ SG_ 2633926910 EngnClndr3IgntnTrnsfrmrSndrOtpt "This parameter indicates the relative intensity of the secondary output voltage of the ignition transformer.…";
CM_ SG_ 2633926910 EngnClndr4IgntnTrnsfrmrSndrOtpt "This parameter indicates the relative intensity of the secondary output voltage of the ignition transformer.…";
CM_ SG_ 2633926910 EngnClndr5IgntnTrnsfrmrSndrOtpt "This parameter indicates the relative intensity of the secondary output voltage of the ignition transformer.…";
CM_ SG_ 2633926910 EngnClndr6IgntnTrnsfrmrSndrOtpt "This parameter indicates the relative intensity of the secondary output voltage of the ignition transformer.…";
CM_ SG_ 2633926910 EngnClndr7IgntnTrnsfrmrSndrOtpt "This parameter indicates the relative intensity of the secondary output voltage of the ignition transformer.…";
CM_ SG_ 2633926910 EngnClndr8IgntnTrnsfrmrSndrOtpt "This parameter indicates the relative intensity of the secondary output voltage of the ignition transformer.…";
CM_ BO_ 2633927166 "Ignition Transformer Secondary Output 2";
CM_ SG_ 2633927166 ECd10ItTsSdOtpt "This parameter indicates the relative intensity of the secondary output voltage of the ignition transformer.…";
CM_ SG_ 2633927166 ECd11ItTsSdOtpt "This parameter indicates the relative intensity of the secondary output voltage of the ignition transformer.…";
CM_ SG_ 2633927166 ECd12ItTsSdOtpt "This parameter indicates the relative intensity of the secondary output voltage of the ignition transformer.…";
CM_ SG_ 2633927166 ECd13ItTsSdOtpt "This parameter indicates the relative intensity of the secondary output voltage of the ignition transformer.…";
CM_ SG_ 2633927166 ECd14ItTsSdOtpt "This parameter indicates the relative intensity of the secondary output voltage of the ignition transformer.…";
CM_ SG_ 2633927166 ECd15ItTsSdOtpt "This parameter indicates the relative intensity of the secondary output voltage of the ignition transformer.…";
CM_ SG_ 2633927166 ECd16ItTsSdOtpt "This parameter indicates the relative intensity of the secondary output voltage of the ignition transformer.…";
CM_ SG_ 2633927166 EngnClndr9IgntnTrnsfrmrSndrOtpt "This parameter indicates the relative intensity of the secondary output voltage of the ignition transformer.…";
CM_ BO_ 2633927422 "Ignition Transformer Secondary Output 3";
CM_ SG_ 2633927422 ECd17ItTsSdOtpt "This parameter indicates the relative intensity of the secondary output voltage of the ignition transformer.…";
CM_ SG_ 2633927422 ECd18ItTsSdOtpt "This parameter indicates the relative intensity of the secondary output voltage of the ignition transformer.…";
CM_ SG_ 2633927422 ECd19ItTsSdOtpt "This parameter indicates the relative intensity of the secondary output voltage of the ignition transformer.…";
CM_ SG_ 2633927422 ECd20ItTsSdOtpt "This parameter indicates the relative intensity of the secondary output voltage of the ignition transformer.…";
CM_ BO_ 2633927678 "Gaseous Fuel Pressure 1";
CM_ SG_ 2633927678 EngnArtFlDffrntlPrssr "The differential pressure between the gaseous fuel and the air intake manifold.…";
CM_ SG_ 2633927678 EngnFlVlv1DffrntlPrssr "The differential pressure between the intake and the outlet of the first or only gaseous fuel valve.See SPN 8494 for alternate range and resolution.…";
CM_ SG_ 2633927678 EngnFlVlv1IntkAsltPrssr "The absolute pressure of gas on the intake side of the first system control valve.  See SPN 3466 for Engine Fuel Valve 2, 7505 for Engine Fuel Valve 3 & 7506 fo…";
CM_ SG_ 2633927678 EngnFlVlv1OtltAsltPrssr "Absolute Pressure of gas on outlet side of the first or only fuel system control valve.  See SPN 3469 for the second fuel control valve.…";
CM_ BO_ 2633927934 "Auxiliary Analog Information";
CM_ SG_ 2633927934 AuxiliaryLevel "Level measured by a sensor.…";
CM_ SG_ 2633927934 AuxiliaryPressure1 "Pressure measured by auxiliary pressure sensor #1.  Not to be used in place of existing SPNs.…";
CM_ SG_ 2633927934 AuxiliaryPressure2 "Pressure measured by auxiliary pressure sensor #2.  Not to be used in place of existing SPNs.…";
CM_ SG_ 2633927934 AuxiliaryTemperature1 "Temperature measured by auxiliary temperature sensor #1.  Not to be used in place of existing SPNs.…";
CM_ SG_ 2633927934 AuxiliaryTemperature2 "Temperature measured by auxiliary temperature sensor #2.  Not to be used in place of existing SPNs.…";
CM_ SG_ 2633927934 RelativeHumidity "Measures humidity of combustion air prior to entry into turbocharger…";
CM_ BO_ 2633928446 "Service 2";
CM_ SG_ 2633928446 ServiceComponentIdentification "Identification of component needing service.  See Table SPN911_A.…";
CM_ SG_ 2633928446 TimeSinceLastService "The vehicle operation time since the last service was performed.  The type of service information is identified by the service component identification number.…";
CM_ BO_ 2633929214 "Fuel Leakage";
CM_ SG_ 2633929214 EngineFluidBundLevel "Ratio of the volume of engine fluid within the bund containment frame to the maximum capacity of the bund containment frame. The bund containment frame is used …";
CM_ SG_ 2633929214 EngineFuelLeakage1 "Status signal which indicates fuel leakage in the fuel rail of the engine. Location can be either before or after the fuel pump.  00b = no leakage detected01b =…";
CM_ SG_ 2633929214 EngineFuelLeakage2 "Status signal which indicates fuel leakage in the fuel rail of the engine. Location can be either before or after the fuel pump.  00b = no leakage detected01b =…";
CM_ BO_ 2633929470 "Engine Information 1";
CM_ SG_ 2633929470 EngineExhaustPressure1 "Gage pressure of the exhaust gases as measured at the turbine intake of the turbocharger. This SPN to be used for inline engines or exhaust bank 1 of multiple b…";
CM_ SG_ 2633929470 EngineFuelRackPosition "Measured position of the engine fuel rack.  A value of 0% rack represents no fueling and a value of 100% rack represents maximum fueling.…";
CM_ SG_ 2633929470 EngineOilFilterIntakePressure "Gage pressure of the engine oil before the oil reaches the oil filter.   See SPN 7470 for alternate resolution.…";
CM_ SG_ 2633929470 EngnFlSstm1GsMssFlwRt "Gas mass flow rate delivered to an engine through its first fuel control system.  See SPN 3467 for the second fuel control system.…";
CM_ SG_ 2633929470 InstntnsEstmtdBrkPwr "Estimate of the power developed by the engine.…";
CM_ BO_ 2633929726 "Engine Electrical System/Module Information";
CM_ SG_ 2633929726 ElectricalLoad "Electrical power delivered by the engine to the electrical system connected to the generator.…";
CM_ SG_ 2633929726 EngineTurningGearEngaged "Status signal which indicates that the turning gear is engaged.  The turning gear is used to turn the flywheel/crankshaft, for maintenance purposes, while the e…";
CM_ SG_ 2633929726 SafetyWireStatus "Status signal which indicates that the safety wire has been activated.  When the safety wire is activated, the engine will not operate.  This is used for mainte…";
CM_ BO_ 2633930238 "Rebuild Information";
CM_ SG_ 2633930238 EngineOperationTimeSinceRebuild "The time in engine operation since the last engine rebuild.…";
CM_ BO_ 2633931774 "Turbocharger Information 1";
CM_ SG_ 2633931774 EngineTurbocharger2Speed "Rotational velocity of rotor in the turbocharger.…";
CM_ SG_ 2633931774 EngineTurbocharger3Speed "Rotational velocity of rotor in the turbocharger.…";
CM_ SG_ 2633931774 EngineTurbocharger4Speed "Rotational velocity of rotor in the turbocharger.…";
CM_ SG_ 2633931774 EngnTrhrgrLOlPrssr2 "Gage pressure of oil in turbocharger lubrication system.…";
CM_ BO_ 2633932798 "Exhaust Port Temperature 5";
CM_ SG_ 2633932798 EngnExhstGsPrt17Tmprtr "Temperature at the cylinder exhaust port of the engine.…";
CM_ SG_ 2633932798 EngnExhstGsPrt18Tmprtr "Temperature at the cylinder exhaust port of the engine.…";
CM_ SG_ 2633932798 EngnExhstGsPrt19Tmprtr "Temperature at the cylinder exhaust port of the engine.…";
CM_ SG_ 2633932798 EngnExhstGsPrt20Tmprtr "Temperature at the cylinder exhaust port of the engine.…";
CM_ BO_ 2633933310 "Exhaust Port Temperature 3";
CM_ SG_ 2633933310 EngnExhstGsPrt10Tmprtr "Temperature at the cylinder exhaust port of the engine.…";
CM_ SG_ 2633933310 EngnExhstGsPrt11Tmprtr "Temperature at the cylinder exhaust port of the engine.…";
CM_ SG_ 2633933310 EngnExhstGsPrt12Tmprtr "Temperature at the cylinder exhaust port of the engine.…";
CM_ SG_ 2633933310 EngnExhstGsPrt9Tmprtr "Temperature at the cylinder exhaust port of the engine.…";
CM_ BO_ 2633933566 "Exhaust Port Temperature 2";
CM_ SG_ 2633933566 EngnExhstGsPrt5Tmprtr "Temperature at the cylinder exhaust port of the engine.…";
CM_ SG_ 2633933566 EngnExhstGsPrt6Tmprtr "Temperature at the cylinder exhaust port of the engine.…";
CM_ SG_ 2633933566 EngnExhstGsPrt7Tmprtr "Temperature at the cylinder exhaust port of the engine.…";
CM_ SG_ 2633933566 EngnExhstGsPrt8Tmprtr "Temperature at the cylinder exhaust port of the engine.…";
CM_ BO_ 2633933822 "Exhaust Port Temperature 1";
CM_ SG_ 2633933822 EngnExhstGsPrt1Tmprtr "Temperature at the cylinder exhaust port of the engine.…";
CM_ SG_ 2633933822 EngnExhstGsPrt2Tmprtr "Temperature at the cylinder exhaust port of the engine.…";
CM_ SG_ 2633933822 EngnExhstGsPrt3Tmprtr "Temperature at the cylinder exhaust port of the engine.…";
CM_ SG_ 2633933822 EngnExhstGsPrt4Tmprtr "Temperature at the cylinder exhaust port of the engine.…";
CM_ BO_ 2633934334 "Intake Manifold Information 2";
CM_ SG_ 2633934334 EngnIntkMnfld2Tmprtr "Temperature of pre-combustion air found in intake manifold of engine air supply system.…";
CM_ SG_ 2633934334 EngnIntkMnfld3Tmprtr "Temperature of pre-combustion air found in intake manifold of engine air supply system.…";
CM_ SG_ 2633934334 EngnIntkMnfld4Tmprtr "Temperature of pre-combustion air found in intake manifold of engine air supply system.…";
CM_ SG_ 2633934334 EngnIntkMnfld5Tmprtr "Temperature of pre-combustion air found in intake manifold number 5 of engine air supply system.…";
CM_ SG_ 2633934334 EngnIntkMnfld6Tmprtr "Temperature of pre-combustion air found in intake manifold  number 6 of engine air supply system.…";
CM_ BO_ 2633934846 "Alternator Temperature 1";
CM_ SG_ 2633934846 EngnAltrntrBrng1Tmprtr "Temperature of the bearing inside the alternator.  Bearing 1 is the left or rear bearing.…";
CM_ SG_ 2633934846 EngnAltrntrBrng2Tmprtr "Temperature of the bearing inside the alternator.  Bearing 2 is the right or front bearing.…";
CM_ SG_ 2633934846 EngnAltrntrWndng1Tmprtr "Temperature of the windings inside the alternator.…";
CM_ SG_ 2633934846 EngnAltrntrWndng2Tmprtr "Temperature of the windings inside the alternator.…";
CM_ SG_ 2633934846 EngnAltrntrWndng3Tmprtr "Temperature of the windings inside the alternator.…";
CM_ SG_ 2633934846 EngnAltrntrWndng4Tmprtr "Temperature of this winding inside the alternator.…";
CM_ SG_ 2633934846 EngnAltrntrWndng5Tmprtr "Temperature of this winding inside the alternator.…";
CM_ SG_ 2633934846 EngnAltrntrWndng6Tmprtr "Temperature of this winding inside the alternator.…";
CM_ BO_ 2633935102 "Articulation Control";
CM_ SG_ 2633935102 ArticulationAngle "Angle of deflection of an articulated transit vehicle (rotation angle about the vehicles z-axis). A right turn (clockwise) is indicated with a positive angle an…";
CM_ SG_ 2633935102 ArticulationAngularVelocity "Angular velocity of deflection of an articulated transit vehicle (rotation angle about the vehicle's z-axis).  An increasing clockwise angle is indicated with a…";
CM_ BO_ 2633935358 "Exhaust Oxygen 1";
CM_ SG_ 2633935358 EngineActualExhaust1Oxygen "The actual amount of oxygen in the exhaust represented as a percentage by volume with respect to the total volume of exhaust gases leaving the engine.…";
CM_ SG_ 2633935358 EngineDesiredExhaustOxygen "The desired amount of oxygen in the exhaust represented as a percentage by volume with respect to the total volume of exhaust gases leaving the engine.…";
CM_ SG_ 2633935358 EngineDesiredRatedExhaustOxygen "The desired amount of oxygen in the exhaust at rated conditions represented as a percentage by volume with respect to the total volume of exhaust gases leaving …";
CM_ SG_ 2633935358 EngnExhstO2SnsrClsdLpOprtn "Indicates whether the engine is using the exhaust oxygen sensor to control the air/fuel ratio.00b = Engine not using the exhaust oxygen sensor (open loop)01b = …";
CM_ SG_ 2633935358 EngnExhstO2SnsrFlngCrrtn "The amount of fueling change required by the system based on the measured exhaust oxygen value compared to the maximum fueling change permitted by the system, e…";
CM_ BO_ 2633935614 "Alternate Fuel 2";
CM_ SG_ 2633935614 EFSstGsMssFwRtSsFCt "The amount of fuel the Gas Mass Flow Rate Sensor is sensing should be added or subtracted compared to the maximum amount of fuel the control system allows the s…";
CM_ SG_ 2633935614 EngnIntkMnfldDsrdAsltPrssr "The desired absolute intake manifold pressure (turbo boost limit) of the engine.…";
CM_ SG_ 2633935614 EngnTrhrgrWstgtVlvPstn "The position of the turbocharger wastegate valve (not the electronic wastegate control valve).…";
CM_ SG_ 2633935614 GaseousFuelCorrectionFactor "A correction to a predefined gaseous fuel energy (expressed in energy per unit volume) represented as a percentage.  The actual fuel energy used to control the …";
CM_ SG_ 2633935614 GssFlInjtnPlsCrrtnFtr "A correction to the gaseous fuel injection pulse (expressed in msec) represented as a percentage.  100% means no correction, higher values indicate increased pu…";
CM_ BO_ 2633935870 "Electronic Transmission Controller 6";
CM_ SG_ 2633935870 ClutchLifeRemaining "Signal which indicates the actual clutch life remaining in percent. One hundred percent means the clutch is brand new and zero percent means the clutch is at th…";
CM_ SG_ 2633935870 HighestPossibleGear "The transmission calculates this gear continuously.  Together with the lowest possible gear (see  SPN 1114), it enables a management computer to know the exact …";
CM_ SG_ 2633935870 LowestPossibleGear "The transmission calculates this gear continuously.  Together with the highest possible gear (see SPN 1115), it enables a management computer to know the exact …";
CM_ SG_ 2633935870 RecommendedGear "The transmission calculates this gear continuously.  In dangerous situations this gear may be selected to gain back vehicle control.…";
CM_ BO_ 2633936126 "Wheel Brake Lining Remaining Information";
CM_ SG_ 2633936126 BrkLnngRmnngFrntAxlLftWhl "The percentage of brake lining which can still be measured for the left wheel on the front axle.  100% represents new brake linings, 0% represents totally worn …";
CM_ SG_ 2633936126 BrkLnngRmnngFrntAxlRghtWhl "The percentage of brake lining which can still be measured for the right wheel on the front axle.  100% represents new brake linings, 0% represents totally worn…";
CM_ SG_ 2633936126 BrkLnngRmnngRrAxl1LftWhl "The percentage of brake lining which can still be measured for the left wheel on the rear axle #1.  100% represents new brake linings, 0% represents totally wor…";
CM_ SG_ 2633936126 BrkLnngRmnngRrAxl1RghtWhl "The percentage of brake lining which can still be measured for the right wheel on the rear axle #1.  100% represents new brake linings, 0% represents totally wo…";
CM_ SG_ 2633936126 BrkLnngRmnngRrAxl2LftWhl "The percentage of brake lining which can still be measured for the left wheel on the rear axle #2.  100% represents new brake linings, 0% represents totally wor…";
CM_ SG_ 2633936126 BrkLnngRmnngRrAxl2RghtWhl "The percentage of brake lining which can still be measured for the right wheel on the rear axle #2.  100% represents new brake linings, 0% represents totally wo…";
CM_ SG_ 2633936126 BrkLnngRmnngRrAxl3LftWhl "The percentage of brake lining which can still be measured for the left wheel on the rear axle #3.  100% represents new brake linings, 0% represents totally wor…";
CM_ SG_ 2633936126 BrkLnngRmnngRrAxl3RghtWhl "The percentage of brake lining which can still be measured for the right wheel on the rear axle #3.  100% represents new brake linings, 0% represents totally wo…";
CM_ BO_ 2633936894 "Fuel Consumption (Gaseous)";
CM_ SG_ 2633936894 TotalFuelUsedGaseous "Total fuel consumed (trip drive fuel + trip PTO governor moving fuel + trip PTO governor non-moving fuel + trip idle fuel) over the life of the engine.…";
CM_ SG_ 2633936894 TripFuelGaseous "Total fuel consumed (trip drive fuel + trip PTO governor moving fuel + trip PTO governor non-moving fuel + trip idle fuel) since the last trip reset.…";
CM_ BO_ 2633937150 "Trip Time Information 2";
CM_ SG_ 2633937150 TripAirCompressorOnTime "Total time that the air compressor is on and compressing air since the last trip reset.…";
CM_ SG_ 2633937150 TripCruiseTime "Total time accumulated while the engine is in the cruise hold state, excluding time in accelerator override, since the last trip reset.…";
CM_ SG_ 2633937150 TripEngineRunningTime "Total time accumulated while the engine speed is greater than zero since the last trip reset.  Note that time with the ignition switch on but engine speed at ze…";
CM_ SG_ 2633937150 TripIdleTime "Total time accumulated while the engine speed is greater than zero, both the PTO and remote PTO governors are inactive, and the vehicle speed is less than 2 km/…";
CM_ SG_ 2633937150 TripPTOGovernorTime "Total time accumulated while the engine is in the PTO or remote PTO governor hold state since the last trip reset.…";
CM_ BO_ 2633937406 "ECU History";
CM_ SG_ 2633937406 TotalECUDistance "Total distance accumulated over the life of the ECU.  When the ECU is replaced this value shall be reset.…";
CM_ SG_ 2633937406 TotalECURunTime "Total time accumulated over the life of the ECU, from ignition switch ON to ignition switch OFF.  When the ECU is replaced this value shall be reset.…";
CM_ BO_ 2633937662 "Fuel Information 1 (Gaseous)";
CM_ SG_ 2633937662 EngineFuelSpecificGravity "This parameter conveys the specific gravity of the gaseous fuel being used by the engine.  The specific gravity of the fuel can then be used to compute the dens…";
CM_ SG_ 2633937662 TripAverageFuelRateGaseous "Average fuel rate, equal to trip fuel divided by trip time while the engine speed is above zero, since the last trip reset.  This includes idle, engine PTO gove…";
CM_ SG_ 2633937662 TtlEngnPTOGvrnrFlUsdGss "Total fuel used while the PTO or remote PTO governors are in the hold state and engine speed is above zero, over the life of the engine.NOTE—This parameter is i…";
CM_ BO_ 2633937918 "Fuel Information 1 (Liquid)";
CM_ SG_ 2633937918 FlexibleFuelPercentage "Measured signal that indicates the percentage of alcohol in the fuel currently being used.  0% means no alcohol in fuel, 100% means alcohol as fuel and nothing …";
CM_ SG_ 2633937918 TotalEnginePTOGovernorFuelUsed "Total fuel used while the PTO or remote PTO governors are in the hold state and engine speed is above zero, over the life of the engine.NOTE—This parameter is i…";
CM_ SG_ 2633937918 TripAverageFuelRate "Average fuel rate, equal to trip fuel divided by trip time while the engine speed is above zero, since the last trip reset.  This includes idle, engine PTO gove…";
CM_ BO_ 2633938174 "Trip Time Information 1";
CM_ SG_ 2633938174 TripTimeinDeratebyEngine "Total time accumulated when the engine final fueling has been derated due to an engine protection algorithm, since the last reset.…";
CM_ SG_ 2633938174 TripTimeinGearDown "Total time accumulated when the vehicle has operated in one gear down from the top gear for a calibrated minimum time, since the last trip reset.…";
CM_ SG_ 2633938174 TripTimeinTopGear "Total time accumulated when the vehicle has operated in top gear for a calibrated minimum time, since the last trip reset.…";
CM_ SG_ 2633938174 TripTimeinVSL "Total time accumulated when the engine has operated on the vehicle speed limiter (VSL) while not in the cruise hold state, since the last trip reset.  The engin…";
CM_ BO_ 2633938430 "Trip Shutdown Information";
CM_ SG_ 2633938430 TripNumberofHotShutdowns "Total number of hot shutdowns since the last trip reset.  A hot shutdown is based on operation at high load or high engine speed or for long operating periods w…";
CM_ SG_ 2633938430 TripNumberofIdleShutdowns "Total number of times the engine has been shutdown due to idling too long (at normal idle or fast idle) since the last trip reset.…";
CM_ SG_ 2633938430 TripSuddenDecelerations "Total number of decelerations whenever the vehicle deceleration is more than XYZ km/h/sec (where XYZ is a calibratible threshold), since the last trip reset.  A…";
CM_ SG_ 2633938430 TrpNmrfIdlShtdwnOvrrds "Total number of times an operator disables idle shutdown to prevent an engine shutdown, since the last trip reset.…";
CM_ BO_ 2633938686 "Trip Vehicle Speed/Cruise Distance Information";
CM_ SG_ 2633938686 TripCruiseDistance "Total distance that the engine has operated in the cruise hold state, excluding time in accelerator override, since the last trip reset.…";
CM_ SG_ 2633938686 TripMaximumVehicleSpeed "Maximum vehicle speed achieved while the engine speed is greater than zero and the accelerator pedal position (APS) is at a value greater than 0%, since the las…";
CM_ BO_ 2633938942 "Engine Speed/Load Factor Information";
CM_ SG_ 2633938942 TotalDriveAverageLoadFactor "Average engine load factor while engine speed is greater than zero, vehicle speed is greater than or equal to 2 km/h, and both the PTO (moving/non-moving) and r…";
CM_ SG_ 2633938942 TotalEngineCruiseTime "Total time that the engine has operated in the cruise hold state, excluding time in accelerator override, over the life of the engine.…";
CM_ SG_ 2633938942 TripAverageEngineSpeed "Average speed of the engine since the last trip reset.NOTE — Excludes ignition-on time without the engine speed above zero.  Includes idle, engine PTO governor …";
CM_ SG_ 2633938942 TripDriveAverageLoadFactor "Average engine load factor while engine speed is greater than zero, vehicle speed is greater than or equal to 2 km/h, and both the PTO (moving/non-moving) and r…";
CM_ SG_ 2633938942 TripMaximumEngineSpeed "Maximum engine speed achieved since the last trip reset.…";
CM_ BO_ 2633939198 "Trip Fuel Information (Gaseous)";
CM_ SG_ 2633939198 TripCruiseFuelUsedGaseous "Total fuel consumed while the engine is in the cruise hold state since the last trip reset.  If both cruise control and VSL (vehicle speed limiter) are commandi…";
CM_ SG_ 2633939198 TripDriveFuelEconomyGaseous "Trip drive fuel economy is equal to the distance traveled by vehicle in the drive state (engine speed greater than zero, vehicle speed greater than or equal to …";
CM_ SG_ 2633939198 TripDriveFuelUsedGaseous "Total fuel consumed while the engine speed is greater than zero, vehicle speed is greater than or equal to 2 km/h, and neither the PTO or the remote PTO governo…";
CM_ SG_ 2633939198 TripVehicleIdleFuelUsedGaseous "Total fuel consumed while neither the PTO or remote PTO governors are active, the engine speed is greater than zero, and vehicle speed is less than to 2 km/h, s…";
CM_ SG_ 2633939198 TrpPTOGvrnrMvngFlUsdGss "Total fuel consumed while the PTO or remote PTO governors are in the hold state, the engine speed is greater than zero, and vehicle speed is greater than or equ…";
CM_ SG_ 2633939198 TrpPTOGvrnrNnmvngFlUsdGss "Total fuel consumed while the PTO or remote PTO governors are in the hold state, the engine speed is greater than zero, and vehicle speed is less than to 2 km/h…";
CM_ BO_ 2633939454 "Trip Fuel Information (Liquid)";
CM_ SG_ 2633939454 TripCruiseFuelUsed "Total fuel consumed while the engine is in the cruise hold state since the last trip reset.  If both cruise control and VSL (vehicle speed limiter) are commandi…";
CM_ SG_ 2633939454 TripDriveFuelEconomy "Trip drive fuel economy is equal to the distance traveled by vehicle in the drive state (engine speed greater than zero, vehicle speed greater than or equal to …";
CM_ SG_ 2633939454 TripDriveFuelUsed "Total fuel consumed while the engine speed is greater than zero, vehicle speed is greater than or equal to 2 km/h, and neither the PTO or the remote PTO is cont…";
CM_ SG_ 2633939454 TripPTOGovernorMovingFuelUsed "Total fuel consumed while either the PTO or remote PTO governors are in the hold state, the engine speed is greater than zero, and vehicle speed is greater than…";
CM_ SG_ 2633939454 TripVehicleIdleFuelUsed "Total fuel consumed while neither the PTO or remote PTO governor is in the hold state, the engine speed is greater than zero, and vehicle speed is less than 2 k…";
CM_ SG_ 2633939454 TrpPTOGvrnrNnmvngFlUsd "Total fuel consumed while either the PTO or remote PTO governors are in the hold state, the engine speed is greater than zero, and vehicle speed is less than 2 …";
CM_ BO_ 2633939710 "Trip Distance Information";
CM_ SG_ 2633939710 TripDistanceinTopGear "Total distance accumulated while the vehicle has operated in top gear for a calibrated minimum time since the last trip reset.…";
CM_ SG_ 2633939710 TripDistanceonVSL "Total distance accumulated while the engine torque mode is road speed governing since the last trip reset.…";
CM_ SG_ 2633939710 TripGearDownDistance "Total distance accumulated while the vehicle has operated in the gear which is one gear down from top gear and exceeds a calibrated minimum time (typically the …";
CM_ BO_ 2633939966 "Trip Fan Information";
CM_ SG_ 2633939966 TripFanOnTime "Total time the fan has been on (due to an automatic trigger or manual trigger) since the last trip reset.  The fan could be requested to be on by the engine sys…";
CM_ SG_ 2633939966 TripFanOnTimeDuetoaManualSwitch "Total time the fan has been on due to manual activation by the operator (i.e., excluding time on due to automatic triggers) since the last trip reset.  For the …";
CM_ SG_ 2633939966 TripFanOnTimeDuetotheACSystem "Total time the fan has been on due to the A/C system since the last trip reset.  For the time to be accumulated against the A/C system, it is necessary that it …";
CM_ SG_ 2633939966 TrpFnOnTmDtthEngnSstm "Total time the fan has been on due to engine triggers (i.e., excluding time on due to an operator manual switch or A/C system) since the last trip reset.  For t…";
CM_ BO_ 2633940222 "Compression/Service Brake Information";
CM_ SG_ 2633940222 TotalCompressionBrakeDistance "Total distance over which the compression brakes have been active for the life of the engine.…";
CM_ SG_ 2633940222 TripCompressionBrakeDistance "Total distance over which the compression brakes have been active since the last trip reset.…";
CM_ SG_ 2633940222 TripServiceBrakeApplications "Total number of times the service brakes have been activated since the last trip reset.  Brake applications of less than 0.5 s are not counted and lengthy brake…";
CM_ SG_ 2633940222 TripServiceBrakeDistance "Total distance over which the service brakes have been active since the last trip reset.…";
CM_ BO_ 2633940734 "Electronic Engine Controller 4";
CM_ SG_ 2633940734 CrnkAttmptCntnPrsntStrtAttmpt "Reports the number of cranking cycles undergone during the present start attempt.Note:  This is intended to be used in conjunction with Maximum Crank Attempts p…";
CM_ SG_ 2633940734 EngineRatedPower "Net brake power that the engine will deliver continuously, specified for a given application at a rated speed.…";
CM_ SG_ 2633940734 EngineRatedSpeed "The maximum governed rotational velocity of the engine crankshaft under full load conditions.  Note that the engine speed at point 2 (SPN 528) is equal to rated…";
CM_ SG_ 2633940734 EngineRotationDirection "Direction of engine rotation, as reported by the engine.  Direction convention as viewed by an observer standing at the rear of the engine, viewing the flywheel…";
CM_ SG_ 2633940734 EngnIntkMnfldPrssrCntrlMd "Indicates that the Boost Pressure Closed Loop Control status either open loop or closed loop.00b = Open loop 01b = Closed loop 10b = SAE reserved11b = Not avail…";
CM_ SG_ 2633940734 EngnPrlOlLwPrssrThrshld "The minimum value that the engine oil pressure (SPN 100 and SPN 7468) must exceed in order to start the engine.This parameter is intended for applications that …";
CM_ BO_ 2633941758 "Electronic Retarder Controller 2";
CM_ SG_ 2633941758 CrsCntrlRtrdrAtvSpdOffst "The additional speed above the operator selected cruise control set speed at which the retarder will activate when cruise control is active.…";
CM_ SG_ 2633941758 TransmissionOutputRetarder "Identifies the status of the transmission output retarder.00b = Off01b = On10b = Error11b = Not available…";
CM_ BO_ 2633942014 "Electronic Transmission Controller 5";
CM_ SG_ 2633942014 TransmissionLowRangeSenseSwitch "Identifies the status of the switch that represents low range.00b = Off01b = On10b = Error11b = Not available…";
CM_ SG_ 2633942014 TransmissionNeutralSwitch "Identifies the status of the switch that indicates neutral.00b = Off01b = On10b = Error11b = Not available…";
CM_ SG_ 2633942014 TrnsmssnFrwrdDrtnSwth "Identifies the status of the switch that indicates forward direction.00b = Off01b = On10b = Error11b = Not available…";
CM_ SG_ 2633942014 TrnsmssnHghRngSnsSwth "Identifies the status of the switch that represents high range.00b = Off01b = On10b = Error11b = Not available…";
CM_ SG_ 2633942014 TrnsmssnRvrsDrtnSwth "Identifies the status of the switch that indicates reverse direction.00b = Off01b = On10b = Error11b = Not available…";
CM_ SG_ 2633942014 TransmissionSplitterPosition "The current position of the splitter cylinder.00b = Off/Low01b = On/High10b = Error11b = Not Available…";
CM_ BO_ 2633942526 "Electronic Transmission Controller 4";
CM_ SG_ 2633942526 TrnsmssnSnhrnzrBrkVl "The current modulated value for the air supply to the synchronizer brake.…";
CM_ SG_ 2633942526 TrnsmssnSnhrnzrClthVl "The current modulated value for the air supply to the synchronizer clutch.…";
CM_ BO_ 2633943038 "Electronic Transmission Controller 3";
CM_ SG_ 2633943038 TransmissionClutchActuator "Identifies the status of the actuator that controls the clutch.00b = Off01b = On10b = Error11b = Not available…";
CM_ SG_ 2633943038 TransmissionDefuelActuator "Identifies the status of the actuator that controls the engine defuel mechanism.00b = Off01b = On10b = Error11b = Not available…";
CM_ SG_ 2633943038 TransmissionRangeHighActuator "Identifies the status of the range high actuator in the auxiliary unit.00b = Off01b = On10b = Error11b = Not available…";
CM_ SG_ 2633943038 TransmissionRangeLowActuator "Identifies the status of the range low actuator in the auxiliary unit.00b = Off01b = On10b = Error11b = Not available…";
CM_ SG_ 2633943038 TrnsmssnInrtBrkAttr "Identifies the status of the actuator that controls the inertia brake.00b = Off01b = On10b = Error11b = Not available…";
CM_ SG_ 2633943038 TrnsmssnShftFngrCntrRlIndtr "Identifies the status of the shift finger in the center rail position.00b = Off01b = On10b = Error11b = Not available…";
CM_ SG_ 2633943038 TrnsmssnShftFngrEnggmntIndtr "Identifies the status of the shift finger in the engagement position.00b = Off01b = On10b = Error11b = Not available…";
CM_ SG_ 2633943038 TrnsmssnShftFngrGrAttr1 "Identifies the status of the actuator that moves the shift finger identified as gear actuator #1.00b = Off01b = On10b = Error11b = Not available…";
CM_ SG_ 2633943038 TrnsmssnShftFngrGrAttr2 "Identifies the status of the actuator that moves the shift finger identified as gear actuator #2.00b = Off01b = On10b = Error11b = Not available…";
CM_ SG_ 2633943038 TrnsmssnShftFngrGrPstn "The current position of the shift finger in the gear direction.…";
CM_ SG_ 2633943038 TrnsmssnShftFngrNtrlIndtr "Indicates the status of the shift finger in the neutral position.00b = Off01b = On10b = Error11b = Not available…";
CM_ SG_ 2633943038 TrnsmssnShftFngrRlAttr1 "Identifies the status of the actuator that moves the shift finger identified as rail actuator #1.00b = Off01b = On10b = Error11b = Not available…";
CM_ SG_ 2633943038 TrnsmssnShftFngrRlAttr2 "Identifies the status of the actuator that moves the shift finger identified as rail actuator #2.00b = Off01b = On10b = Error11b = Not available…";
CM_ SG_ 2633943038 TrnsmssnShftFngrRlPstn "The current position of the shift finger in the rail direction.…";
CM_ SG_ 2633943038 TrnsmssnSplttrDrtAttr "Identifies the status of the splitter direct actuator in the auxiliary unit.00b = Off01b = On10b = Error11b = Not available…";
CM_ SG_ 2633943038 TrnsmssnSplttrIndrtAttr "Identifies the status of the splitter indirect actuator in the auxiliary unit.00b = Off01b = On10b = Error11b = Not available…";
CM_ SG_ 2633943038 TrnsmssnTrqCnvrtrLkpClthAttr "Identifies the status of the actuator that controls the torque converter lockup clutch.00b = Off01b = On10b = Error11b = Not available…";
CM_ BO_ 2565865726 "Electronic Retarder Controller 1";
CM_ SG_ 2565865726 ActualRetarderPercentTorque "Actual braking torque of the retarder as a percent of retarder configuration reference torque SPN 556.Note:  Refer to section 5.2.1 in SAE J1939-71.…";
CM_ SG_ 2565865726 AtlMxmmAvllRtrdrPrntTrq "This is the maximum amount of torque that the retarder can immediately deliver.   It is the same as the maximum torque shown in the Retarder’s Configuration mes…";
CM_ SG_ 2565865726 DrvrsDmndRtrdrPrntTrq "The Drivers demand retarder – percent torque is the maximum torque selected by the driver when one or more modes  are selected by the driver, such as hand lever…";
CM_ SG_ 2565865726 EngineCoolantLoadIncrease "Status of an event, external to the engine, that may increase the nominal temperature of the engine coolant liquid.00b = No coolant load increase01b = Coolant l…";
CM_ SG_ 2565865726 IntendedRetarderPercentTorque "Braking torque of retarder that the retarder is currently trying to achieve.  This value takes into account all static limitations, but not the limitations due …";
CM_ SG_ 2565865726 RetarderEnableBrakeAssistSwitch "Switch signal which indicates whether the operator wishes the retarder to be enabled for vehicle braking assist. The retarder does not check this switch, nor do…";
CM_ SG_ 2565865726 RetarderEnableShiftAssistSwitch "Switch signal which indicates whether the operator wishes the retarder to be enabled for transmission shift assist.  The retarder does not check this switch, no…";
CM_ SG_ 2565865726 RetarderRequestingBrakeLight "Indicates that whether the retarder is requesting that the brake lights are illuminated.00b = Retarder is not requesting that the brake lights are illuminated01…";
CM_ SG_ 2565865726 RetarderRoadSpeedExceededStatus "Retarder Road Speed Exceeded Status:00b = Road speed is below threshold 01b = Road speed is above threshold and retarder is allowed to be activated10b = Reserve…";
CM_ SG_ 2565865726 RetarderRoadSpeedLimitSwitch "Retarder road speed limit switch states:00b = Road speed limiting by retarder is disabled01b = Road speed limiting by retarder is enabled. When the speed limit …";
CM_ SG_ 2565865726 RetarderSelectionnonengine "The “Retarder Selection, non-engine” is the position of the driver’s selector for retarders that are not part of the engine system, expressed as percent and det…";
CM_ SG_ 2565865726 RetarderTorqueMode "State signal which indicates which retarder torque mode is currently generating, limiting, or controlling the torque.  Note that the modes are not in prioritize…";
CM_ SG_ 2565865726 SrAddrssfCntrllngDvfrRtrdrCntrl "The source address of the SAE J1939 device currently controlling the retarder.  It is used to expand the torque mode parameter (see SPN 899) in cases where cont…";
CM_ BO_ 2499608830 "Engine Fluid Level/Pressure 10";
CM_ SG_ 2499608830 EngineCoolantPressure2 "Gage pressure of liquid found in the engine coolant system - second instance.See SPN 7313 for alternate range and resolution.…";
CM_ SG_ 2499608830 EngnExhstGsRrltn2DffrntlPrssr "Differential Pressure across the Exhaust Gas Recirculation 2 (EGR2) system.…";
CM_ SG_ 2499608830 EngnExhstGsRrltn2IntkAsltPrssr "EGR intake absolute pressure measured before the EGR 2 valve.…";
CM_ SG_ 2499608830 EngnExhstGsRrltn2IntkPrssr "EGR2 intake gauge pressure is measured after EGR2 cooler and before EGR2 valve…";
CM_ SG_ 2499608830 EngnExhstGsRrltn2OtltAsltPrssr "Absolute Pressure immediately after the EGR2 valve…";
CM_ BO_ 2365456638 "Generator Phase B Basic AC Quantities";
CM_ SG_ 2365456638 GeneratorPhaseBACFrequency "AC frequency measured at the generator phase B output.…";
CM_ SG_ 2365456638 GeneratorPhaseBACRMSCurrent "RMS current measured at the generator phase B output.…";
CM_ SG_ 2365456638 GnrtrPhsBCLnLnACRMSVltg "Line to Line RMS voltage measured at the generator phase BC output.…";
CM_ SG_ 2365456638 GnrtrPhsBLnNtrlACRMSVltg "Line to Neutral RMS voltage measured at the generator phase B output.…";
CM_ BO_ 2351365886 "Motor/Generator 1 Inverter Control";
CM_ SG_ 2351365886 MtrGnrtr1InvrtrCntrlCRC "The CRC is defined as follows:  • Length: 8 bits  • Polynomial: x^8+x^5+x^3+x^2+x+1  • Initial Value: FFh  • Input Data Reflection: Not reflected  • Result Data…";
CM_ SG_ 2351365886 MtrGnrtr1InvrtrCntrlCntr "The message counter is used to detect situations where the transmitting ECU malfunction repeats the same frame all the time. The receiver of the information may…";
CM_ SG_ 2351365886 MtGt1IvtCtLtsRqstOvdMd "This parameter provides a way to temporarily override limits that are being received by the inverter in other messages.  It allows a specific type of limit to b…";
CM_ SG_ 2351365886 MtrGnrtr1InvrtrCntrlStpntMdRqst "Requests the modes for this instance of the inverter.  See SPN 10167 [Control Setpoint Mode] for the feedback to this request.Passive modes:  Modes where the in…";
CM_ SG_ 2351365886 MtrGnrtr1InvrtrCntrlStpntRqst "Requests the set point for this inverter.  The type of set point requested by this parameter depends on the value of SPN 10162 [Control Setpoint Mode Request] a…";
CM_ BO_ 2351431422 "Motor/Generator 2 Inverter Control";
CM_ SG_ 2351431422 MtrGnrtr2InvrtrCntrlCRC "The CRC is defined as follows: • Length: 8 bits • Polynomial: x^8+x^5+x^3+x^2+x+1 • Initial Value: FFh • Input Data Reflection: Not reflected • Result Data Refl…";
CM_ SG_ 2351431422 MtrGnrtr2InvrtrCntrlCntr "The message counter is used to detect situations where the transmitting ECU malfunction repeats the same frame all the time. The receiver of the information may…";
CM_ SG_ 2351431422 MtGt2IvtCtLtsRqstOvdMd "This parameter provides a way to temporarily override limits that are being received by the inverter in other messages.  It allows a specific type of limit to b…";
CM_ SG_ 2351431422 MtrGnrtr2InvrtrCntrlStpntMdRqst "Requests the modes for this instance of the inverter.  See SPN 10233 [Control Setpoint Mode] for the feedback to this request.Passive modes:  Modes where the in…";
CM_ SG_ 2351431422 MtrGnrtr2InvrtrCntrlStpntRqst "Requests the set point for this inverter.  The type of set point requested by this parameter depends on the value of SPN 10228 [Control Setpoint Mode Request] a…";
CM_ BO_ 2556165886 "Motor/Generator 2 Inverter Limits Request Power";
CM_ SG_ 2556165886 MtrGnrtr2InvrtrLmtsRqstPwrCRC "The CRC is defined as follows: • Length: 8 bits • Polynomial: x^8+x^5+x^3+x^2+x+1 • Initial Value: FFh • Input Data Reflection: Not reflected • Result Data Refl…";
CM_ SG_ 2556165886 MtrGnrtr2InvrtrLmtsRqstPwrCntr "The message counter is used to detect situations where the transmitting ECU malfunction repeats the same frame all the time. The receiver of the information may…";
CM_ BO_ 2556231422 "Motor/Generator 2 Inverter Limits Request Mechanical";
CM_ SG_ 2556231422 MtrGnrtr2InvrtrLmtsRqstMhnlCRC "The CRC is defined as follows: • Length: 8 bits • Polynomial: x^8+x^5+x^3+x^2+x+1 • Initial Value: FFh • Input Data Reflection: Not reflected • Result Data Refl…";
CM_ SG_ 2556231422 MtrGnrtr2InvrtrLmtsRqstMhnlCntr "The message counter is used to detect situations where the transmitting ECU malfunction repeats the same frame all the time. The receiver of the information may…";
CM_ BO_ 2556296958 "Motor/Generator 2 Inverter Limits Request DC Side";
CM_ SG_ 2556296958 MtrGnrtr2InvrtrLmtsRqstDCSdCRC "The CRC is defined as follows: • Length: 8 bits • Polynomial: x^8+x^5+x^3+x^2+x+1 • Initial Value: FFh • Input Data Reflection: Not reflected • Result Data Refl…";
CM_ SG_ 2556296958 MtrGnrtr2InvrtrLmtsRqstDCSdCntr "The message counter is used to detect situations where the transmitting ECU malfunction repeats the same frame all the time. The receiver of the information may…";
CM_ BO_ 2556362494 "Motor/Generator 1 Inverter Limits Request DC Side";
CM_ SG_ 2556362494 MtrGnrtr1InvrtrLmtsRqstDCSdCRC "The CRC is defined as follows: • Length: 8 bits • Polynomial: x^8+x^5+x^3+x^2+x+1 • Initial Value: FFh • Input Data Reflection: Not reflected • Result Data Refl…";
CM_ SG_ 2556362494 MtrGnrtr1InvrtrLmtsRqstDCSdCntr "The message counter is used to detect situations where the transmitting ECU malfunction repeats the same frame all the time. The receiver of the information may…";
CM_ BO_ 2556428030 "Motor/Generator 1 Inverter Limits Request Mechanical";
CM_ SG_ 2556428030 MtrGnrtr1InvrtrLmtsRqstMhnlCRC "The CRC is defined as follows: • Length: 8 bits • Polynomial: x^8+x^5+x^3+x^2+x+1 • Initial Value: FFh • Input Data Reflection: Not reflected • Result Data Refl…";
CM_ SG_ 2556428030 MtrGnrtr1InvrtrLmtsRqstMhnlCntr "The message counter is used to detect situations where the transmitting ECU malfunction repeats the same frame all the time. The receiver of the information may…";
BA_DEF_ SG_  "SPN" INT 0 524287;
BA_DEF_ BO_  "VFrameFormat" ENUM  "StandardCAN","ExtendedCAN","reserved","J1939PG";
BA_DEF_DEF_  "SPN" 0;
BA_DEF_DEF_  "VFrameFormat" "J1939PG";
BA_ "SPN" SG_ 2633753598 AltrntrArClrArIntkTmprtr 8449;
BA_ "SPN" SG_ 2633753598 AltrntrArClrArOtltTmprtr 8450;
BA_ "SPN" SG_ 2633753598 EngnAltrntrWndng10Tmprtr 8446;
BA_ "SPN" SG_ 2633753598 EngnAltrntrWndng11Tmprtr 8447;
BA_ "SPN" SG_ 2633753598 EngnAltrntrWndng12Tmprtr 8448;
BA_ "SPN" SG_ 2633753598 EngnAltrntrWndng7Tmprtr 8443;
BA_ "SPN" SG_ 2633753598 EngnAltrntrWndng8Tmprtr 8444;
BA_ "SPN" SG_ 2633753598 EngnAltrntrWndng9Tmprtr 8445;
BA_ "SPN" SG_ 2633754622 Aftrtrtmnt1SCRIntkHghTmprtrTm 8327;
BA_ "SPN" SG_ 2633754622 SCROptIdtEOvdTtAtvtT 9179;
BA_ "SPN" SG_ 2633754878 AftrtrtmntTtlDslExhstFldUsd 8326;
BA_ "SPN" SG_ 2633755390 DefaultGatewayOctet1 8278;
BA_ "SPN" SG_ 2633755390 DefaultGatewayOctet2 8279;
BA_ "SPN" SG_ 2633755390 DefaultGatewayOctet3 8280;
BA_ "SPN" SG_ 2633755390 DefaultGatewayOctet4 8281;
BA_ "SPN" SG_ 2633755390 DHCPStatus 8268;
BA_ "SPN" SG_ 2633755390 EthernetLinkStatus 8269;
BA_ "SPN" SG_ 2633755390 IPv4AddressOctet1 8270;
BA_ "SPN" SG_ 2633755390 IPv4AddressOctet2 8271;
BA_ "SPN" SG_ 2633755390 IPv4AddressOctet3 8272;
BA_ "SPN" SG_ 2633755390 IPv4AddressOctet4 8273;
BA_ "SPN" SG_ 2633755390 MACAddressOctet1 8282;
BA_ "SPN" SG_ 2633755390 MACAddressOctet2 8283;
BA_ "SPN" SG_ 2633755390 MACAddressOctet3 8284;
BA_ "SPN" SG_ 2633755390 MACAddressOctet4 8285;
BA_ "SPN" SG_ 2633755390 MACAddressOctet5 8286;
BA_ "SPN" SG_ 2633755390 MACAddressOctet6 8287;
BA_ "SPN" SG_ 2633755390 SubnetMaskOctet1 8274;
BA_ "SPN" SG_ 2633755390 SubnetMaskOctet2 8275;
BA_ "SPN" SG_ 2633755390 SubnetMaskOctet3 8276;
BA_ "SPN" SG_ 2633755390 SubnetMaskOctet4 8277;
BA_ "SPN" SG_ 2633764094 CanisterPurgeValveCommand 7834;
BA_ "SPN" SG_ 2633764094 CanisterVentValve 7833;
BA_ "SPN" SG_ 2633764094 GasolineFuelTankPressure 7835;
BA_ "SPN" SG_ 2633764350 FirePumpEngagementCycles 7826;
BA_ "SPN" SG_ 2633764350 FirePumpOperationTime 7825;
BA_ "SPN" SG_ 2633769726 EngnExhstFlwRtExtnddRng 7852;
BA_ "SPN" SG_ 2633769726 TotalEngineEnergy 7608;
BA_ "SPN" SG_ 2633773054 FireSuppressionWaterTankLevel 7347;
BA_ "SPN" SG_ 2633773054 FrSpprssnClssAFmTnkLvl 7348;
BA_ "SPN" SG_ 2633773054 FrSpprssnClssBFmTnkLvl 7349;
BA_ "SPN" SG_ 2633773054 FrSpprssnCmprssdArFmSstmArPrssr 7350;
BA_ "SPN" SG_ 2633773310 SCROprtrIndmntOvrrdMd 7342;
BA_ "SPN" SG_ 2633773310 SCROprtrIndmntOvrrdRnwlRqrd 7343;
BA_ "SPN" SG_ 2633773310 SCROptIdtEOvdTtRstOs 7341;
BA_ "SPN" SG_ 2633773310 SCROptIdtOvdTRExtddR 7344;
BA_ "SPN" SG_ 2633782014 BinInstance 6845;
BA_ "SPN" SG_ 2633782014 BinLiftCount 6840;
BA_ "SPN" SG_ 2633782014 BinWeighingErrorStatus 6842;
BA_ "SPN" SG_ 2633782014 NetBinWeight 6841;
BA_ "SPN" SG_ 2633785086 HVES1CnttrOpnUndrLdCnt 8122;
BA_ "SPN" SG_ 2633785086 HVES1StateofHealth 8121;
BA_ "SPN" SG_ 2633785086 HVES1TotalAccumulatedCharge 8212;
BA_ "SPN" SG_ 2633785086 HVES1TotalEnergyThroughput 8211;
BA_ "SPN" SG_ 2633801982 EngnTtlHrsfDslFlOprtn 6320;
BA_ "SPN" SG_ 2633801982 EngnTtlHrsfGssFlOprtn 6319;
BA_ "SPN" SG_ 2633802238 EngineSparkPlug17MisfireRate 6286;
BA_ "SPN" SG_ 2633802238 EngineSparkPlug18MisfireRate 6287;
BA_ "SPN" SG_ 2633802238 EngineSparkPlug19MisfireRate 6288;
BA_ "SPN" SG_ 2633802238 EngineSparkPlug20MisfireRate 6289;
BA_ "SPN" SG_ 2633802238 EngineSparkPlug21MisfireRate 6290;
BA_ "SPN" SG_ 2633802238 EngineSparkPlug22MisfireRate 6291;
BA_ "SPN" SG_ 2633802238 EngineSparkPlug23MisfireRate 6292;
BA_ "SPN" SG_ 2633802238 EngineSparkPlug24MisfireRate 6293;
BA_ "SPN" SG_ 2633802494 EngineSparkPlug10MisfireRate 6279;
BA_ "SPN" SG_ 2633802494 EngineSparkPlug11MisfireRate 6280;
BA_ "SPN" SG_ 2633802494 EngineSparkPlug12MisfireRate 6281;
BA_ "SPN" SG_ 2633802494 EngineSparkPlug13MisfireRate 6282;
BA_ "SPN" SG_ 2633802494 EngineSparkPlug14MisfireRate 6283;
BA_ "SPN" SG_ 2633802494 EngineSparkPlug15MisfireRate 6284;
BA_ "SPN" SG_ 2633802494 EngineSparkPlug16MisfireRate 6285;
BA_ "SPN" SG_ 2633802494 EngineSparkPlug9MisfireRate 6278;
BA_ "SPN" SG_ 2633802750 EngineSparkPlug1MisfireRate 6270;
BA_ "SPN" SG_ 2633802750 EngineSparkPlug2MisfireRate 6271;
BA_ "SPN" SG_ 2633802750 EngineSparkPlug3MisfireRate 6272;
BA_ "SPN" SG_ 2633802750 EngineSparkPlug4MisfireRate 6273;
BA_ "SPN" SG_ 2633802750 EngineSparkPlug5MisfireRate 6274;
BA_ "SPN" SG_ 2633802750 EngineSparkPlug6MisfireRate 6275;
BA_ "SPN" SG_ 2633802750 EngineSparkPlug7MisfireRate 6276;
BA_ "SPN" SG_ 2633802750 EngineSparkPlug8MisfireRate 6277;
BA_ "SPN" SG_ 2633803006 EngineSparkPlug21MaximumVoltage 6266;
BA_ "SPN" SG_ 2633803006 EngineSparkPlug22MaximumVoltage 6267;
BA_ "SPN" SG_ 2633803006 EngineSparkPlug23MaximumVoltage 6268;
BA_ "SPN" SG_ 2633803006 EngineSparkPlug24MaximumVoltage 6269;
BA_ "SPN" SG_ 2633803262 EngineSparkPlug17MaximumVoltage 6262;
BA_ "SPN" SG_ 2633803262 EngineSparkPlug18MaximumVoltage 6263;
BA_ "SPN" SG_ 2633803262 EngineSparkPlug19MaximumVoltage 6264;
BA_ "SPN" SG_ 2633803262 EngineSparkPlug20MaximumVoltage 6265;
BA_ "SPN" SG_ 2633803518 EngineSparkPlug13MaximumVoltage 6258;
BA_ "SPN" SG_ 2633803518 EngineSparkPlug14MaximumVoltage 6259;
BA_ "SPN" SG_ 2633803518 EngineSparkPlug15MaximumVoltage 6260;
BA_ "SPN" SG_ 2633803518 EngineSparkPlug16MaximumVoltage 6261;
BA_ "SPN" SG_ 2633803774 EngineSparkPlug10MaximumVoltage 6255;
BA_ "SPN" SG_ 2633803774 EngineSparkPlug11MaximumVoltage 6256;
BA_ "SPN" SG_ 2633803774 EngineSparkPlug12MaximumVoltage 6257;
BA_ "SPN" SG_ 2633803774 EngineSparkPlug9MaximumVoltage 6254;
BA_ "SPN" SG_ 2633804030 EngineSparkPlug5MaximumVoltage 6250;
BA_ "SPN" SG_ 2633804030 EngineSparkPlug6MaximumVoltage 6251;
BA_ "SPN" SG_ 2633804030 EngineSparkPlug7MaximumVoltage 6252;
BA_ "SPN" SG_ 2633804030 EngineSparkPlug8MaximumVoltage 6253;
BA_ "SPN" SG_ 2633804286 EngineSparkPlug1MaximumVoltage 6246;
BA_ "SPN" SG_ 2633804286 EngineSparkPlug2MaximumVoltage 6247;
BA_ "SPN" SG_ 2633804286 EngineSparkPlug3MaximumVoltage 6248;
BA_ "SPN" SG_ 2633804286 EngineSparkPlug4MaximumVoltage 6249;
BA_ "SPN" SG_ 2633804542 EngineSparkPlug21MinimumVoltage 6242;
BA_ "SPN" SG_ 2633804542 EngineSparkPlug22MinimumVoltage 6243;
BA_ "SPN" SG_ 2633804542 EngineSparkPlug23MinimumVoltage 6244;
BA_ "SPN" SG_ 2633804542 EngineSparkPlug24MinimumVoltage 6245;
BA_ "SPN" SG_ 2633804798 EngineSparkPlug17MinimumVoltage 6238;
BA_ "SPN" SG_ 2633804798 EngineSparkPlug18MinimumVoltage 6239;
BA_ "SPN" SG_ 2633804798 EngineSparkPlug19MinimumVoltage 6240;
BA_ "SPN" SG_ 2633804798 EngineSparkPlug20MinimumVoltage 6241;
BA_ "SPN" SG_ 2633805054 EngineSparkPlug13MinimumVoltage 6234;
BA_ "SPN" SG_ 2633805054 EngineSparkPlug14MinimumVoltage 6235;
BA_ "SPN" SG_ 2633805054 EngineSparkPlug15MinimumVoltage 6236;
BA_ "SPN" SG_ 2633805054 EngineSparkPlug16MinimumVoltage 6237;
BA_ "SPN" SG_ 2633805310 EngineSparkPlug10MinimumVoltage 6231;
BA_ "SPN" SG_ 2633805310 EngineSparkPlug11MinimumVoltage 6232;
BA_ "SPN" SG_ 2633805310 EngineSparkPlug12MinimumVoltage 6233;
BA_ "SPN" SG_ 2633805310 EngineSparkPlug9MinimumVoltage 6230;
BA_ "SPN" SG_ 2633805566 EngineSparkPlug5MinimumVoltage 6226;
BA_ "SPN" SG_ 2633805566 EngineSparkPlug6MinimumVoltage 6227;
BA_ "SPN" SG_ 2633805566 EngineSparkPlug7MinimumVoltage 6228;
BA_ "SPN" SG_ 2633805566 EngineSparkPlug8MinimumVoltage 6229;
BA_ "SPN" SG_ 2633805822 EngineSparkPlug1MinimumVoltage 6222;
BA_ "SPN" SG_ 2633805822 EngineSparkPlug2MinimumVoltage 6223;
BA_ "SPN" SG_ 2633805822 EngineSparkPlug3MinimumVoltage 6224;
BA_ "SPN" SG_ 2633805822 EngineSparkPlug4MinimumVoltage 6225;
BA_ "SPN" SG_ 2633806078 EngnIgntnCntrlMdl1TmRmnng 6220;
BA_ "SPN" SG_ 2633806078 EngnIgntnCntrlMdl2TmRmnng 6221;
BA_ "SPN" SG_ 2633825022 EngnExhstGsRrltn2Vlv1Cntrl 5264;
BA_ "SPN" SG_ 2633825022 EngnExhstGsRrltn2Vlv1PstnErrr 5831;
BA_ "SPN" SG_ 2633825022 EngnExhstGsRrltn2Vlv2Cntrl 5265;
BA_ "SPN" SG_ 2633825022 EngnExhstGsRrltn2Vlv2PstnErrr 5832;
BA_ "SPN" SG_ 2633825534 EExstMdB1FwBVvAttCt 5276;
BA_ "SPN" SG_ 2633825534 EExstMdB2FwBVvAttCt 5278;
BA_ "SPN" SG_ 2633826046 EExstGsRt2CBpssAttPst 5261;
BA_ "SPN" SG_ 2633826046 EExstGsRt2CItGsAstPss 5259;
BA_ "SPN" SG_ 2633826046 EngnExhstGsRrltn2ClrEffn 5260;
BA_ "SPN" SG_ 2633826046 EngnExhstGsRrltn2ClrIntkPrssr 9380;
BA_ "SPN" SG_ 2633826046 EngnExhstGsRrltn2ClrIntkTmprtr 5258;
BA_ "SPN" SG_ 2633828606 EngineOilDensity 5056;
BA_ "SPN" SG_ 2633828606 EngineOilTemperature3 5925;
BA_ "SPN" SG_ 2633828606 EngineOilViscosity 5055;
BA_ "SPN" SG_ 2633828606 EngnOlRltvDltrtHghRsltn 5468;
BA_ "SPN" SG_ 2633832702 FrontalCollisionSensor1Type 4918;
BA_ "SPN" SG_ 2633832702 FrontalCollisionSensor2Type 4919;
BA_ "SPN" SG_ 2633832702 FrontalCollisionSensor3Type 4920;
BA_ "SPN" SG_ 2633832702 FrontalCollisionSensor4Type 4921;
BA_ "SPN" SG_ 2633832702 RearCollisionSensor1Type 4930;
BA_ "SPN" SG_ 2633832702 RearCollisionSensor2Type 4931;
BA_ "SPN" SG_ 2633832702 RearCollisionSensor3Type 4932;
BA_ "SPN" SG_ 2633832702 RearCollisionSensor4Type 4933;
BA_ "SPN" SG_ 2633832702 SdCllsnSnsrFrntLftTp 4922;
BA_ "SPN" SG_ 2633832702 SdCllsnSnsrFrntRghtTp 4926;
BA_ "SPN" SG_ 2633832702 SdCllsnSnsrMdFrntLftTp 4923;
BA_ "SPN" SG_ 2633832702 SdCllsnSnsrMdFrntRghtTp 4927;
BA_ "SPN" SG_ 2633832702 SdCllsnSnsrMdRrLftTp 4924;
BA_ "SPN" SG_ 2633832702 SdCllsnSnsrMdRrRghtTp 4928;
BA_ "SPN" SG_ 2633832702 SdCllsnSnsrRrRghtTp 4929;
BA_ "SPN" SG_ 2633832702 SideCollisionSensorRearLeftType 4925;
BA_ "SPN" SG_ 2633832958 DrvrArgIgntrLp1stStgRsstn 4818;
BA_ "SPN" SG_ 2633832958 DrvrArgIgntrLp2ndStgRsstn 4820;
BA_ "SPN" SG_ 2633832958 DrvrBltTnsnrIgntrLpRsstn 4822;
BA_ "SPN" SG_ 2633832958 PssngrArgIgntrLp1stStgRsstn 4819;
BA_ "SPN" SG_ 2633832958 PssngrArgIgntrLp2ndStgRsstn 4821;
BA_ "SPN" SG_ 2633832958 PssngrBltTnsnrIgntrLpRsstn 4823;
BA_ "SPN" SG_ 2633832958 SdBgIgntrLp1LftRsstn 4824;
BA_ "SPN" SG_ 2633832958 SdBgIgntrLp1RghtRsstn 4826;
BA_ "SPN" SG_ 2633832958 SdBgIgntrLp2LftRsstn 4825;
BA_ "SPN" SG_ 2633832958 SdBgIgntrLp2RghtRsstn 4827;
BA_ "SPN" SG_ 2633832958 SpecialIgnitorLoop10Resistance 4837;
BA_ "SPN" SG_ 2633832958 SpecialIgnitorLoop11Resistance 4838;
BA_ "SPN" SG_ 2633832958 SpecialIgnitorLoop12Resistance 4839;
BA_ "SPN" SG_ 2633832958 SpecialIgnitorLoop13Resistance 4840;
BA_ "SPN" SG_ 2633832958 SpecialIgnitorLoop14Resistance 4841;
BA_ "SPN" SG_ 2633832958 SpecialIgnitorLoop15Resistance 4842;
BA_ "SPN" SG_ 2633832958 SpecialIgnitorLoop16Resistance 4843;
BA_ "SPN" SG_ 2633832958 SpecialIgnitorLoop17Resistance 4844;
BA_ "SPN" SG_ 2633832958 SpecialIgnitorLoop18Resistance 4845;
BA_ "SPN" SG_ 2633832958 SpecialIgnitorLoop19Resistance 4846;
BA_ "SPN" SG_ 2633832958 SpecialIgnitorLoop1Resistance 4828;
BA_ "SPN" SG_ 2633832958 SpecialIgnitorLoop20Resistance 4847;
BA_ "SPN" SG_ 2633832958 SpecialIgnitorLoop21Resistance 4848;
BA_ "SPN" SG_ 2633832958 SpecialIgnitorLoop22Resistance 4849;
BA_ "SPN" SG_ 2633832958 SpecialIgnitorLoop23Resistance 4850;
BA_ "SPN" SG_ 2633832958 SpecialIgnitorLoop24Resistance 4851;
BA_ "SPN" SG_ 2633832958 SpecialIgnitorLoop25Resistance 4852;
BA_ "SPN" SG_ 2633832958 SpecialIgnitorLoop26Resistance 4853;
BA_ "SPN" SG_ 2633832958 SpecialIgnitorLoop27Resistance 4854;
BA_ "SPN" SG_ 2633832958 SpecialIgnitorLoop28Resistance 4855;
BA_ "SPN" SG_ 2633832958 SpecialIgnitorLoop29Resistance 4856;
BA_ "SPN" SG_ 2633832958 SpecialIgnitorLoop2Resistance 4829;
BA_ "SPN" SG_ 2633832958 SpecialIgnitorLoop30Resistance 4857;
BA_ "SPN" SG_ 2633832958 SpecialIgnitorLoop31Resistance 4858;
BA_ "SPN" SG_ 2633832958 SpecialIgnitorLoop32Resistance 4859;
BA_ "SPN" SG_ 2633832958 SpecialIgnitorLoop33Resistance 4860;
BA_ "SPN" SG_ 2633832958 SpecialIgnitorLoop34Resistance 4861;
BA_ "SPN" SG_ 2633832958 SpecialIgnitorLoop35Resistance 4862;
BA_ "SPN" SG_ 2633832958 SpecialIgnitorLoop36Resistance 4863;
BA_ "SPN" SG_ 2633832958 SpecialIgnitorLoop37Resistance 4864;
BA_ "SPN" SG_ 2633832958 SpecialIgnitorLoop38Resistance 4865;
BA_ "SPN" SG_ 2633832958 SpecialIgnitorLoop39Resistance 4866;
BA_ "SPN" SG_ 2633832958 SpecialIgnitorLoop3Resistance 4830;
BA_ "SPN" SG_ 2633832958 SpecialIgnitorLoop40Resistance 4867;
BA_ "SPN" SG_ 2633832958 SpecialIgnitorLoop41Resistance 4868;
BA_ "SPN" SG_ 2633832958 SpecialIgnitorLoop42Resistance 4869;
BA_ "SPN" SG_ 2633832958 SpecialIgnitorLoop43Resistance 4870;
BA_ "SPN" SG_ 2633832958 SpecialIgnitorLoop44Resistance 4871;
BA_ "SPN" SG_ 2633832958 SpecialIgnitorLoop45Resistance 4872;
BA_ "SPN" SG_ 2633832958 SpecialIgnitorLoop46Resistance 4873;
BA_ "SPN" SG_ 2633832958 SpecialIgnitorLoop47Resistance 4874;
BA_ "SPN" SG_ 2633832958 SpecialIgnitorLoop48Resistance 4875;
BA_ "SPN" SG_ 2633832958 SpecialIgnitorLoop49Resistance 4876;
BA_ "SPN" SG_ 2633832958 SpecialIgnitorLoop4Resistance 4831;
BA_ "SPN" SG_ 2633832958 SpecialIgnitorLoop50Resistance 4877;
BA_ "SPN" SG_ 2633832958 SpecialIgnitorLoop51Resistance 4878;
BA_ "SPN" SG_ 2633832958 SpecialIgnitorLoop52Resistance 4879;
BA_ "SPN" SG_ 2633832958 SpecialIgnitorLoop53Resistance 4880;
BA_ "SPN" SG_ 2633832958 SpecialIgnitorLoop54Resistance 4881;
BA_ "SPN" SG_ 2633832958 SpecialIgnitorLoop55Resistance 4882;
BA_ "SPN" SG_ 2633832958 SpecialIgnitorLoop56Resistance 4883;
BA_ "SPN" SG_ 2633832958 SpecialIgnitorLoop57Resistance 4884;
BA_ "SPN" SG_ 2633832958 SpecialIgnitorLoop58Resistance 4885;
BA_ "SPN" SG_ 2633832958 SpecialIgnitorLoop59Resistance 4886;
BA_ "SPN" SG_ 2633832958 SpecialIgnitorLoop5Resistance 4832;
BA_ "SPN" SG_ 2633832958 SpecialIgnitorLoop60Resistance 4887;
BA_ "SPN" SG_ 2633832958 SpecialIgnitorLoop61Resistance 4888;
BA_ "SPN" SG_ 2633832958 SpecialIgnitorLoop62Resistance 4889;
BA_ "SPN" SG_ 2633832958 SpecialIgnitorLoop63Resistance 4890;
BA_ "SPN" SG_ 2633832958 SpecialIgnitorLoop64Resistance 4891;
BA_ "SPN" SG_ 2633832958 SpecialIgnitorLoop65Resistance 4892;
BA_ "SPN" SG_ 2633832958 SpecialIgnitorLoop66Resistance 4893;
BA_ "SPN" SG_ 2633832958 SpecialIgnitorLoop67Resistance 4894;
BA_ "SPN" SG_ 2633832958 SpecialIgnitorLoop68Resistance 4895;
BA_ "SPN" SG_ 2633832958 SpecialIgnitorLoop69Resistance 4896;
BA_ "SPN" SG_ 2633832958 SpecialIgnitorLoop6Resistance 4833;
BA_ "SPN" SG_ 2633832958 SpecialIgnitorLoop70Resistance 4897;
BA_ "SPN" SG_ 2633832958 SpecialIgnitorLoop71Resistance 4898;
BA_ "SPN" SG_ 2633832958 SpecialIgnitorLoop72Resistance 4899;
BA_ "SPN" SG_ 2633832958 SpecialIgnitorLoop73Resistance 4900;
BA_ "SPN" SG_ 2633832958 SpecialIgnitorLoop74Resistance 4901;
BA_ "SPN" SG_ 2633832958 SpecialIgnitorLoop75Resistance 4902;
BA_ "SPN" SG_ 2633832958 SpecialIgnitorLoop76Resistance 4903;
BA_ "SPN" SG_ 2633832958 SpecialIgnitorLoop77Resistance 4904;
BA_ "SPN" SG_ 2633832958 SpecialIgnitorLoop78Resistance 4905;
BA_ "SPN" SG_ 2633832958 SpecialIgnitorLoop79Resistance 4906;
BA_ "SPN" SG_ 2633832958 SpecialIgnitorLoop7Resistance 4834;
BA_ "SPN" SG_ 2633832958 SpecialIgnitorLoop80Resistance 4907;
BA_ "SPN" SG_ 2633832958 SpecialIgnitorLoop81Resistance 4908;
BA_ "SPN" SG_ 2633832958 SpecialIgnitorLoop82Resistance 4909;
BA_ "SPN" SG_ 2633832958 SpecialIgnitorLoop83Resistance 4910;
BA_ "SPN" SG_ 2633832958 SpecialIgnitorLoop84Resistance 4911;
BA_ "SPN" SG_ 2633832958 SpecialIgnitorLoop85Resistance 4912;
BA_ "SPN" SG_ 2633832958 SpecialIgnitorLoop86Resistance 4913;
BA_ "SPN" SG_ 2633832958 SpecialIgnitorLoop87Resistance 4914;
BA_ "SPN" SG_ 2633832958 SpecialIgnitorLoop88Resistance 4915;
BA_ "SPN" SG_ 2633832958 SpecialIgnitorLoop89Resistance 4916;
BA_ "SPN" SG_ 2633832958 SpecialIgnitorLoop8Resistance 4835;
BA_ "SPN" SG_ 2633832958 SpecialIgnitorLoop90Resistance 4917;
BA_ "SPN" SG_ 2633832958 SpecialIgnitorLoop9Resistance 4836;
BA_ "SPN" SG_ 2633853438 AdditionalAxleGroupLocation 5936;
BA_ "SPN" SG_ 2633853438 AxleGroupEmptyWeightCalibration 408;
BA_ "SPN" SG_ 2633853438 AxleGroupFullWeightCalibration 407;
BA_ "SPN" SG_ 2633853438 AxleGroupLocation 4074;
BA_ "SPN" SG_ 2633861886 J2012DTC 3620;
BA_ "SPN" SG_ 2633861886 J2012DTCOccurrenceCount 3622;
BA_ "SPN" SG_ 2633861886 J2012DTCStatus 3621;
BA_ "SPN" SG_ 2633861886 NumberofJ2012DTCs 3619;
BA_ "SPN" SG_ 2633869310 VltgRgltrLdCmpnstnMd 3375;
BA_ "SPN" SG_ 2633869310 VltgRgltrUndrfrqnCmpnstnnld 3377;
BA_ "SPN" SG_ 2633869310 VltgRgltrVArPwrFtrprtngmd 3376;
BA_ "SPN" SG_ 2633869310 VoltageRegulatorEnabled 3379;
BA_ "SPN" SG_ 2633869310 VoltageRegulatorSoftStartState 3378;
BA_ "SPN" SG_ 2633878014 TtlCntfCnfgrtnChngsMd 2887;
BA_ "SPN" SG_ 2633880062 FMSstandardDiagnosticsSupported 2804;
BA_ "SPN" SG_ 2633880062 FMSstandardRequestsSupported 2805;
BA_ "SPN" SG_ 2633880062 FMSstandardSWversionsupported 2806;
BA_ "SPN" SG_ 2633883646 FrontWheelDriveActuatorStatus 2612;
BA_ "SPN" SG_ 2633911806 EngineTotalAverageFuelEconomy 1835;
BA_ "SPN" SG_ 2633911806 EngineTotalAverageFuelRate 1834;
BA_ "SPN" SG_ 2633922558 AuxiliaryGagePressureReading1 137;
BA_ "SPN" SG_ 2633922558 AuxiliaryVacuumPressureReading 136;
BA_ "SPN" SG_ 2633922558 AxlrAsltPrssrRdng 138;
BA_ "SPN" SG_ 2633922814 DriveChannelMode 1468;
BA_ "SPN" SG_ 2633922814 PCUControlSolenoidStatus 1473;
BA_ "SPN" SG_ 2633922814 PCUDeflateSolenoidStatus 1472;
BA_ "SPN" SG_ 2633922814 PCUDriveSolenoidStatus 1469;
BA_ "SPN" SG_ 2633922814 PCUSteerSolenoidStatus 1470;
BA_ "SPN" SG_ 2633922814 PCUSupplySolenoidStatus 1474;
BA_ "SPN" SG_ 2633922814 PCUTrlrTgrPshSlndStts 1475;
BA_ "SPN" SG_ 2633922814 SteerChannelMode 1466;
BA_ "SPN" SG_ 2633922814 TirePressureCheckInterval 39;
BA_ "SPN" SG_ 2633922814 TirePressureSupplySwitchStatus 1471;
BA_ "SPN" SG_ 2633922814 TrailertagChannelMode 1467;
BA_ "SPN" SG_ 2633923070 DriveChannelTirePressureTarget 142;
BA_ "SPN" SG_ 2633923070 SteerChannelTirePressureTarget 143;
BA_ "SPN" SG_ 2633923070 TrlrTgOrPshChnnlTrPrssrTrgt 141;
BA_ "SPN" SG_ 2633923326 DriveChannelTirePressure 145;
BA_ "SPN" SG_ 2633923326 SteerChannelTirePressure 146;
BA_ "SPN" SG_ 2633923326 TrlrTgOrPshChnnlTrPrssr 144;
BA_ "SPN" SG_ 2633923582 EngineCylinder1CombustionTime 1444;
BA_ "SPN" SG_ 2633923582 EngineCylinder2CombustionTime 1445;
BA_ "SPN" SG_ 2633923582 EngineCylinder3CombustionTime 1446;
BA_ "SPN" SG_ 2633923582 EngineCylinder4CombustionTime 1447;
BA_ "SPN" SG_ 2633923838 EngineCylinder5CombustionTime 1448;
BA_ "SPN" SG_ 2633923838 EngineCylinder6CombustionTime 1449;
BA_ "SPN" SG_ 2633923838 EngineCylinder7CombustionTime 1450;
BA_ "SPN" SG_ 2633923838 EngineCylinder8CombustionTime 1451;
BA_ "SPN" SG_ 2633924094 EngineCylinder10CombustionTime 1453;
BA_ "SPN" SG_ 2633924094 EngineCylinder11CombustionTime 1454;
BA_ "SPN" SG_ 2633924094 EngineCylinder12CombustionTime 1455;
BA_ "SPN" SG_ 2633924094 EngineCylinder9CombustionTime 1452;
BA_ "SPN" SG_ 2633924350 EngineCylinder13CombustionTime 1456;
BA_ "SPN" SG_ 2633924350 EngineCylinder14CombustionTime 1457;
BA_ "SPN" SG_ 2633924350 EngineCylinder15CombustionTime 1458;
BA_ "SPN" SG_ 2633924350 EngineCylinder16CombustionTime 1459;
BA_ "SPN" SG_ 2633924606 EngineCylinder17CombustionTime 1460;
BA_ "SPN" SG_ 2633924606 EngineCylinder18CombustionTime 1461;
BA_ "SPN" SG_ 2633924606 EngineCylinder19CombustionTime 1462;
BA_ "SPN" SG_ 2633924606 EngineCylinder20CombustionTime 1463;
BA_ "SPN" SG_ 2633924862 EngineAverageCombustionTime 1465;
BA_ "SPN" SG_ 2633924862 EngineDesiredCombustionTime 1464;
BA_ "SPN" SG_ 2633925118 EngineFuelFlowRate1 1440;
BA_ "SPN" SG_ 2633925118 EngineFuelFlowRate2 1441;
BA_ "SPN" SG_ 2633925118 EngineFuelValve1Position 1442;
BA_ "SPN" SG_ 2633925118 EngineFuelValve2Position 1443;
BA_ "SPN" SG_ 2633925118 EngnFlVlv1CmmnddPstn 1765;
BA_ "SPN" SG_ 2633925118 EngnFlVlv2CmmnddPstn 1766;
BA_ "SPN" SG_ 2633925374 EngineCylinder1IgnitionTiming 1413;
BA_ "SPN" SG_ 2633925374 EngineCylinder2IgnitionTiming 1414;
BA_ "SPN" SG_ 2633925374 EngineCylinder3IgnitionTiming 1415;
BA_ "SPN" SG_ 2633925374 EngineCylinder4IgnitionTiming 1416;
BA_ "SPN" SG_ 2633925630 EngineCylinder5IgnitionTiming 1417;
BA_ "SPN" SG_ 2633925630 EngineCylinder6IgnitionTiming 1418;
BA_ "SPN" SG_ 2633925630 EngineCylinder7IgnitionTiming 1419;
BA_ "SPN" SG_ 2633925630 EngineCylinder8IgnitionTiming 1420;
BA_ "SPN" SG_ 2633925886 EngineCylinder10IgnitionTiming 1422;
BA_ "SPN" SG_ 2633925886 EngineCylinder11IgnitionTiming 1423;
BA_ "SPN" SG_ 2633925886 EngineCylinder12IgnitionTiming 1424;
BA_ "SPN" SG_ 2633925886 EngineCylinder9IgnitionTiming 1421;
BA_ "SPN" SG_ 2633926142 EngineCylinder13IgnitionTiming 1425;
BA_ "SPN" SG_ 2633926142 EngineCylinder14IgnitionTiming 1426;
BA_ "SPN" SG_ 2633926142 EngineCylinder15IgnitionTiming 1427;
BA_ "SPN" SG_ 2633926142 EngineCylinder16IgnitionTiming 1428;
BA_ "SPN" SG_ 2633926398 EngineCylinder17IgnitionTiming 1429;
BA_ "SPN" SG_ 2633926398 EngineCylinder18IgnitionTiming 1430;
BA_ "SPN" SG_ 2633926398 EngineCylinder19IgnitionTiming 1431;
BA_ "SPN" SG_ 2633926398 EngineCylinder20IgnitionTiming 1432;
BA_ "SPN" SG_ 2633926654 EngineActualIgnitionTiming 1436;
BA_ "SPN" SG_ 2633926654 EngineDesiredIgnitionTiming1 1433;
BA_ "SPN" SG_ 2633926654 EngineDesiredIgnitionTiming2 1434;
BA_ "SPN" SG_ 2633926654 EngineDesiredIgnitionTiming3 1435;
BA_ "SPN" SG_ 2633926910 EngnClndr1IgntnTrnsfrmrSndrOtpt 1393;
BA_ "SPN" SG_ 2633926910 EngnClndr2IgntnTrnsfrmrSndrOtpt 1394;
BA_ "SPN" SG_ 2633926910 EngnClndr3IgntnTrnsfrmrSndrOtpt 1395;
BA_ "SPN" SG_ 2633926910 EngnClndr4IgntnTrnsfrmrSndrOtpt 1396;
BA_ "SPN" SG_ 2633926910 EngnClndr5IgntnTrnsfrmrSndrOtpt 1397;
BA_ "SPN" SG_ 2633926910 EngnClndr6IgntnTrnsfrmrSndrOtpt 1398;
BA_ "SPN" SG_ 2633926910 EngnClndr7IgntnTrnsfrmrSndrOtpt 1399;
BA_ "SPN" SG_ 2633926910 EngnClndr8IgntnTrnsfrmrSndrOtpt 1400;
BA_ "SPN" SG_ 2633927166 ECd10ItTsSdOtpt 1402;
BA_ "SPN" SG_ 2633927166 ECd11ItTsSdOtpt 1403;
BA_ "SPN" SG_ 2633927166 ECd12ItTsSdOtpt 1404;
BA_ "SPN" SG_ 2633927166 ECd13ItTsSdOtpt 1405;
BA_ "SPN" SG_ 2633927166 ECd14ItTsSdOtpt 1406;
BA_ "SPN" SG_ 2633927166 ECd15ItTsSdOtpt 1407;
BA_ "SPN" SG_ 2633927166 ECd16ItTsSdOtpt 1408;
BA_ "SPN" SG_ 2633927166 EngnClndr9IgntnTrnsfrmrSndrOtpt 1401;
BA_ "SPN" SG_ 2633927422 ECd17ItTsSdOtpt 1409;
BA_ "SPN" SG_ 2633927422 ECd18ItTsSdOtpt 1410;
BA_ "SPN" SG_ 2633927422 ECd19ItTsSdOtpt 1411;
BA_ "SPN" SG_ 2633927422 ECd20ItTsSdOtpt 1412;
BA_ "SPN" SG_ 2633927678 EngnArtFlDffrntlPrssr 1392;
BA_ "SPN" SG_ 2633927678 EngnFlVlv1DffrntlPrssr 1391;
BA_ "SPN" SG_ 2633927678 EngnFlVlv1IntkAsltPrssr 1390;
BA_ "SPN" SG_ 2633927678 EngnFlVlv1OtltAsltPrssr 2980;
BA_ "SPN" SG_ 2633927934 AuxiliaryLevel 3087;
BA_ "SPN" SG_ 2633927934 AuxiliaryPressure1 1387;
BA_ "SPN" SG_ 2633927934 AuxiliaryPressure2 1388;
BA_ "SPN" SG_ 2633927934 AuxiliaryTemperature1 441;
BA_ "SPN" SG_ 2633927934 AuxiliaryTemperature2 442;
BA_ "SPN" SG_ 2633927934 RelativeHumidity 354;
BA_ "SPN" SG_ 2633928446 ServiceComponentIdentification 1379;
BA_ "SPN" SG_ 2633928446 TimeSinceLastService 1350;
BA_ "SPN" SG_ 2633929214 EngineFluidBundLevel 7785;
BA_ "SPN" SG_ 2633929214 EngineFuelLeakage1 1239;
BA_ "SPN" SG_ 2633929214 EngineFuelLeakage2 1240;
BA_ "SPN" SG_ 2633929470 EngineExhaustPressure1 1209;
BA_ "SPN" SG_ 2633929470 EngineFuelRackPosition 1210;
BA_ "SPN" SG_ 2633929470 EngineOilFilterIntakePressure 1208;
BA_ "SPN" SG_ 2633929470 EngnFlSstm1GsMssFlwRt 1241;
BA_ "SPN" SG_ 2633929470 InstntnsEstmtdBrkPwr 1242;
BA_ "SPN" SG_ 2633929726 ElectricalLoad 1204;
BA_ "SPN" SG_ 2633929726 EngineTurningGearEngaged 1206;
BA_ "SPN" SG_ 2633929726 SafetyWireStatus 1205;
BA_ "SPN" SG_ 2633930238 EngineOperationTimeSinceRebuild 1193;
BA_ "SPN" SG_ 2633931774 EngineTurbocharger2Speed 1169;
BA_ "SPN" SG_ 2633931774 EngineTurbocharger3Speed 1170;
BA_ "SPN" SG_ 2633931774 EngineTurbocharger4Speed 1171;
BA_ "SPN" SG_ 2633931774 EngnTrhrgrLOlPrssr2 1168;
BA_ "SPN" SG_ 2633932798 EngnExhstGsPrt17Tmprtr 1153;
BA_ "SPN" SG_ 2633932798 EngnExhstGsPrt18Tmprtr 1154;
BA_ "SPN" SG_ 2633932798 EngnExhstGsPrt19Tmprtr 1155;
BA_ "SPN" SG_ 2633932798 EngnExhstGsPrt20Tmprtr 1156;
BA_ "SPN" SG_ 2633933310 EngnExhstGsPrt10Tmprtr 1146;
BA_ "SPN" SG_ 2633933310 EngnExhstGsPrt11Tmprtr 1147;
BA_ "SPN" SG_ 2633933310 EngnExhstGsPrt12Tmprtr 1148;
BA_ "SPN" SG_ 2633933310 EngnExhstGsPrt9Tmprtr 1145;
BA_ "SPN" SG_ 2633933566 EngnExhstGsPrt5Tmprtr 1141;
BA_ "SPN" SG_ 2633933566 EngnExhstGsPrt6Tmprtr 1142;
BA_ "SPN" SG_ 2633933566 EngnExhstGsPrt7Tmprtr 1143;
BA_ "SPN" SG_ 2633933566 EngnExhstGsPrt8Tmprtr 1144;
BA_ "SPN" SG_ 2633933822 EngnExhstGsPrt1Tmprtr 1137;
BA_ "SPN" SG_ 2633933822 EngnExhstGsPrt2Tmprtr 1138;
BA_ "SPN" SG_ 2633933822 EngnExhstGsPrt3Tmprtr 1139;
BA_ "SPN" SG_ 2633933822 EngnExhstGsPrt4Tmprtr 1140;
BA_ "SPN" SG_ 2633934334 EngnIntkMnfld2Tmprtr 1131;
BA_ "SPN" SG_ 2633934334 EngnIntkMnfld3Tmprtr 1132;
BA_ "SPN" SG_ 2633934334 EngnIntkMnfld4Tmprtr 1133;
BA_ "SPN" SG_ 2633934334 EngnIntkMnfld5Tmprtr 1802;
BA_ "SPN" SG_ 2633934334 EngnIntkMnfld6Tmprtr 1803;
BA_ "SPN" SG_ 2633934846 EngnAltrntrBrng1Tmprtr 1122;
BA_ "SPN" SG_ 2633934846 EngnAltrntrBrng2Tmprtr 1123;
BA_ "SPN" SG_ 2633934846 EngnAltrntrWndng1Tmprtr 1124;
BA_ "SPN" SG_ 2633934846 EngnAltrntrWndng2Tmprtr 1125;
BA_ "SPN" SG_ 2633934846 EngnAltrntrWndng3Tmprtr 1126;
BA_ "SPN" SG_ 2633934846 EngnAltrntrWndng4Tmprtr 8463;
BA_ "SPN" SG_ 2633934846 EngnAltrntrWndng5Tmprtr 8464;
BA_ "SPN" SG_ 2633934846 EngnAltrntrWndng6Tmprtr 8465;
BA_ "SPN" SG_ 2633935102 ArticulationAngle 1120;
BA_ "SPN" SG_ 2633935102 ArticulationAngularVelocity 9652;
BA_ "SPN" SG_ 2633935358 EngineActualExhaust1Oxygen 1119;
BA_ "SPN" SG_ 2633935358 EngineDesiredExhaustOxygen 1118;
BA_ "SPN" SG_ 2633935358 EngineDesiredRatedExhaustOxygen 1117;
BA_ "SPN" SG_ 2633935358 EngnExhstO2SnsrClsdLpOprtn 1696;
BA_ "SPN" SG_ 2633935358 EngnExhstO2SnsrFlngCrrtn 1695;
BA_ "SPN" SG_ 2633935614 EFSstGsMssFwRtSsFCt 1694;
BA_ "SPN" SG_ 2633935614 EngnIntkMnfldDsrdAsltPrssr 1692;
BA_ "SPN" SG_ 2633935614 EngnTrhrgrWstgtVlvPstn 1693;
BA_ "SPN" SG_ 2633935614 GaseousFuelCorrectionFactor 1116;
BA_ "SPN" SG_ 2633935614 GssFlInjtnPlsCrrtnFtr 6649;
BA_ "SPN" SG_ 2633935870 ClutchLifeRemaining 2983;
BA_ "SPN" SG_ 2633935870 HighestPossibleGear 1115;
BA_ "SPN" SG_ 2633935870 LowestPossibleGear 1114;
BA_ "SPN" SG_ 2633935870 RecommendedGear 1113;
BA_ "SPN" SG_ 2633936126 BrkLnngRmnngFrntAxlLftWhl 1099;
BA_ "SPN" SG_ 2633936126 BrkLnngRmnngFrntAxlRghtWhl 1100;
BA_ "SPN" SG_ 2633936126 BrkLnngRmnngRrAxl1LftWhl 1101;
BA_ "SPN" SG_ 2633936126 BrkLnngRmnngRrAxl1RghtWhl 1102;
BA_ "SPN" SG_ 2633936126 BrkLnngRmnngRrAxl2LftWhl 1103;
BA_ "SPN" SG_ 2633936126 BrkLnngRmnngRrAxl2RghtWhl 1104;
BA_ "SPN" SG_ 2633936126 BrkLnngRmnngRrAxl3LftWhl 1105;
BA_ "SPN" SG_ 2633936126 BrkLnngRmnngRrAxl3RghtWhl 1106;
BA_ "SPN" SG_ 2633936894 TotalFuelUsedGaseous 1040;
BA_ "SPN" SG_ 2633936894 TripFuelGaseous 1039;
BA_ "SPN" SG_ 2633937150 TripAirCompressorOnTime 1038;
BA_ "SPN" SG_ 2633937150 TripCruiseTime 1034;
BA_ "SPN" SG_ 2633937150 TripEngineRunningTime 1036;
BA_ "SPN" SG_ 2633937150 TripIdleTime 1037;
BA_ "SPN" SG_ 2633937150 TripPTOGovernorTime 1035;
BA_ "SPN" SG_ 2633937406 TotalECUDistance 1032;
BA_ "SPN" SG_ 2633937406 TotalECURunTime 1033;
BA_ "SPN" SG_ 2633937662 EngineFuelSpecificGravity 1389;
BA_ "SPN" SG_ 2633937662 TripAverageFuelRateGaseous 1031;
BA_ "SPN" SG_ 2633937662 TtlEngnPTOGvrnrFlUsdGss 1030;
BA_ "SPN" SG_ 2633937918 FlexibleFuelPercentage 5458;
BA_ "SPN" SG_ 2633937918 TotalEnginePTOGovernorFuelUsed 1028;
BA_ "SPN" SG_ 2633937918 TripAverageFuelRate 1029;
BA_ "SPN" SG_ 2633938174 TripTimeinDeratebyEngine 1027;
BA_ "SPN" SG_ 2633938174 TripTimeinGearDown 1026;
BA_ "SPN" SG_ 2633938174 TripTimeinTopGear 1025;
BA_ "SPN" SG_ 2633938174 TripTimeinVSL 1024;
BA_ "SPN" SG_ 2633938430 TripNumberofHotShutdowns 1020;
BA_ "SPN" SG_ 2633938430 TripNumberofIdleShutdowns 1021;
BA_ "SPN" SG_ 2633938430 TripSuddenDecelerations 1023;
BA_ "SPN" SG_ 2633938430 TrpNmrfIdlShtdwnOvrrds 1022;
BA_ "SPN" SG_ 2633938686 TripCruiseDistance 1019;
BA_ "SPN" SG_ 2633938686 TripMaximumVehicleSpeed 1018;
BA_ "SPN" SG_ 2633938942 TotalDriveAverageLoadFactor 1016;
BA_ "SPN" SG_ 2633938942 TotalEngineCruiseTime 1017;
BA_ "SPN" SG_ 2633938942 TripAverageEngineSpeed 1014;
BA_ "SPN" SG_ 2633938942 TripDriveAverageLoadFactor 1015;
BA_ "SPN" SG_ 2633938942 TripMaximumEngineSpeed 1013;
BA_ "SPN" SG_ 2633939198 TripCruiseFuelUsedGaseous 1011;
BA_ "SPN" SG_ 2633939198 TripDriveFuelEconomyGaseous 1012;
BA_ "SPN" SG_ 2633939198 TripDriveFuelUsedGaseous 1007;
BA_ "SPN" SG_ 2633939198 TripVehicleIdleFuelUsedGaseous 1010;
BA_ "SPN" SG_ 2633939198 TrpPTOGvrnrMvngFlUsdGss 1008;
BA_ "SPN" SG_ 2633939198 TrpPTOGvrnrNnmvngFlUsdGss 1009;
BA_ "SPN" SG_ 2633939454 TripCruiseFuelUsed 1005;
BA_ "SPN" SG_ 2633939454 TripDriveFuelEconomy 1006;
BA_ "SPN" SG_ 2633939454 TripDriveFuelUsed 1001;
BA_ "SPN" SG_ 2633939454 TripPTOGovernorMovingFuelUsed 1002;
BA_ "SPN" SG_ 2633939454 TripVehicleIdleFuelUsed 1004;
BA_ "SPN" SG_ 2633939454 TrpPTOGvrnrNnmvngFlUsd 1003;
BA_ "SPN" SG_ 2633939710 TripDistanceinTopGear 1000;
BA_ "SPN" SG_ 2633939710 TripDistanceonVSL 998;
BA_ "SPN" SG_ 2633939710 TripGearDownDistance 999;
BA_ "SPN" SG_ 2633939966 TripFanOnTime 994;
BA_ "SPN" SG_ 2633939966 TripFanOnTimeDuetoaManualSwitch 996;
BA_ "SPN" SG_ 2633939966 TripFanOnTimeDuetotheACSystem 997;
BA_ "SPN" SG_ 2633939966 TrpFnOnTmDtthEngnSstm 995;
BA_ "SPN" SG_ 2633940222 TotalCompressionBrakeDistance 990;
BA_ "SPN" SG_ 2633940222 TripCompressionBrakeDistance 991;
BA_ "SPN" SG_ 2633940222 TripServiceBrakeApplications 993;
BA_ "SPN" SG_ 2633940222 TripServiceBrakeDistance 992;
BA_ "SPN" SG_ 2633940734 CrnkAttmptCntnPrsntStrtAttmpt 3671;
BA_ "SPN" SG_ 2633940734 EngineRatedPower 166;
BA_ "SPN" SG_ 2633940734 EngineRatedSpeed 189;
BA_ "SPN" SG_ 2633940734 EngineRotationDirection 3669;
BA_ "SPN" SG_ 2633940734 EngnIntkMnfldPrssrCntrlMd 5465;
BA_ "SPN" SG_ 2633940734 EngnPrlOlLwPrssrThrshld 8622;
BA_ "SPN" SG_ 2633941758 CrsCntrlRtrdrAtvSpdOffst 7496;
BA_ "SPN" SG_ 2633941758 TransmissionOutputRetarder 748;
BA_ "SPN" SG_ 2633942014 TransmissionLowRangeSenseSwitch 779;
BA_ "SPN" SG_ 2633942014 TransmissionNeutralSwitch 604;
BA_ "SPN" SG_ 2633942014 TrnsmssnFrwrdDrtnSwth 903;
BA_ "SPN" SG_ 2633942014 TrnsmssnHghRngSnsSwth 778;
BA_ "SPN" SG_ 2633942014 TrnsmssnRvrsDrtnSwth 767;
BA_ "SPN" SG_ 2633942014 TransmissionSplitterPosition 32;
BA_ "SPN" SG_ 2633942526 TrnsmssnSnhrnzrBrkVl 54;
BA_ "SPN" SG_ 2633942526 TrnsmssnSnhrnzrClthVl 53;
BA_ "SPN" SG_ 2633943038 TransmissionClutchActuator 788;
BA_ "SPN" SG_ 2633943038 TransmissionDefuelActuator 786;
BA_ "SPN" SG_ 2633943038 TransmissionRangeHighActuator 768;
BA_ "SPN" SG_ 2633943038 TransmissionRangeLowActuator 769;
BA_ "SPN" SG_ 2633943038 TrnsmssnInrtBrkAttr 787;
BA_ "SPN" SG_ 2633943038 TrnsmssnShftFngrCntrRlIndtr 782;
BA_ "SPN" SG_ 2633943038 TrnsmssnShftFngrEnggmntIndtr 781;
BA_ "SPN" SG_ 2633943038 TrnsmssnShftFngrGrAttr1 773;
BA_ "SPN" SG_ 2633943038 TrnsmssnShftFngrGrAttr2 784;
BA_ "SPN" SG_ 2633943038 TrnsmssnShftFngrGrPstn 59;
BA_ "SPN" SG_ 2633943038 TrnsmssnShftFngrNtrlIndtr 780;
BA_ "SPN" SG_ 2633943038 TrnsmssnShftFngrRlAttr1 772;
BA_ "SPN" SG_ 2633943038 TrnsmssnShftFngrRlAttr2 783;
BA_ "SPN" SG_ 2633943038 TrnsmssnShftFngrRlPstn 60;
BA_ "SPN" SG_ 2633943038 TrnsmssnSplttrDrtAttr 770;
BA_ "SPN" SG_ 2633943038 TrnsmssnSplttrIndrtAttr 771;
BA_ "SPN" SG_ 2633943038 TrnsmssnTrqCnvrtrLkpClthAttr 740;
BA_ "SPN" SG_ 2565865726 ActualRetarderPercentTorque 520;
BA_ "SPN" SG_ 2565865726 AtlMxmmAvllRtrdrPrntTrq 1717;
BA_ "SPN" SG_ 2565865726 DrvrsDmndRtrdrPrntTrq 1715;
BA_ "SPN" SG_ 2565865726 EngineCoolantLoadIncrease 1082;
BA_ "SPN" SG_ 2565865726 IntendedRetarderPercentTorque 1085;
BA_ "SPN" SG_ 2565865726 RetarderEnableBrakeAssistSwitch 571;
BA_ "SPN" SG_ 2565865726 RetarderEnableShiftAssistSwitch 572;
BA_ "SPN" SG_ 2565865726 RetarderRequestingBrakeLight 1667;
BA_ "SPN" SG_ 2565865726 RetarderRoadSpeedExceededStatus 4234;
BA_ "SPN" SG_ 2565865726 RetarderRoadSpeedLimitSwitch 4233;
BA_ "SPN" SG_ 2565865726 RetarderSelectionnonengine 1716;
BA_ "SPN" SG_ 2565865726 RetarderTorqueMode 900;
BA_ "SPN" SG_ 2565865726 SrAddrssfCntrllngDvfrRtrdrCntrl 1480;
BA_ "SPN" SG_ 2499608830 EngineCoolantPressure2 5708;
BA_ "SPN" SG_ 2499608830 EngnExhstGsRrltn2DffrntlPrssr 5252;
BA_ "SPN" SG_ 2499608830 EngnExhstGsRrltn2IntkAsltPrssr 5429;
BA_ "SPN" SG_ 2499608830 EngnExhstGsRrltn2IntkPrssr 5253;
BA_ "SPN" SG_ 2499608830 EngnExhstGsRrltn2OtltAsltPrssr 5254;
BA_ "SPN" SG_ 2365456638 GeneratorPhaseBACFrequency 2438;
BA_ "SPN" SG_ 2365456638 GeneratorPhaseBACRMSCurrent 2450;
BA_ "SPN" SG_ 2365456638 GnrtrPhsBCLnLnACRMSVltg 2442;
BA_ "SPN" SG_ 2365456638 GnrtrPhsBLnNtrlACRMSVltg 2446;
BA_ "SPN" SG_ 2351365886 MtrGnrtr1InvrtrCntrlCRC 10157;
BA_ "SPN" SG_ 2351365886 MtrGnrtr1InvrtrCntrlCntr 10158;
BA_ "SPN" SG_ 2351365886 MtGt1IvtCtLtsRqstOvdMd 10159;
BA_ "SPN" SG_ 2351365886 MtrGnrtr1InvrtrCntrlStpntMdRqst 10162;
BA_ "SPN" SG_ 2351365886 MtrGnrtr1InvrtrCntrlStpntRqst 10163;
BA_ "SPN" SG_ 2351431422 MtrGnrtr2InvrtrCntrlCRC 10223;
BA_ "SPN" SG_ 2351431422 MtrGnrtr2InvrtrCntrlCntr 10224;
BA_ "SPN" SG_ 2351431422 MtGt2IvtCtLtsRqstOvdMd 10225;
BA_ "SPN" SG_ 2351431422 MtrGnrtr2InvrtrCntrlStpntMdRqst 10228;
BA_ "SPN" SG_ 2351431422 MtrGnrtr2InvrtrCntrlStpntRqst 10229;
BA_ "SPN" SG_ 2556165886 MtrGnrtr2InvrtrLmtsRqstPwrCRC 10242;
BA_ "SPN" SG_ 2556165886 MtrGnrtr2InvrtrLmtsRqstPwrCntr 10243;
BA_ "SPN" SG_ 2556231422 MtrGnrtr2InvrtrLmtsRqstMhnlCRC 10254;
BA_ "SPN" SG_ 2556231422 MtrGnrtr2InvrtrLmtsRqstMhnlCntr 10255;
BA_ "SPN" SG_ 2556296958 MtrGnrtr2InvrtrLmtsRqstDCSdCRC 10270;
BA_ "SPN" SG_ 2556296958 MtrGnrtr2InvrtrLmtsRqstDCSdCntr 10271;
BA_ "SPN" SG_ 2556362494 MtrGnrtr1InvrtrLmtsRqstDCSdCRC 10204;
BA_ "SPN" SG_ 2556362494 MtrGnrtr1InvrtrLmtsRqstDCSdCntr 10205;
BA_ "SPN" SG_ 2556428030 MtrGnrtr1InvrtrLmtsRqstMhnlCRC 10188;
BA_ "SPN" SG_ 2556428030 MtrGnrtr1InvrtrLmtsRqstMhnlCntr 10189;
